VERSION ""

NS_ :

BS_:

BU_: AFLS CUbiS SAS SCC ACU ECS IPM LCA MDPS SMK SPAS ESC FPCM LDWS ODS SNV TCU TESTER TMU OPI RPAS YRS ABS DATC LKAS AAF EMS ISS REA _4WD CLU DI_BOX EHPS EPB EVP HUD LVR PSB_RH TPMS AHLS FATC LPI PAS PSB_LH AEMC AVM BCM CLOCK E_Shifter ISG MTC MTS PGS PSB TCS AAF_Tester LDWS_Test_Tool

BO_ 2015 GST1: 8 TESTER
 SG_ REQ_RESPONSE : 16|8@1+ (1,0) [0|2] ""  _4WD,AAF,ABS,ACU,AEMC,AFLS,AHLS,AVM,BCM,CLOCK,CLU,CUbiS,DATC,DI_BOX,ECS,EHPS,EMS,EPB,ESC,EVP,E_Shifter,FATC,IPM,ISG,ISS,LCA,LDWS,LKAS,LPI,LVR,MDPS,MTC,MTS,ODS,OPI,PAS,PGS,PSB,PSB_LH,PSB_RH,REA,RPAS,SAS,SCC,SMK,SNV,SPAS,TCS,TCU,TMU,TPMS,YRS
 SG_ SID : 8|8@1+ (1,0) [0|255] ""  _4WD,AAF,ABS,ACU,AEMC,AFLS,AHLS,AVM,BCM,CLOCK,CLU,CUbiS,DATC,DI_BOX,ECS,EHPS,EMS,EPB,ESC,EVP,E_Shifter,FATC,IPM,ISG,ISS,LCA,LDWS,LKAS,LPI,LVR,MDPS,MTC,MTS,ODS,OPI,PAS,PGS,PSB,PSB_LH,PSB_RH,REA,RPAS,SAS,SCC,SMK,SNV,SPAS,TCS,TCU,TMU,TPMS,YRS
 SG_ FRM_FORMAT : 0|8@1+ (1,0) [0|31] ""  _4WD,AAF,ABS,ACU,AEMC,AFLS,AHLS,AVM,BCM,CLOCK,CLU,CUbiS,DATC,DI_BOX,ECS,EHPS,EMS,EPB,ESC,EVP,E_Shifter,FATC,IPM,ISG,ISS,LCA,LDWS,LKAS,LPI,LVR,MDPS,MTC,MTS,ODS,OPI,PAS,PGS,PSB,PSB_LH,PSB_RH,REA,RPAS,SAS,SCC,SMK,SNV,SPAS,TCS,TCU,TMU,TPMS,YRS

BO_ 1984 CAL_SAS: 2 ESC
 SG_ CCW : 0|4@1+ (1,0) [0|15] ""  SAS
 SG_ SAS_CID : 4|11@1+ (1,0) [0|2047] ""  SAS

BO_ 1680 CLU2: 8 IPM
 SG_ IGN_SW : 0|3@1+ (1,0) [0|7] ""  ECS,EPB
 SG_ CF_Clu_FlexStrgModeSwi : 58|2@1+ (1,0) [0|3] ""  MDPS
 SG_ PIC_Lock : 10|3@1+ (1,0) [0|7] ""  ECS
 SG_ AST_DR_SW : 54|2@1+ (1,0) [0|3] ""  AVM
 SG_ DRV_DR_SW : 6|2@1+ (1,0) [0|3] ""  ECS,EPB,ESC,TCU
 SG_ PIC_Unlock : 13|3@1+ (1,0) [0|7] ""  ECS
 SG_ CF_HoodStat : 22|2@1+ (1,0) [0|3] ""  EMS,EPB
 SG_ CF_SWL_Stat : 45|3@1+ (1,0) [0|7] ""  ACU
 SG_ DRV_Key_Lock : 8|1@1+ (1,0) [0|1] ""  ECS
 SG_ DRV_Seat_Belt : 16|2@1+ (1,0) [0|3] ""  EPB,ESC,MTS,PSB_LH,PSB_RH,TCU,TMU
 SG_ PAS_Seat_Belt : 20|2@1+ (1,0) [0|3] ""  MTS,PSB_LH,PSB_RH,TMU
 SG_ DRV_Key_Unlock : 9|1@1+ (1,0) [0|1] ""  ECS
 SG_ CF_Clu_HazardSW : 49|1@1+ (1,0) [0|1] ""  ABS,EMS
 SG_ CF_Clu_SwiGearR : 43|2@1+ (1,0) [0|3] ""  EMS,EPB,SPAS
 SG_ CF_Clu_WiperLow : 31|1@1+ (1,0) [0|1] ""  LDWS,LKAS
 SG_ CF_Clu_AliveCnt2 : 50|4@1+ (1,0) [0|15] ""  EMS
 SG_ CF_Clu_TurnSigLh : 24|1@1+ (1,0) [0|1] ""  LDWS,LKAS
 SG_ CF_Clu_TurnSigRh : 25|1@1+ (1,0) [0|1] ""  LDWS,LKAS
 SG_ CF_Clu_WiperAuto : 33|1@1+ (1,0) [0|1] ""  LDWS,LKAS
 SG_ CF_Clu_WiperHigh : 32|1@1+ (1,0) [0|1] ""  LDWS,LKAS
 SG_ CF_Clu_WiperIntT : 27|3@1+ (1,0) [0|7] ""  LDWS,LKAS
 SG_ CF_Clu_AltLStatus : 39|1@1+ (1,0) [0|1] ""  DATC,FATC,MTC
 SG_ CF_Clu_LdwsLkasSW : 26|1@1+ (1,0) [0|1] ""  LDWS,LKAS
 SG_ CF_Clu_WiperIntSW : 30|1@1+ (1,0) [0|1] ""  LDWS,LKAS
 SG_ TRUNK_OPEN_STATUS : 18|2@1+ (1,0) [0|3] ""  AFLS,ECS
 SG_ CF_Clu_ActiveEcoSW : 48|1@1+ (1,0) [0|1] ""  DATC,FATC,MTC,TCU
 SG_ CF_Clu_EcoDriveInf : 40|3@1+ (1,0) [0|7] ""  CUbiS,MTS,TMU
 SG_ CF_Clu_HeadLampLow : 37|1@1+ (1,0) [0|1] ""  AFLS,EMS,LDWS
 SG_ CF_Clu_RainSnsStat : 34|3@1+ (1,0) [0|7] ""  LDWS,LKAS
 SG_ CF_Clu_HeadLampHigh : 38|1@1+ (1,0) [0|1] ""  EMS
 SG_ CF_Clu_LkasDispMode : 56|2@1+ (1,0) [0|3] ""  LKAS
 SG_ RKE_CMD : 3|3@1+ (1,0) [0|7] ""  ECS

BO_ 1616 AFLS: 2 AFLS
 SG_ CF_Afls_LedHLStat : 8|2@1+ (1,0) [0|3] ""  CLU
 SG_ AFLS_STAT : 1|2@1+ (1,0) [0|3] ""  CLU
 SG_ CF_Afls_TrfChgStat : 3|1@1+ (1,0) [0|1] ""  CLU

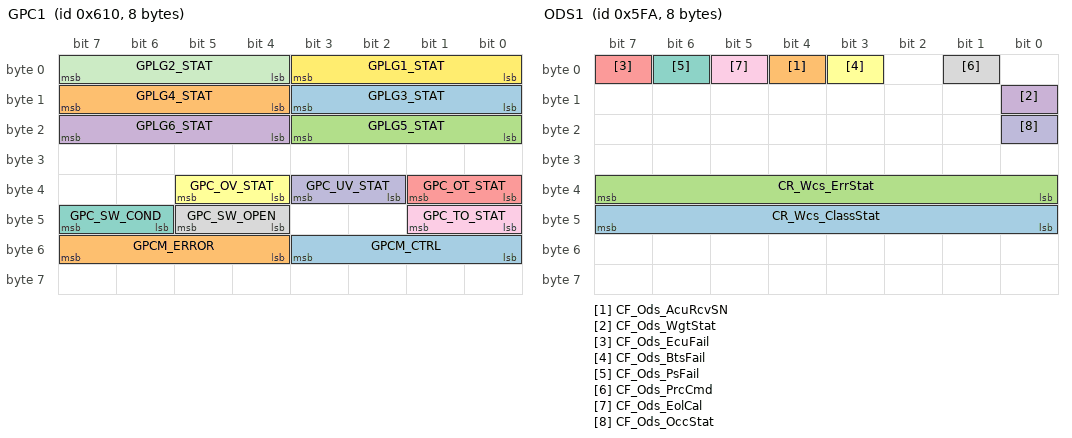
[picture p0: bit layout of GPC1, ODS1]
BO_ 1552 GPC1: 8 ISS
 SG_ GPLG3_STAT : 8|4@1+ (1,0) [0|15] ""  EMS
 SG_ GPLG4_STAT : 12|4@1+ (1,0) [0|15] ""  EMS
 SG_ GPLG5_STAT : 16|4@1+ (1,0) [0|15] ""  EMS
 SG_ GPLG6_STAT : 20|4@1+ (1,0) [0|15] ""  EMS
 SG_ GPC_OT_STAT : 32|2@1+ (1,0) [0|3] ""  EMS
 SG_ GPC_OV_STAT : 36|2@1+ (1,0) [0|3] ""  EMS
 SG_ GPC_SW_COND : 46|2@1+ (1,0) [0|3] ""  EMS
 SG_ GPC_SW_OPEN : 44|2@1+ (1,0) [0|3] ""  EMS
 SG_ GPC_TO_STAT : 40|2@1+ (1,0) [0|3] ""  EMS
 SG_ GPC_UV_STAT : 34|2@1+ (1,0) [0|3] ""  EMS
 SG_ GPLG2_STAT : 4|4@1+ (1,0) [0|15] ""  EMS
 SG_ GPLG1_STAT : 0|4@1+ (1,0) [0|15] ""  EMS
 SG_ GPCM_CTRL : 48|4@1+ (1,0) [0|15] ""  EMS
 SG_ GPCM_ERROR : 52|4@1+ (1,0) [0|15] ""  EMS

BO_ 1532 ODS3: 5 ODS
 SG_ CR_Ods_ID : 0|8@1+ (1,0) [0|255] ""  ACU
 SG_ CR_Ods_RomID_L : 32|8@1+ (1,0) [0|255] ""  ACU
 SG_ CR_Ods_RomID_H : 24|8@1+ (1,0) [0|255] ""  ACU
 SG_ CR_Ods_Chksum_H : 8|8@1+ (1,0) [0|255] ""  ACU
 SG_ CR_Ods_Chksum_L : 16|8@1+ (1,0) [0|255] ""  ACU

BO_ 1531 ODS2: 8 ODS
 SG_ CR_Ods_SerNum7 : 56|8@1+ (1,0) [0|255] ""  ACU
 SG_ CR_Ods_SerNum2 : 16|8@1+ (1,0) [0|255] ""  ACU
 SG_ CR_Ods_SerNum1 : 8|8@1+ (1,0) [0|255] ""  ACU
 SG_ CR_Ods_SerNum0 : 0|8@1+ (1,0) [0|255] ""  ACU
 SG_ CR_Ods_SerNum6 : 48|8@1+ (1,0) [0|255] ""  ACU
 SG_ CR_Ods_SerNum5 : 40|8@1+ (1,0) [0|255] ""  ACU
 SG_ CR_Ods_SerNum4 : 32|8@1+ (1,0) [0|255] ""  ACU
 SG_ CR_Ods_SerNum3 : 24|8@1+ (1,0) [0|255] ""  ACU

BO_ 1530 ODS1: 8 ODS
 SG_ CR_Wcs_ClassStat : 40|8@1+ (1,0) [0|4] ""  ACU
 SG_ CF_Ods_AcuRcvSN : 4|1@1+ (1,0) [0|1] ""  ACU
 SG_ CR_Wcs_ErrStat : 32|8@1+ (1,0) [0|63] ""  ACU
 SG_ CF_Ods_WgtStat : 8|1@1+ (1,0) [0|1] ""  ACU
 SG_ CF_Ods_EcuFail : 7|1@1+ (1,0) [0|1] ""  ACU
 SG_ CF_Ods_BtsFail : 3|1@1+ (1,0) [0|1] ""  ACU
 SG_ CF_Ods_PsFail : 6|1@1+ (1,0) [0|1] ""  ACU
 SG_ CF_Ods_PrcCmd : 1|1@1+ (1,0) [0|1] ""  ACU
 SG_ CF_Ods_EolCal : 5|1@1+ (1,0) [0|1] ""  ACU
 SG_ CF_Ods_OccStat : 16|1@1+ (1,0) [0|1] ""  ACU

BO_ 1524 PSB_RH: 2 PSB_RH
 SG_ PSB_RH_ACT : 3|1@1+ (1,0) [0|1] ""  SCC
 SG_ PSB_RH_TGL : 2|1@1+ (1,0) [0|1] ""  CLU
 SG_ PSB_RH_FAIL : 0|2@1+ (1,0) [0|3] ""  CLU

BO_ 1523 PSB_LH: 2 PSB_LH
 SG_ PSB_LH_ACT : 3|1@1+ (1,0) [0|1] ""  SCC
 SG_ PSB_LH_TGL : 2|1@1+ (1,0) [0|1] ""  CLU
 SG_ PSB_LH_FAIL : 0|2@1+ (1,0) [0|3] ""  CLU

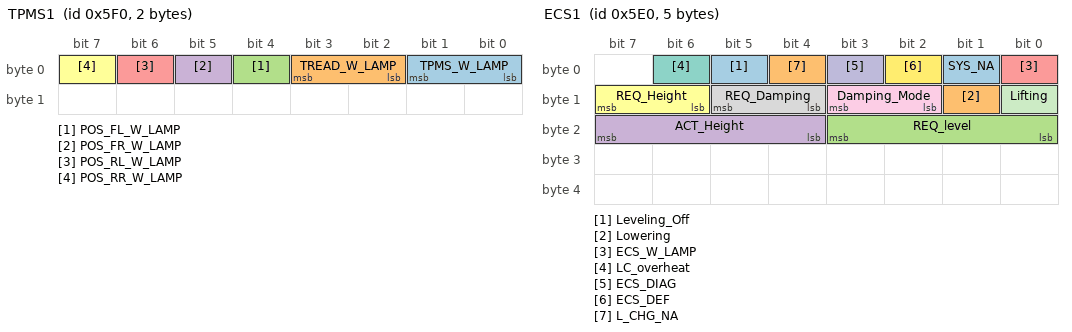
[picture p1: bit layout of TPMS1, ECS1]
BO_ 1520 TPMS1: 2 TPMS
 SG_ TPMS_W_LAMP : 0|2@1+ (1,0) [0|3] ""  CLU,CUbiS,MTS,TMU
 SG_ TREAD_W_LAMP : 2|2@1+ (1,0) [0|3] ""  CLU,CUbiS,TMU
 SG_ POS_FL_W_LAMP : 4|1@1+ (1,0) [0|1] ""  CLU,CUbiS,MTS,TMU
 SG_ POS_FR_W_LAMP : 5|1@1+ (1,0) [0|1] ""  CLU,CUbiS,MTS,TMU
 SG_ POS_RL_W_LAMP : 6|1@1+ (1,0) [0|1] ""  CLU,CUbiS,MTS,TMU
 SG_ POS_RR_W_LAMP : 7|1@1+ (1,0) [0|1] ""  CLU,CUbiS,MTS,TMU

BO_ 1508 MDPS1: 3 MDPS
 SG_ CF_Mdps_Flex : 8|3@1+ (1,0) [0|7] ""  CLU,LKAS
 SG_ CF_Mdps_FlexStat : 11|2@1+ (1,0) [0|3] ""  CLU,LKAS
 SG_ CF_Mdps_FlexDisp : 11|1@1+ (1,0) [0|1] ""  CLU
 SG_ CF_Mdps_WLmp : 1|2@1+ (1,0) [0|3] ""  CLU,CUbiS,EMS,SPAS,TMU

BO_ 1504 ECS1: 5 ECS
 SG_ Leveling_Off : 5|1@1+ (1,0) [0|1] ""  CLU,IPM
 SG_ Lowering : 9|1@1+ (1,0) [0|1] ""  CLU,IPM
 SG_ REQ_level : 16|4@1+ (1,0) [0|15] ""  CLU
 SG_ ACT_Height : 20|4@1+ (1,0) [0|15] ""  CLU,IPM
 SG_ ECS_W_LAMP : 0|1@1+ (1,0) [0|1] ""  CLU,CUbiS,MTS,TMU
 SG_ REQ_Height : 14|2@1+ (1,0) [0|3] ""  CLU,IPM
 SG_ LC_overheat : 6|1@1+ (1,0) [0|1] ""  CLU,IPM
 SG_ REQ_Damping : 12|2@1+ (1,0) [0|3] ""  CLU,IPM
 SG_ Damping_Mode : 10|2@1+ (1,0) [0|3] ""  CLU,IPM
 SG_ ECS_DIAG : 3|1@1+ (1,0) [0|1] ""  CLU
 SG_ Lifting : 8|1@1+ (1,0) [0|1] ""  CLU,IPM
 SG_ ECS_DEF : 2|1@1+ (1,0) [0|1] ""  CLU,IPM
 SG_ SYS_NA : 1|1@1+ (1,0) [0|1] ""  CLU,IPM
 SG_ L_CHG_NA : 4|1@1+ (1,0) [0|1] ""  CLU,IPM

BO_ 1461 SCC2: 8 SCC
 SG_ ACC_ObjDist : 17|11@1+ (0.1,0) [0|204.7] "m"  ABS,ESC,PSB_LH,PSB_RH
 SG_ ACC_ObjStatus : 0|2@1+ (1,0) [0|3] ""  ABS,ESC,PSB_LH,PSB_RH
 SG_ ACC_ObjRelSpd : 28|12@1+ (0.1,-170) [-170|239.5] "m/s"  ABS,ESC,PSB_LH,PSB_RH
 SG_ ACC_ObjLatPos : 8|9@1+ (0.1,-20) [-20|31.1] "m"  ABS,ESC,PSB_LH,PSB_RH

BO_ 1442 ACU5: 4 ACU
 SG_ CF_Acu_ExtOfSab : 4|2@1+ (1,0) [0|3] ""  CLU,CUbiS,IPM,TMU
 SG_ CF_Acu_FltStat : 2|2@1+ (1,0) [0|3] ""  CUbiS,MTS,TMU
 SG_ CF_SWL_Ind : 0|2@1+ (1,0) [0|3] ""  CUbiS,MTS,TMU
 SG_ CF_Acu_Dtc : 8|16@1+ (1,0) [0|65535] ""  CUbiS,MTS,TMU
 SG_ CF_Acu_NumOfFlt : 24|8@1+ (1,0) [0|255] ""  CUbiS,MTS,TMU

BO_ 1441 ACU2: 8 ACU
 SG_ CR_Acu_SN : 0|64@1+ (1,0) [0|0] ""  ODS

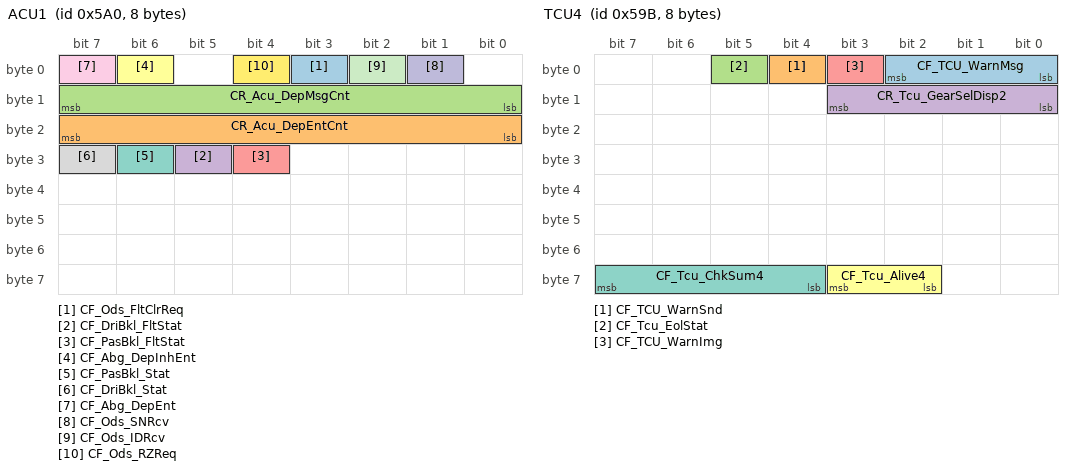
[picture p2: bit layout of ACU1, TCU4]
BO_ 1440 ACU1: 8 ACU
 SG_ CF_Ods_FltClrReq : 3|1@1+ (1,0) [0|1] ""  ODS
 SG_ CR_Acu_DepEntCnt : 16|8@1+ (1,0) [0|14] ""  ODS
 SG_ CR_Acu_DepMsgCnt : 8|8@1+ (1,0) [0|50] ""  ODS
 SG_ CF_DriBkl_FltStat : 29|1@1+ (1,0) [0|1] ""  CLU,ODS,PSB_LH,PSB_RH
 SG_ CF_PasBkl_FltStat : 28|1@1+ (1,0) [0|1] ""  CLU,ODS,PSB_LH,PSB_RH
 SG_ CF_Abg_DepInhEnt : 6|1@1+ (1,0) [0|1] ""  ODS
 SG_ CF_PasBkl_Stat : 30|1@1+ (1,0) [0|1] ""  CLU,ODS,PSB_LH,PSB_RH
 SG_ CF_DriBkl_Stat : 31|1@1+ (1,0) [0|1] ""  CLU,ODS,PSB_LH,PSB_RH
 SG_ CF_Abg_DepEnt : 7|1@1+ (1,0) [0|1] ""  ODS
 SG_ CF_Ods_SNRcv : 1|1@1+ (1,0) [0|1] ""  ODS
 SG_ CF_Ods_IDRcv : 2|1@1+ (1,0) [0|1] ""  ODS
 SG_ CF_Ods_RZReq : 4|1@1+ (1,0) [0|1] ""  ODS

BO_ 1437 AHLS1: 8 AHLS
 SG_ CF_Ahls_WarnMsg : 2|2@1+ (1,0) [0|3] ""  CLU
 SG_ CF_Ahls_WarnLamp : 0|2@1+ (1,0) [0|3] ""  CLU

BO_ 1435 TCU4: 8 TCU
 SG_ CF_TCU_WarnMsg : 0|3@1+ (1,0) [0|7] ""  CLU
 SG_ CF_TCU_WarnSnd : 4|1@1+ (1,0) [0|1] ""  CLU
 SG_ CF_Tcu_EolStat : 5|1@1+ (1,0) [0|1] ""  LVR
 SG_ CR_Tcu_GearSelDisp2 : 8|4@1+ (1,0) [0|15] ""  EMS
 SG_ CF_TCU_WarnImg : 3|1@1+ (1,0) [0|1] ""  CLU
 SG_ CF_Tcu_Alive4 : 58|2@1+ (1,0) [0|3] ""  EMS
 SG_ CF_Tcu_ChkSum4 : 60|4@1+ (1,0) [0|15] ""  EMS

BO_ 1419 LCA1: 8 LCA
 SG_ CF_Lca_IndRight : 16|4@1+ (1,0) [0|15] ""  IPM
 SG_ CF_Lca_IndLeft : 8|4@1+ (1,0) [0|15] ""  IPM
 SG_ CF_Lca_Stat : 0|4@1+ (1,0) [0|15] ""  IPM
 SG_ CF_Lca_IndBriRight : 32|8@1+ (1,0) [0|255] ""  IPM
 SG_ CF_Lca_IndBriLeft : 24|8@1+ (1,0) [0|255] ""  IPM

BO_ 1417 EHPS1: 2 EHPS
 SG_ CF_Ehps_StrMode : 2|2@1+ (1,0) [0|3] ""  CLU
 SG_ CF_Ehps_Warn : 0|2@1+ (1,0) [0|3] ""  CLU

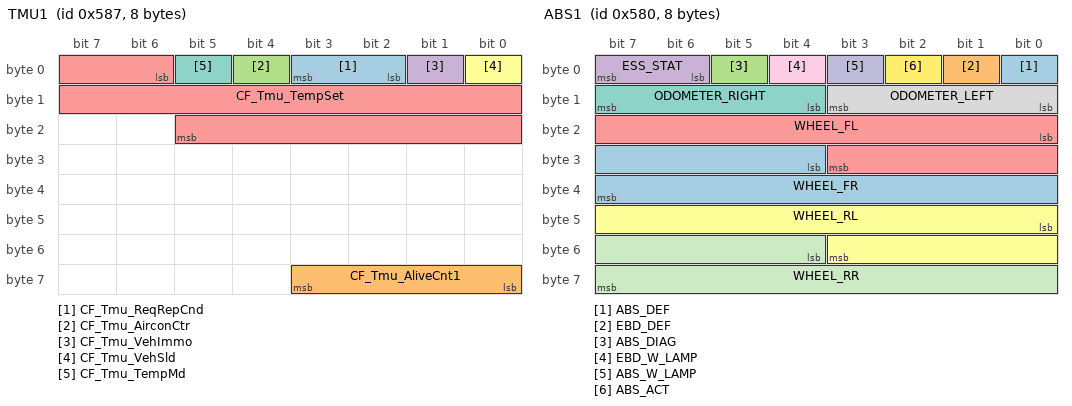
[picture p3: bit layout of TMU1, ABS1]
BO_ 1415 TMU1: 8 TMU
 SG_ CF_Tmu_ReqRepCnd : 2|2@1+ (1,0) [0|3] ""  EMS
 SG_ CF_Tmu_AliveCnt1 : 56|4@1+ (1,0) [0|15] ""  EMS
 SG_ CF_Tmu_AirconCtr : 4|1@1+ (1,0) [0|1] ""  FATC
 SG_ CF_Tmu_VehImmo : 1|1@1+ (1,0) [0|1] ""  EMS
 SG_ CF_Tmu_TempSet : 6|16@1+ (1,0) [0|20] ""  FATC
 SG_ CF_Tmu_VehSld : 0|1@1+ (1,0) [0|1] ""  EMS
 SG_ CF_Tmu_TempMd : 5|1@1+ (1,0) [0|1] ""  FATC

BO_ 1414 EVP1: 3 EVP
 SG_ CF_Evp_Stat : 0|1@1+ (1,0) [0|1] ""  CLU

BO_ 1412 AAF1: 8 AAF
 SG_ CF_Aaf_MilOnReq : 42|1@1+ (1,0) [0|1] ""  EMS
 SG_ CF_Aaf_WrnLamp : 5|1@1+ (1,0) [0|1] ""  CLU
 SG_ CF_Aaf_PStatus : 24|8@1+ (1,0) [0|100] "%"  AAF_Tester
 SG_ CF_Aaf_ErrStatus : 6|10@1+ (1,0) [0|1023] ""  AAF_Tester
 SG_ CF_Aaf_SolFlapStatus : 40|2@1+ (1,0) [0|3] ""  AAF_Tester
 SG_ CF_Aaf_ActFlapStatus : 0|2@1+ (1,0) [0|3] ""  AAF_Tester
 SG_ CF_Aaf_OpenRqSysSol : 32|8@1+ (1,0) [0|255] ""  AAF_Tester
 SG_ CF_Aaf_OpenRqSysAct : 16|8@1+ (1,0) [0|255] ""  AAF_Tester
 SG_ CF_Aaf_ModeStatus : 2|3@1+ (1,0) [0|7] ""  AAF_Tester

BO_ 1411 CUbiS1: 8 CUbiS
 SG_ CF_Cubis_HUDisp : 0|4@1+ (1,0) [0|15] ""  CLU

BO_ 1408 ABS1: 8 ABS
 SG_ ABS_DEF : 0|1@1+ (1,0) [0|1] ""  _4WD,ACU,EMS,SPAS,TCU
 SG_ EBD_DEF : 1|1@1+ (1,0) [0|1] ""  _4WD,EMS,SPAS,TCU
 SG_ ABS_DIAG : 5|1@1+ (1,0) [0|1] ""  _4WD,CLU
 SG_ ESS_STAT : 6|2@1+ (1,0) [0|3] ""  _4WD,CLU,EMS
 SG_ WHEEL_FL : 16|12@1+ (0.125,0) [0|511.875] "km/h"  _4WD,AVM,CLU,CUbiS,EMS,EPB,PGS,SMK,SPAS,TCU,TMU
 SG_ WHEEL_RL : 40|12@1+ (0.125,0) [0|511.875] "km/h"  _4WD,AVM,CLU,CUbiS,EMS,EPB,PGS,SMK,SPAS,TCU,TMU
 SG_ ODOMETER_RIGHT : 12|4@1+ (1,0) [0|15] "m"  _4WD,CLU
 SG_ ODOMETER_LEFT : 8|4@1+ (1,0) [0|15] "m"  _4WD,CLU
 SG_ EBD_W_LAMP : 4|1@1+ (1,0) [0|1] ""  _4WD,CLU
 SG_ ABS_W_LAMP : 3|1@1+ (1,0) [0|1] ""  _4WD,CLU,CUbiS,MTS,TMU
 SG_ WHEEL_RR : 52|12@1+ (0.125,0) [0|511.875] "km/h"  _4WD,AVM,CLU,CUbiS,EMS,EPB,PGS,SMK,SPAS,TCU,TMU
 SG_ ABS_ACT : 2|1@1+ (1,0) [0|1] ""  _4WD,ACU,EPB,SPAS,TCU
 SG_ WHEEL_FR : 28|12@1+ (0.125,0) [0|511.875] "km/h"  _4WD,AVM,CLU,CUbiS,EMS,EPB,PGS,SMK,SPAS,TCU,TMU

BO_ 1378 HUD1: 4 HUD
 SG_ CF_Hud_Brightness : 5|5@1+ (1,0) [0|31] ""  CLU
 SG_ CF_Hud_HeightStaus : 0|5@1+ (1,0) [0|31] ""  CLU

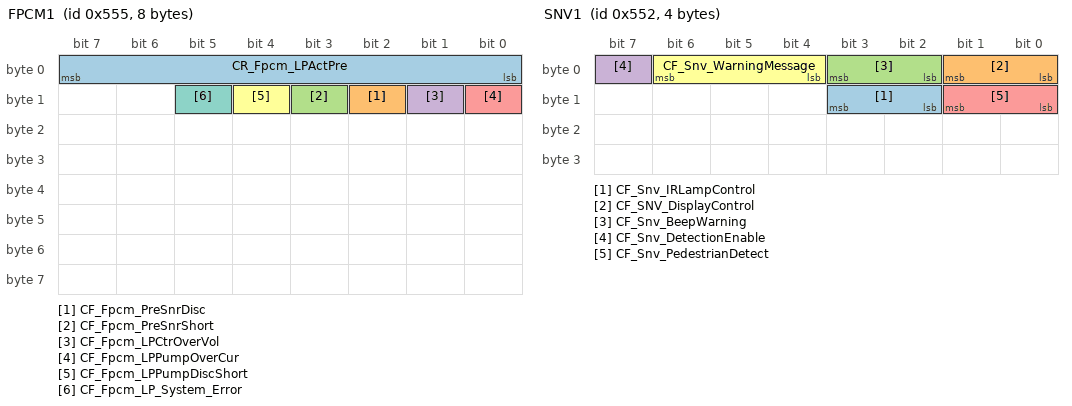
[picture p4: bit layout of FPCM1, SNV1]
BO_ 1365 FPCM1: 8 FPCM
 SG_ CR_Fpcm_LPActPre : 0|8@1+ (3.137254902,0) [0|800] "kPa"  EMS
 SG_ CF_Fpcm_PreSnrDisc : 10|1@1+ (1,0) [0|1] ""  EMS
 SG_ CF_Fpcm_PreSnrShort : 11|1@1+ (1,0) [0|1] ""  EMS
 SG_ CF_Fpcm_LPCtrOverVol : 9|1@1+ (1,0) [0|1] ""  EMS
 SG_ CF_Fpcm_LPPumpOverCur : 8|1@1+ (1,0) [0|1] ""  EMS
 SG_ CF_Fpcm_LPPumpDiscShort : 12|1@1+ (1,0) [0|1] ""  EMS
 SG_ CF_Fpcm_LP_System_Error : 13|1@1+ (1,0) [0|1] ""  EMS

BO_ 1362 SNV1: 4 SNV
 SG_ CF_Snv_IRLampControl : 10|2@1+ (1,0) [0|3] ""  CLU
 SG_ CF_SNV_DisplayControl : 0|2@1+ (1,0) [0|3] ""  CLU
 SG_ CF_Snv_BeepWarning : 2|2@1+ (1,0) [0|3] ""  CLU
 SG_ CF_Snv_DetectionEnable : 7|1@1+ (1,0) [0|1] ""  CLU
 SG_ CF_Snv_PedestrianDetect : 8|2@1+ (1,0) [0|3] ""  CLU
 SG_ CF_Snv_WarningMessage : 4|3@1+ (1,0) [0|7] ""  CLU

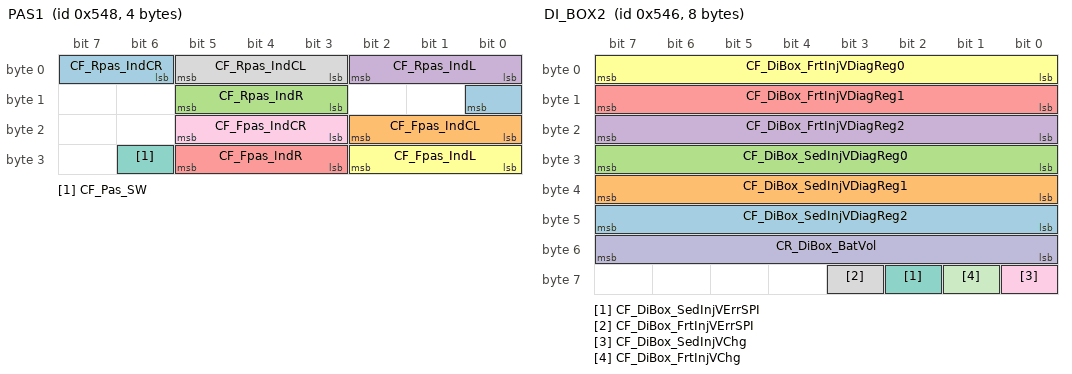
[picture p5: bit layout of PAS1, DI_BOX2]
BO_ 1352 PAS1: 4 RPAS
 SG_ CF_Rpas_IndCR : 6|3@1+ (1,0) [0|7] ""  CLU
 SG_ CF_Fpas_IndCL : 16|3@1+ (1,0) [0|7] ""  CLU
 SG_ CF_Rpas_IndR : 11|3@1+ (1,0) [0|7] ""  CLU
 SG_ CF_Rpas_IndL : 0|3@1+ (1,0) [0|7] ""  CLU
 SG_ CF_Fpas_IndR : 27|3@1+ (1,0) [0|7] ""  CLU
 SG_ CF_Fpas_IndL : 24|3@1+ (1,0) [0|7] ""  CLU
 SG_ CF_Pas_SW : 30|1@1+ (1,0) [0|1] ""  CLU
 SG_ CF_Rpas_IndCL : 3|3@1+ (1,0) [0|7] ""  CLU
 SG_ CF_Fpas_IndCR : 19|3@1+ (1,0) [0|7] ""  CLU

BO_ 1350 DI_BOX2: 8 DI_BOX
 SG_ CF_DiBox_SedInjVDiagReg2 : 40|8@1+ (1,0) [0|255] ""  EMS
 SG_ CF_DiBox_SedInjVDiagReg1 : 32|8@1+ (1,0) [0|255] ""  EMS
 SG_ CF_DiBox_SedInjVDiagReg0 : 24|8@1+ (1,0) [0|255] ""  EMS
 SG_ CF_DiBox_FrtInjVDiagReg2 : 16|8@1+ (1,0) [0|255] ""  EMS
 SG_ CF_DiBox_FrtInjVDiagReg1 : 8|8@1+ (1,0) [0|255] ""  EMS
 SG_ CF_DiBox_FrtInjVDiagReg0 : 0|8@1+ (1,0) [0|255] ""  EMS
 SG_ CF_DiBox_SedInjVErrSPI : 58|1@1+ (1,0) [0|1] ""  EMS
 SG_ CF_DiBox_FrtInjVErrSPI : 59|1@1+ (1,0) [0|1] ""  EMS
 SG_ CF_DiBox_SedInjVChg : 56|1@1+ (1,0) [0|1] ""  EMS
 SG_ CR_DiBox_BatVol : 48|8@1+ (0.1,0) [0|25.5] "V"  EMS
 SG_ CF_DiBox_FrtInjVChg : 57|1@1+ (1,0) [0|1] ""  EMS

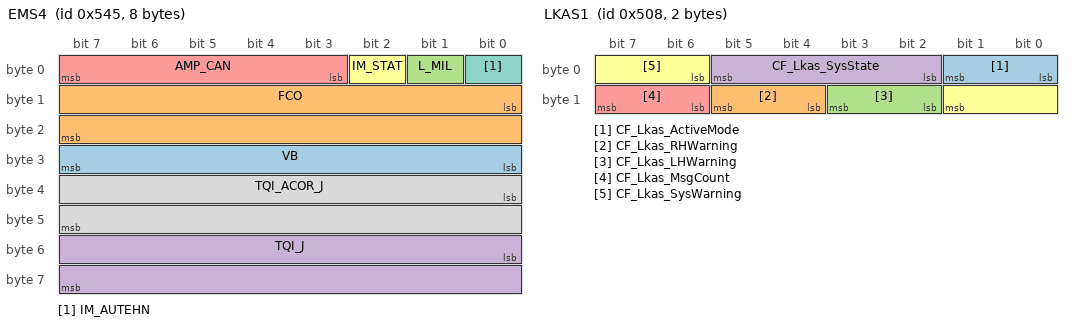
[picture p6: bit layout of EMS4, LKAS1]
BO_ 1349 EMS4: 8 EMS
 SG_ VB : 24|8@1+ (0.1015625,0) [0|25.8984375] "V"  CUbiS,DATC,EPB,FATC,MTC,MTS,TMU
 SG_ FCO : 8|16@1+ (0.128,0) [0|8388.48] "ul"  CLU,CUbiS,MTS,TMU
 SG_ L_MIL : 1|1@1+ (1,0) [0|1] ""  CLU,CUbiS,MTS,TMU
 SG_ TQI_J : 48|16@1- (0.1,0) [-3276.8|3276.7] "Nm"  TCU
 SG_ AMP_CAN : 3|5@1+ (10.731613,458.98) [458.98|791.660003] "mmHg"  TCU
 SG_ IM_STAT : 2|1@1+ (1,0) [0|1] ""  CLU
 SG_ IM_AUTEHN : 0|1@1+ (1,0) [0|1] ""  CLU
 SG_ TQI_ACOR_J : 32|16@1- (0.1,0) [-3276.8|3276.7] "Nm"  TCU

BO_ 1296 GWAY9: 8 IPM
 SG_ CF_Gway_PasSys : 44|2@1+ (1,0) [0|3] ""  CLU
 SG_ CF_Gway_PasAlarm_Spkr_Rcnt : 30|2@1+ (1,0) [0|3] ""  CLU
 SG_ CF_Gway_PasIndFC : 38|3@1+ (1,0) [0|7] ""  CLU
 SG_ CF_Gway_PasIndRC : 41|3@1+ (1,0) [0|7] ""  CLU
 SG_ CF_Gway_PasIndFIL : 8|3@1+ (1,0) [0|7] ""  AVM,CLU
 SG_ CF_Gway_PasIndFIR : 11|3@1+ (1,0) [0|7] ""  AVM,CLU
 SG_ CF_Gway_PasIndFOL : 0|3@1+ (1,0) [0|7] ""  AVM,CLU
 SG_ CF_Gway_PasIndFOR : 3|3@1+ (1,0) [0|7] ""  AVM,CLU
 SG_ CF_Gway_PasIndRIL : 24|3@1+ (1,0) [0|7] ""  AVM,CLU
 SG_ CF_Gway_PasIndRIR : 27|3@1+ (1,0) [0|7] ""  AVM,CLU
 SG_ CF_Gway_PasIndROL : 16|3@1+ (1,0) [0|7] ""  AVM,CLU
 SG_ CF_Gway_PasIndROR : 19|3@1+ (1,0) [0|7] ""  AVM,CLU
 SG_ CF_Gway_PasAlarmFR : 32|2@1+ (1,0) [0|3] ""  CLU
 SG_ CF_Gway_PasAlarmRR : 34|2@1+ (1,0) [0|3] ""  CLU
 SG_ CF_Gway_PasBeepAlarm : 36|2@1+ (1,0) [0|3] ""  CLU
 SG_ CF_Gway_PasAlarm_Spkr_Flh : 48|2@1+ (1,0) [0|3] ""  CLU
 SG_ CF_Gway_PasAlarm_Spkr_Frh : 46|2@1+ (1,0) [0|3] ""  CLU
 SG_ CF_Gway_PasAlarm_Spkr_Rlh : 22|2@1+ (1,0) [0|3] ""  CLU
 SG_ CF_Gway_PasAlarm_Spkr_Rrh : 14|2@1+ (1,0) [0|3] ""  CLU
 SG_ CF_Gway_PasAlarm_Spkr_Fcnt : 50|2@1+ (1,0) [0|3] ""  CLU
 SG_ CF_Gway_PasDisp : 6|2@1+ (1,0) [0|3] ""  CLU

BO_ 1288 LKAS1: 2 LKAS
 SG_ CF_Lkas_ActiveMode : 0|2@1+ (1,0) [0|3] ""  CLU
 SG_ CF_Lkas_RHWarning : 12|2@1+ (1,0) [0|3] ""  CLU,IPM
 SG_ CF_Lkas_LHWarning : 10|2@1+ (1,0) [0|3] ""  CLU,IPM
 SG_ CF_Lkas_SysState : 2|4@1+ (1,0) [0|15] ""  CLU
 SG_ CF_Lkas_MsgCount : 14|2@1+ (1,0) [0|3] ""  CLU,IPM
 SG_ CF_Lkas_SysWarning : 6|4@1+ (1,0) [0|15] ""  CLU,IPM

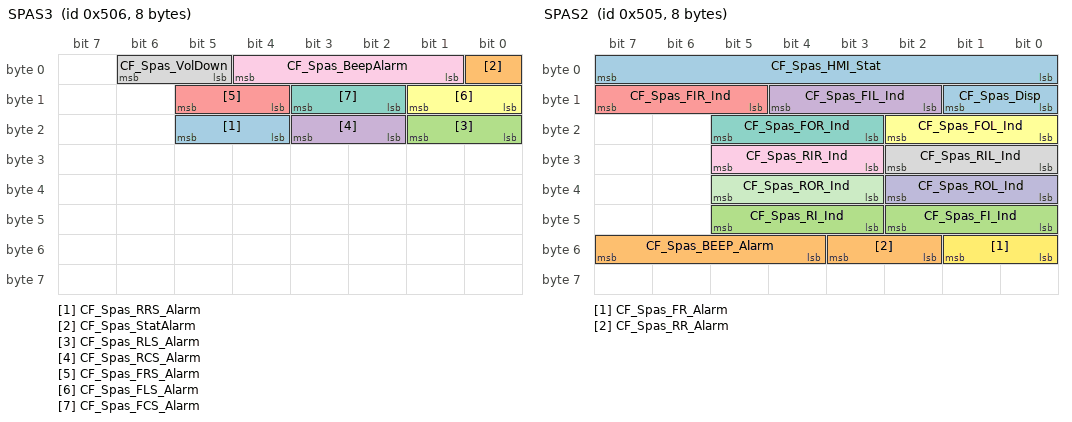
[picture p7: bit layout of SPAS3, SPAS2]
BO_ 1286 SPAS3: 8 SPAS
 SG_ CF_Spas_RRS_Alarm : 20|2@1+ (1,0) [0|3] ""  CLU,IPM
 SG_ CF_Spas_StatAlarm : 0|1@1+ (1,0) [0|1] ""  CLU,IPM
 SG_ CF_Spas_RLS_Alarm : 16|2@1+ (1,0) [0|3] ""  CLU,IPM
 SG_ CF_Spas_RCS_Alarm : 18|2@1+ (1,0) [0|3] ""  CLU,IPM
 SG_ CF_Spas_FRS_Alarm : 12|2@1+ (1,0) [0|3] ""  CLU,IPM
 SG_ CF_Spas_FLS_Alarm : 8|2@1+ (1,0) [0|3] ""  CLU,IPM
 SG_ CF_Spas_FCS_Alarm : 10|2@1+ (1,0) [0|3] ""  CLU,IPM
 SG_ CF_Spas_VolDown : 5|2@1+ (1,0) [0|3] ""  CLU,IPM
 SG_ CF_Spas_BeepAlarm : 1|4@1+ (1,0) [0|15] ""  CLU,IPM

BO_ 1285 SPAS2: 8 SPAS
 SG_ CF_Spas_Disp : 8|2@1+ (1,0) [0|3] ""  CLU
 SG_ CF_Spas_BEEP_Alarm : 52|4@1+ (1,0) [0|15] ""  CLU,IPM
 SG_ CF_Spas_RI_Ind : 43|3@1+ (1,0) [0|7] ""  AVM,CLU
 SG_ CF_Spas_FIL_Ind : 10|3@1+ (1,0) [0|7] ""  AVM,CLU
 SG_ CF_Spas_FIR_Ind : 13|3@1+ (1,0) [0|7] ""  AVM,CLU
 SG_ CF_Spas_FOL_Ind : 16|3@1+ (1,0) [0|7] ""  AVM,CLU
 SG_ CF_Spas_FOR_Ind : 19|3@1+ (1,0) [0|7] ""  AVM,CLU
 SG_ CF_Spas_RIL_Ind : 24|3@1+ (1,0) [0|7] ""  AVM,CLU
 SG_ CF_Spas_RIR_Ind : 27|3@1+ (1,0) [0|7] ""  AVM,CLU
 SG_ CF_Spas_ROL_Ind : 32|3@1+ (1,0) [0|7] ""  AVM,CLU
 SG_ CF_Spas_ROR_Ind : 35|3@1+ (1,0) [0|7] ""  AVM,CLU
 SG_ CF_Spas_FR_Alarm : 48|2@1+ (1,0) [0|3] ""  CLU,IPM
 SG_ CF_Spas_HMI_Stat : 0|8@1+ (1,0) [0|255] ""  CLU
 SG_ CF_Spas_RR_Alarm : 50|2@1+ (1,0) [0|3] ""  CLU,IPM
 SG_ CF_Spas_FI_Ind : 40|3@1+ (1,0) [0|7] ""  AVM,CLU

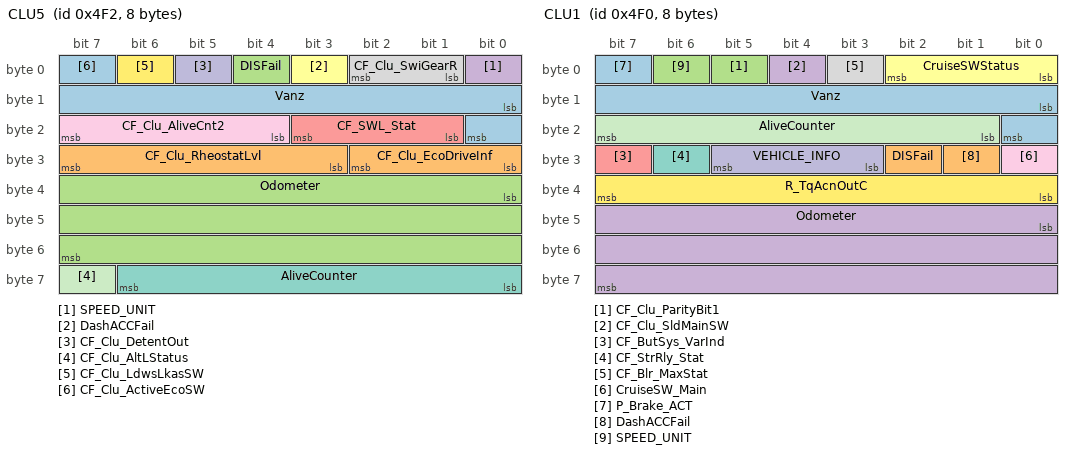
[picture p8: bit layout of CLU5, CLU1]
BO_ 1266 CLU5: 8 CLU
 SG_ Vanz : 8|9@1+ (0.5,0) [0|255.5] ""  IPM
 SG_ CF_Clu_RheostatLvl : 27|5@1+ (1,0) [0|31] ""  AVM,IPM,PGS
 SG_ Odometer : 32|24@1+ (0.1,0) [0|1677721.5] "km"  IPM
 SG_ SPEED_UNIT : 0|1@1+ (1,0) [0|1] ""  IPM
 SG_ CF_SWL_Stat : 17|3@1+ (1,0) [0|7] ""  IPM
 SG_ DashACCFail : 3|1@1+ (1,0) [0|1] ""  IPM
 SG_ AliveCounter : 56|7@1+ (1,0) [0|127] ""  IPM
 SG_ CF_Clu_SwiGearR : 1|2@1+ (1,0) [0|3] ""  IPM
 SG_ CF_Clu_AliveCnt2 : 20|4@1+ (1,0) [0|15] ""  IPM
 SG_ CF_Clu_DetentOut : 5|1@1+ (1,0) [0|1] ""  AVM,IPM,PGS
 SG_ CF_Clu_AltLStatus : 63|1@1+ (1,0) [0|1] ""  IPM
 SG_ CF_Clu_LdwsLkasSW : 6|1@1+ (1,0) [0|1] ""  IPM
 SG_ CF_Clu_ActiveEcoSW : 7|1@1+ (1,0) [0|1] ""  IPM
 SG_ CF_Clu_EcoDriveInf : 24|3@1+ (1,0) [0|7] ""  IPM
 SG_ DISFail : 4|1@1+ (1,0) [0|1] ""  IPM

BO_ 1265 CLU3: 8 CLU
 SG_ CF_Clu_HudTbtSet : 43|1@1+ (1,0) [0|1] ""  HUD
 SG_ CF_Clu_RefDetMod : 2|1@1+ (1,0) [0|1] ""  TMU
 SG_ CF_Clu_ALightStat : 20|1@1+ (1,0) [0|1] ""  AFLS
 SG_ CF_Clu_AcnCltEnRq : 1|1@1+ (1,0) [0|1] ""  EMS
 SG_ CF_Clu_FxSteerCur : 38|2@1+ (1,0) [0|3] ""  MDPS
 SG_ CF_Clu_FxSteerVty : 37|1@1+ (1,0) [0|1] ""  MDPS
 SG_ CF_Clu_HudLdwsSet : 45|1@1+ (1,0) [0|1] ""  HUD
 SG_ CF_Clu_InstantFCU : 3|2@1+ (1,0) [0|3] ""  TMU
 SG_ CR_Clu_InstantFCI : 6|10@1+ (0.1,0) [0|102.3] ""  TMU
 SG_ CF_Clu_DefoggerRly : 5|1@1+ (1,0) [0|1] ""  EMS
 SG_ CF_Clu_FlexSteerSW : 40|1@1+ (1,0) [0|1] ""  MDPS
 SG_ CF_Clu_HudFontSize : 47|2@1+ (1,0) [0|3] ""  HUD
 SG_ CF_Clu_HudSpeedset : 42|1@1+ (1,0) [0|1] ""  HUD
 SG_ CF_Clu_LowfuelWarn : 16|2@1+ (1,0) [0|3] ""  IPM,TMU
 SG_ CF_Clu_TrailerMode : 24|1@1+ (1,0) [0|1] ""  SPAS
 SG_ CF_Clu_HeadLampTail : 23|1@1+ (1,0) [0|1] ""  SPAS
 SG_ CF_Clu_HudBrightSet : 51|2@1+ (1,0) [0|3] ""  HUD
 SG_ CF_Clu_HudFontColor : 49|2@1+ (1,0) [0|3] ""  HUD
 SG_ CF_Clu_HudHeightSet : 53|2@1+ (1,0) [0|3] ""  HUD
 SG_ CF_Clu_SportsModeSwi : 18|2@1+ (1,0) [0|3] ""  ECS,EMS,MDPS,TCU
 SG_ CF_Clu_DTE : 25|10@1+ (1,0) [0|1023] ""  DATC,FATC
 SG_ CF_Clu_Detent : 22|1@1+ (1,0) [0|1] ""  SPAS
 SG_ CF_Clu_FrtFog : 21|1@1+ (1,0) [0|1] ""  AFLS,LDWS,LKAS
 SG_ CF_Clu_AvsmCur : 41|1@1+ (1,0) [0|1] ""  ESC,SCC
 SG_ CF_Clu_CluInfo : 55|1@1+ (1,0) [0|1] ""  IPM
 SG_ CF_Clu_AcnRqSwi : 0|1@1+ (1,0) [0|1] ""  EMS
 SG_ CF_Clu_TripUnit : 35|2@1+ (1,0) [0|3] ""  DATC,FATC
 SG_ CF_Clu_HudDisSet : 46|1@1+ (1,0) [0|1] ""  HUD
 SG_ CF_Clu_HudSccSet : 44|1@1+ (1,0) [0|1] ""  HUD

BO_ 1264 CLU1: 8 IPM
 SG_ Vanz : 8|9@1+ (1,0) [0|255.5] "km/h or MPH"  CUbiS,LDWS,SCC
 SG_ DISFail : 26|1@1+ (1,0) [0|1] ""  SCC
 SG_ CF_Clu_ParityBit1 : 5|1@1+ (1,0) [0|1] "pulse count"  EMS
 SG_ CF_Clu_SldMainSW : 4|1@1+ (1,0) [0|1] ""  EMS
 SG_ CF_ButSys_VarInd : 31|1@1+ (1,0) [0|1] ""  EMS
 SG_ CruiseSWStatus : 0|3@1+ (1,0) [0|7] ""  EMS,SCC
 SG_ CF_StrRly_Stat : 30|1@1+ (1,0) [0|1] ""  EMS
 SG_ CF_Blr_MaxStat : 3|1@1+ (1,0) [0|1] ""  EMS
 SG_ CruiseSW_Main : 24|1@1+ (1,0) [0|1] ""  EMS,SCC
 SG_ VEHICLE_INFO : 27|3@1+ (1,0) [0|7] ""  ESC,SCC
 SG_ AliveCounter : 17|7@1+ (1,0) [0|127] ""  EPB,SCC
 SG_ R_TqAcnOutC : 32|8@1+ (1,0) [0|51] "Nm"  EMS
 SG_ P_Brake_ACT : 7|1@1+ (1,0) [0|1] ""  ESC,SCC
 SG_ DashACCFail : 25|1@1+ (1,0) [0|1] ""  SCC
 SG_ SPEED_UNIT : 6|1@1+ (1,0) [0|1] ""  CUbiS,LDWS,SCC
 SG_ Odometer : 40|24@1+ (0.1,0) [0|1677721.5] "km"  CUbiS,EPB,MTS,SCC,TMU

BO_ 1232 TCS4: 4 ESC
 SG_ _4WD_OPEN : 0|2@1+ (1,0) [0|3] ""  _4WD
 SG_ _4WD_CLU_LIM : 24|8@1+ (0.390625,0) [0|99.609375] "%"  _4WD
 SG_ _4WD_LIM_MODE : 3|1@1+ (1,0) [0|1] ""  _4WD
 SG_ _4WD_TQC_LIM : 8|16@1+ (1,0) [0|65535] "Nm"  _4WD
 SG_ _4WD_LIM_REQ : 2|1@1+ (1,0) [0|1] ""  _4WD

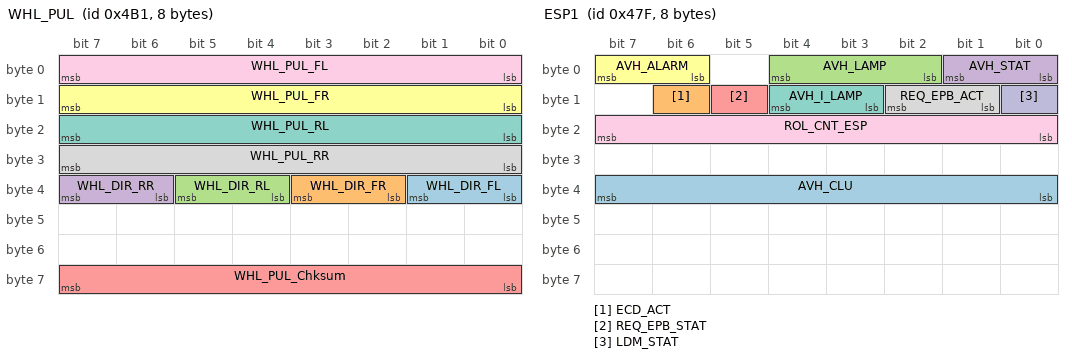
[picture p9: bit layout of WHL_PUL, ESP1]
BO_ 1201 WHL_PUL: 8 ESC
 SG_ WHL_DIR_FL : 32|2@1+ (1,0) [0|3] ""  SPAS,TPMS
 SG_ WHL_DIR_FR : 34|2@1+ (1,0) [0|3] ""  SPAS,TPMS
 SG_ WHL_DIR_RL : 36|2@1+ (1,0) [0|3] ""  SPAS,TPMS
 SG_ WHL_DIR_RR : 38|2@1+ (1,0) [0|3] ""  SPAS,TPMS
 SG_ WHL_PUL_Chksum : 56|8@1+ (1,0) [0|255] ""  SPAS,TPMS
 SG_ WHL_PUL_FR : 8|8@1+ (0.5,0) [0|127.5] "pulse count"  SPAS,TPMS
 SG_ WHL_PUL_RL : 16|8@1+ (0.5,0) [0|127.5] "pulse count"  SPAS,TPMS
 SG_ WHL_PUL_RR : 24|8@1+ (0.5,0) [0|127.5] "pulse count"  SPAS,TPMS
 SG_ WHL_PUL_FL : 0|8@1+ (0.5,0) [0|127.5] "pulse count"  SPAS,TPMS

BO_ 1200 WHL_SPD: 8 ESC
 SG_ WHL_SPD_RR : 48|14@1+ (0.03125,0) [0|511.96875] "km/h"  AFLS,AVM,PGS,SCC,TCU
 SG_ WHL_SPD_RL : 32|14@1+ (0.03125,0) [0|511.96875] "km/h"  AFLS,AVM,PGS,SCC,TCU
 SG_ WHL_SPD_FR : 16|14@1+ (0.03125,0) [0|511.96875] "km/h"  AFLS,AVM,PGS,SCC,TCU
 SG_ WHL_SPD_FL : 0|14@1+ (0.03125,0) [0|511.96875] "km/h"  AFLS,AVM,PGS,SCC,TCU

BO_ 1151 ESP1: 8 ESC
 SG_ AVH_CLU : 32|8@1+ (1,0) [0|255] ""  CLU,EPB
 SG_ ECD_ACT : 14|1@1+ (1,0) [0|1] ""  EPB
 SG_ AVH_LAMP : 2|3@1+ (1,0) [0|7] ""  CLU,EPB,SPAS
 SG_ AVH_STAT : 0|2@1+ (1,0) [0|3] ""  EPB
 SG_ REQ_EPB_STAT : 13|1@1+ (1,0) [0|1] ""  EPB
 SG_ AVH_ALARM : 6|2@1+ (1,0) [0|3] ""  CLU
 SG_ AVH_I_LAMP : 11|2@1+ (1,0) [0|3] ""  EPB
 SG_ REQ_EPB_ACT : 9|2@1+ (1,0) [0|3] ""  EPB
 SG_ ROL_CNT_ESP : 16|8@1+ (1,0) [0|255] ""  EPB
 SG_ LDM_STAT : 8|1@1+ (1,0) [0|1] ""  EPB

BO_ 1088 TCU2: 8 TCU
 SG_ ETL_TCU : 0|8@1+ (3,0) [0|762] "Nm"  EMS
 SG_ VS_TCU : 16|8@1+ (1,0) [0|254] "km/h"  CLU,DATC,EMS,FATC,MTC,MTS,PGS,SMK,TMU
 SG_ N_TC_RAW : 40|16@1+ (0.25,0) [0|16383.5] "rpm"  EMS
 SG_ N_INC_TCU : 31|1@1+ (1,0) [0|1] ""  EMS
 SG_ IDLE_UP_TCU : 30|1@1+ (1,0) [0|1] ""  EMS
 SG_ SPK_RTD_TCU : 32|8@1+ (0.375,-23.625) [-15|15] "¡Æ"  EMS
 SG_ CF_Tcu_Alive : 12|2@1+ (1,0) [0|3] ""  ESC
 SG_ FAN_CTRL_TCU : 24|2@1+ (1,0) [0|3] ""  EMS
 SG_ FUEL_CUT_TCU : 28|1@1+ (1,0) [0|1] ""  EMS
 SG_ INH_FUEL_CUT : 29|1@1+ (1,0) [0|1] ""  EMS
 SG_ BRAKE_ACT_TCU : 26|2@1+ (1,0) [0|3] ""  EMS
 SG_ CF_Tcu_ChkSum : 14|2@1+ (1,0) [0|3] ""  ESC
 SG_ VS_TCU_DECIMAL : 56|8@1+ (0.0078125,0) [0|0.9921875] "km/h"  CLU,EMS
 SG_ CUR_GR : 8|4@1+ (1,0) [0|15] ""  CLU,EMS,ESC,SCC
 SG_ ETL_TCU : 0|8@1+ (2,0) [0|508] "Nm"  EMS

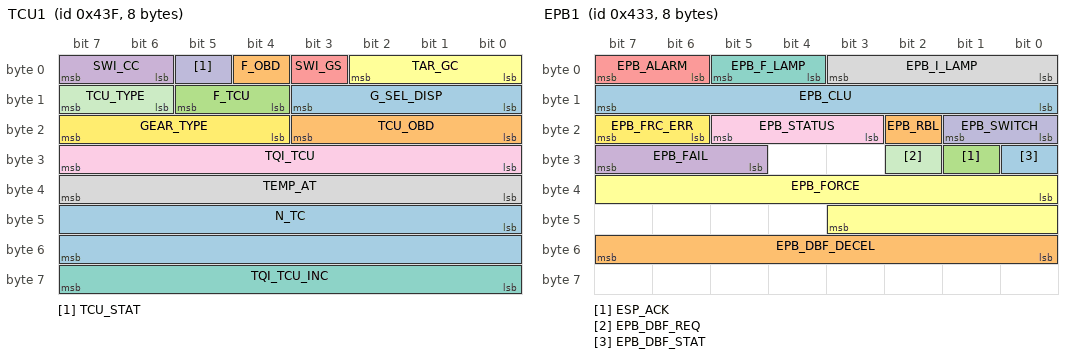
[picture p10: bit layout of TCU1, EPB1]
BO_ 1087 TCU1: 8 TCU
 SG_ N_TC : 40|16@1+ (0.25,0) [0|16383.5] "rpm"  _4WD,EMS
 SG_ F_OBD : 4|1@1+ (1,0) [0|1] ""  _4WD,EMS,ESC,MTS,TMU
 SG_ F_TCU : 12|2@1+ (1,0) [0|3] ""  _4WD,EMS,ESC
 SG_ SWI_CC : 6|2@1+ (1,0) [0|3] ""  _4WD,EMS,ESC
 SG_ SWI_GS : 3|1@1+ (1,0) [0|1] ""  _4WD,EPB,ESC,PSB_LH,PSB_RH,SCC
 SG_ TAR_GC : 0|3@1+ (1,0) [0|7] ""  _4WD,EPB,ESC,PSB_LH,PSB_RH,SCC
 SG_ TQI_TCU_INC : 56|8@1+ (0.390625,0) [0|99.609375] "%"  _4WD,EMS,ESC,TCS
 SG_ TEMP_AT : 32|8@1+ (1,-40) [-40|214] "¡É"  _4WD,CUbiS,EMS,MTS,TMU
 SG_ TQI_TCU : 24|8@1+ (0.390625,0) [0|99.609375] "%"  _4WD,EMS,TCS
 SG_ TCU_STAT : 5|1@1+ (1,0) [0|1] ""  _4WD
 SG_ TCU_TYPE : 14|2@1+ (1,0) [0|3] ""  _4WD,EMS,ESC
 SG_ GEAR_TYPE : 20|4@1+ (1,0) [0|15] ""  _4WD,ESC
 SG_ G_SEL_DISP : 8|4@1+ (1,0) [0|15] ""  _4WD,AFLS,AVM,CLU,ECS,EPB,ESC,IPM,LKAS,MTS,PGS,SCC,SMK,SPAS,TMU
 SG_ TCU_OBD : 16|4@1+ (1,0) [0|15] ""  _4WD,EMS

BO_ 1075 EPB1: 8 EPB
 SG_ EPB_CLU : 8|8@1+ (1,0) [0|255] ""  CLU
 SG_ EPB_RBL : 18|1@1+ (1,0) [0|1] ""  ESC
 SG_ ESP_ACK : 25|1@1+ (1,0) [0|1] ""  ESC
 SG_ EPB_FAIL : 29|3@1+ (1,0) [0|7] ""  ESC
 SG_ EPB_ALARM : 6|2@1+ (1,0) [0|3] ""  CLU
 SG_ EPB_FORCE : 32|12@1+ (1,-1000) [-1000|3000] "N"  ESC
 SG_ EPB_F_LAMP : 4|2@1+ (1,0) [0|3] ""  CLU,CUbiS,TMU
 SG_ EPB_I_LAMP : 0|4@1+ (1,0) [0|15] ""  CLU,CUbiS,TMU
 SG_ EPB_STATUS : 19|3@1+ (1,0) [0|7] ""  ESC,IPM,TCU
 SG_ EPB_SWITCH : 16|2@1+ (1,0) [0|3] ""  ESC
 SG_ EPB_DBF_REQ : 26|1@1+ (1,0) [0|1] ""  ESC
 SG_ EPB_FRC_ERR : 22|2@1+ (1,0) [0|3] ""  ESC,IPM,TCU
 SG_ EPB_DBF_STAT : 24|1@1+ (1,0) [0|1] ""  ESC
 SG_ EPB_DBF_DECEL : 48|8@1+ (0.01,0) [0|2.54] "g"  ESC

BO_ 1072 TCS3: 8 ESC
 SG_ AliveCounterTCS : 13|3@1+ (1,0) [0|7] ""  EMS,SCC
 SG_ MaxGear : 19|3@1+ (1,0) [0|7] ""  TCU
 SG_ DriverBraking : 55|1@1+ (1,0) [0|1] ""  EMS,SCC
 SG_ CheckSum_TCS3 : 48|4@1+ (1,0) [0|15] ""  EMS
 SG_ ACCEL_REF_ACC : 32|11@1+ (0.01,-10.23) [-10.23|10.24] "m/s^2"  SCC
 SG_ StandStill : 47|1@1+ (1,0) [0|1] ""  SCC
 SG_ PBRAKE_ACT : 53|1@1+ (1,0) [0|1] ""  SCC
 SG_ BrakeLight : 11|1@1+ (1,0) [0|1] ""  EMS
 SG_ ACC_EQUIP : 52|1@1+ (1,0) [0|1] ""  EMS
 SG_ ACCReqLim : 22|2@1+ (1,0) [0|3] ""  SCC
 SG_ ACCEnable : 43|2@1+ (1,0) [0|3] ""  SCC
 SG_ DCEnable : 12|1@1+ (1,0) [0|1] ""  EMS
 SG_ TQI_ACC : 24|8@1+ (0.390625,0) [0|99.609375] "%"  EMS
 SG_ MinGear : 16|3@1+ (1,0) [0|7] ""  TCU
 SG_ aBasis : 0|11@1+ (0.01,-10.23) [-10.23|10.24] "m/s^2"  SCC
 SG_ ACC_REQ : 54|1@1+ (1,0) [0|1] ""  EMS
 SG_ DriverOverride : 45|2@1+ (1,0) [0|3] ""  SCC

BO_ 1065 _4WD2: 8 _4WD
 SG_ CLU_PRES : 48|16@1+ (0.0625,-50) [-50|50] "bar"  ESC
 SG_ Ster_Pos : 0|16@1+ (1,-600) [-600|600] "Degree"  ESC
 SG_ FRSS : 16|8@1+ (1,0) [0|254] "km/h"  ESC
 SG_ RRSS : 32|8@1+ (1,0) [0|254] "km/h"  ESC
 SG_ RLSS : 40|8@1+ (1,0) [0|254] "km/h"  ESC
 SG_ FLSS : 24|8@1+ (1,0) [0|254] "km/h"  ESC

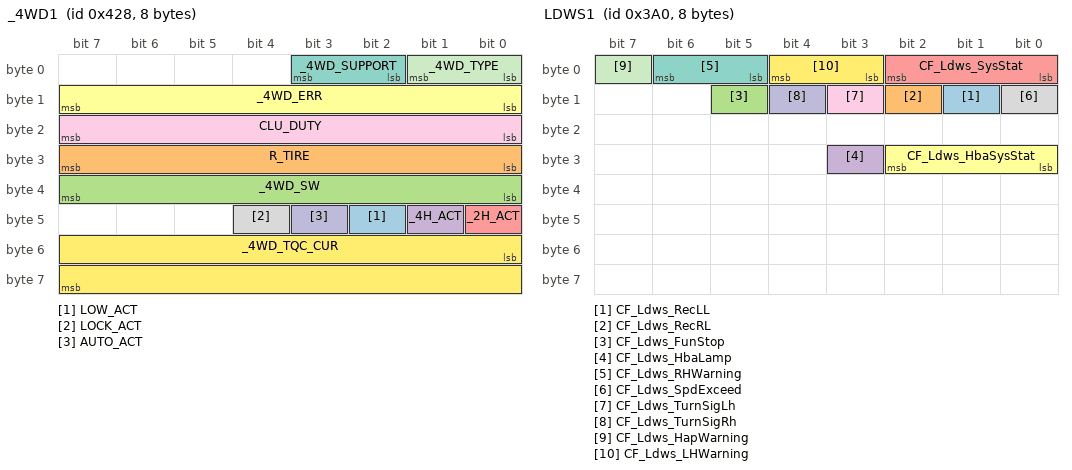
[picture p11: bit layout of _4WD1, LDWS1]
BO_ 1064 _4WD1: 8 _4WD
 SG_ LOW_ACT : 42|1@1+ (1,0) [0|1] ""  ABS,ESC
 SG_ R_TIRE : 24|8@1+ (1,200) [200|455] "mm"  ABS,ESC
 SG_ _4WD_SW : 32|8@1+ (1,0) [0|9.9] ""  ESC
 SG_ _4H_ACT : 41|1@1+ (1,0) [0|1] ""  ABS,ESC
 SG_ _2H_ACT : 40|1@1+ (1,0) [0|1] ""  ABS,ESC
 SG_ _4WD_ERR : 8|8@1+ (1,0) [0|255] ""  CLU
 SG_ _4WD_SUPPORT : 2|2@1+ (1,0) [0|3] ""  ABS,ESC
 SG_ LOCK_ACT : 44|1@1+ (1,0) [0|1] ""  ABS,ESC
 SG_ CLU_DUTY : 16|8@1+ (1,0) [0|64] "%"  ABS,ESC
 SG_ AUTO_ACT : 43|1@1+ (1,0) [0|1] ""  ABS,ESC
 SG_ _4WD_TYPE : 0|2@1+ (1,0) [0|3] ""  ACU,ESC
 SG_ _4WD_TQC_CUR : 48|16@1+ (1,0) [0|65535] "Nm"  ABS,ESC

BO_ 1056 SCC1: 8 SCC
 SG_ AliveCounterACC : 12|4@1+ (1,0) [0|15] ""  CLU,EMS,TCS
 SG_ SCCInfoDisplay : 8|3@1+ (1,0) [0|7] ""  CLU
 SG_ MainMode_ACC : 5|1@1+ (1,0) [0|1] ""  CLU
 SG_ TakeOverReq : 49|1@1+ (1,0) [0|1] ""  CLU,PSB_LH,PSB_RH
 SG_ ACCFailInfo : 1|2@1+ (1,0) [0|3] ""  CLU,CUbiS,ESC,TCS,TMU
 SG_ ACCMode : 3|2@1+ (1,0) [0|3] ""  CLU,ESC,MTS,TCS,TMU
 SG_ PreFill : 55|1@1+ (1,0) [0|1] ""  ESC,TCS
 SG_ StopReq : 6|1@1+ (1,0) [0|1] ""  ESC
 SG_ VSetDis : 40|8@1+ (1,0) [0|255] "km/h or MPH"  CLU
 SG_ aReqMax : 16|11@1+ (0.01,-10.23) [-10.23|10.24] "m/s^2"  EMS,TCS
 SG_ aReqMin : 29|11@1+ (0.01,-10.23) [-10.23|10.24] "m/s^2"  EMS,TCS
 SG_ DriverAlertDisplay : 50|2@1+ (1,0) [0|3] ""  CLU
 SG_ TauGapSet : 52|3@1+ (1,0) [0|7] ""  CLU
 SG_ ObjValid : 48|1@1+ (1,0) [0|1] ""  CLU

BO_ 1017 ECS2: 5 ECS
 SG_ Height_FL : 0|8@1+ (1,-128) [-128|127] "mm"  AFLS,CLU
 SG_ Height_RR : 24|8@1+ (1,-128) [-128|127] "mm"  AFLS,CLU
 SG_ Height_RL : 16|8@1+ (1,-128) [-128|127] "mm"  AFLS,CLU
 SG_ Height_FR : 8|8@1+ (1,-128) [-128|127] "mm"  AFLS,CLU

BO_ 928 LDWS1: 8 LDWS
 SG_ CF_Ldws_RecLL : 9|1@1+ (1,0) [0|1] ""  LDWS_Test_Tool
 SG_ CF_Ldws_RecRL : 10|1@1+ (1,0) [0|1] ""  LDWS_Test_Tool
 SG_ CF_Ldws_FunStop : 13|1@1+ (1,0) [0|1] ""  CLU
 SG_ CF_Ldws_HbaLamp : 27|1@1+ (1,0) [0|1] ""  CLU
 SG_ CF_Ldws_SysStat : 0|3@1+ (1,0) [0|7] ""  CLU,PSB_LH,PSB_RH
 SG_ CF_Ldws_HbaSysStat : 24|3@1+ (1,0) [0|7] ""  IPM
 SG_ CF_Ldws_RHWarning : 5|2@1+ (1,0) [0|3] ""  CLU,PSB_LH,PSB_RH
 SG_ CF_Ldws_SpdExceed : 8|1@1+ (1,0) [0|1] ""  LDWS_Test_Tool
 SG_ CF_Ldws_TurnSigLh : 11|1@1+ (1,0) [0|1] ""  LDWS_Test_Tool
 SG_ CF_Ldws_TurnSigRh : 12|1@1+ (1,0) [0|1] ""  LDWS_Test_Tool
 SG_ CF_Ldws_HapWarning : 7|1@1+ (1,0) [0|1] ""  PSB_LH,PSB_RH
 SG_ CF_Ldws_LHWarning : 3|2@1+ (1,0) [0|3] ""  CLU,PSB_LH,PSB_RH

BO_ 914 MDPS2: 8 MDPS
 SG_ CF_Mdps_Stat : 0|4@1+ (1,0) [0|15] ""  SPAS
 SG_ CR_Mdps_DrvTq : 8|12@1+ (0.01,-20.48) [-20.48|20.46] ""  SPAS
 SG_ CF_Mdps_Chksum : 56|8@1+ (1,0) [0|255] ""  SPAS
 SG_ CR_Mdps_StrAng : 24|16@1- (0.1,0) [-3276.8|3276.7] "Degree"  SPAS
 SG_ CF_Mdps_AliveCnt : 40|8@1+ (1,0) [0|255] ""  SPAS

BO_ 912 SPAS1: 8 SPAS
 SG_ CF_Spas_Stat : 0|4@1+ (1,0) [0|15] ""  CLU
 SG_ CF_Spas_Chksum : 56|8@1+ (1,0) [0|255] ""  CLU
 SG_ CF_Spas_AliveCnt : 32|8@1+ (1,0) [0|255] ""  CLU
 SG_ CF_Spas_TestMode : 4|2@1+ (1,0) [0|3] ""  MDPS
 SG_ CR_Spas_StrAngCmd : 8|16@1- (0.1,0) [-3276.8|3276.7] ""  CLU

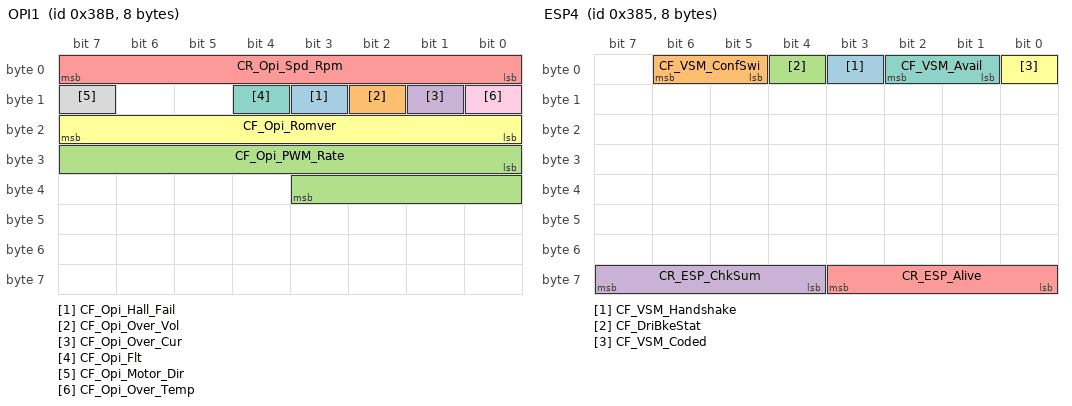
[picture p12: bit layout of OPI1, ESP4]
BO_ 907 OPI1: 8 OPI
 SG_ CF_Opi_Hall_Fail : 11|1@1+ (1,0) [0|1] ""  EMS,TCU
 SG_ CF_Opi_Over_Vol : 10|1@1+ (1,0) [0|1] ""  TCU
 SG_ CF_Opi_PWM_Rate : 24|12@1+ (1,0) [0|100] "%"  TCU
 SG_ CF_Opi_Over_Cur : 9|1@1+ (1,0) [0|1] ""  EMS,TCU
 SG_ CR_Opi_Spd_Rpm : 0|8@1+ (20,0) [0|3500] "rpm"  TCU
 SG_ CF_Opi_Romver : 16|8@1+ (1,0) [0|255] ""  TCU
 SG_ CF_Opi_Flt : 12|1@1+ (1,0) [0|1] ""  EMS,TCU
 SG_ CF_Opi_Motor_Dir : 15|1@1+ (1,0) [0|1] ""  TCU
 SG_ CF_Opi_Over_Temp : 8|1@1+ (1,0) [0|1] ""  TCU

BO_ 904 SCC3: 8 SCC
 SG_ CF_VSM_Stat : 6|2@1+ (1,0) [0|3] ""  CLU,EMS,PSB_LH,PSB_RH
 SG_ CF_VSM_DecCmdAct : 1|1@1+ (1,0) [0|1] ""  EMS
 SG_ CF_VSM_ConfMode : 24|3@1+ (1,0) [0|7] ""  CLU
 SG_ CF_VSM_Warn : 4|2@1+ (1,0) [0|3] ""  CLU
 SG_ CF_VSM_Prefill : 0|1@1+ (1,0) [0|1] ""  EMS
 SG_ CF_VSM_HBACmd : 2|2@1+ (1,0) [0|3] ""  EMS
 SG_ CR_VSM_ChkSum : 60|4@1+ (1,0) [0|15] ""  ESC,PSB_LH,PSB_RH
 SG_ CR_VSM_DecCmd : 16|8@1+ (0.01,0) [0|2.55] "g"  ESC
 SG_ CF_VSM_BeltCmd : 8|3@1+ (1,0) [0|7] ""  PSB_LH,PSB_RH
 SG_ CR_VSM_Alive : 56|4@1+ (1,0) [0|15] ""  ESC,PSB_LH,PSB_RH

BO_ 901 ESP4: 8 ESC
 SG_ CF_VSM_Handshake : 3|1@1+ (1,0) [0|1] ""  SCC
 SG_ CF_VSM_ConfSwi : 5|2@1+ (1,0) [0|3] ""  SCC
 SG_ CF_DriBkeStat : 4|1@1+ (1,0) [0|1] ""  SCC
 SG_ CR_ESP_ChkSum : 60|4@1+ (1,0) [0|15] ""  SCC
 SG_ CR_ESP_Alive : 56|4@1+ (1,0) [0|15] ""  SCC
 SG_ CF_VSM_Coded : 0|1@1+ (1,0) [0|1] ""  SCC
 SG_ CF_VSM_Avail : 1|2@1+ (1,0) [0|3] ""  SCC

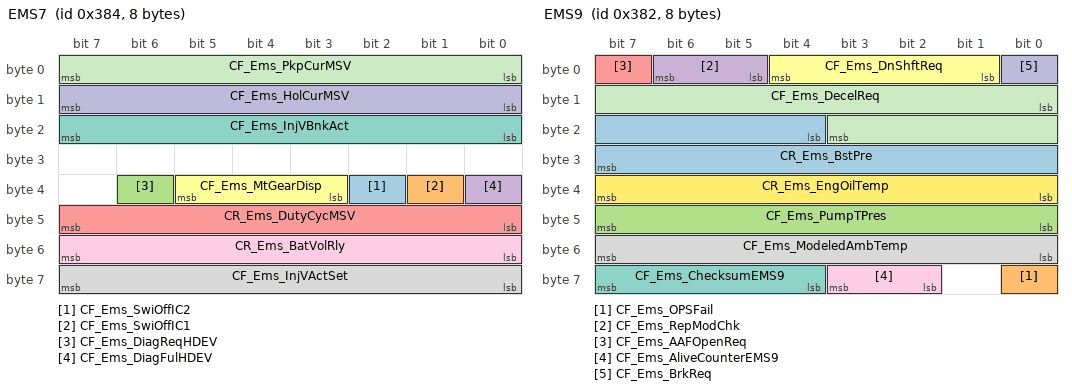
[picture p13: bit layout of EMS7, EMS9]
BO_ 900 EMS7: 8 EMS
 SG_ CF_Ems_SwiOffIC2 : 34|1@1+ (1,0) [0|1] ""  _4WD,DI_BOX,ESC,SCC
 SG_ CF_Ems_SwiOffIC1 : 33|1@1+ (1,0) [0|1] ""  _4WD,DI_BOX,ESC,SCC
 SG_ CF_Ems_DiagReqHDEV : 38|1@1+ (1,0) [0|1] ""  DI_BOX
 SG_ CF_Ems_DiagFulHDEV : 32|1@1+ (1,0) [0|1] ""  _4WD,DI_BOX,ESC,SCC
 SG_ CR_Ems_DutyCycMSV : 40|8@1+ (0.39215686275,0) [0|100] "%"  _4WD,DI_BOX,ESC,SCC
 SG_ CF_Ems_MtGearDisp : 35|3@1+ (1,0) [0|7] ""  ABS,ESC
 SG_ CF_Ems_InjVBnkAct : 16|8@1+ (1,0) [0|255] ""  _4WD,DI_BOX,ESC,SCC
 SG_ CF_Ems_InjVActSet : 56|8@1+ (1,0) [0|255] ""  _4WD,DI_BOX,ESC,SCC
 SG_ CR_Ems_BatVolRly : 48|8@1+ (0.1,0) [0|25.5] "V"  _4WD,DI_BOX,ESC,SCC
 SG_ CF_Ems_HolCurMSV : 8|8@1+ (1,0) [0|255] ""  _4WD,DI_BOX,ESC,SCC
 SG_ CF_Ems_PkpCurMSV : 0|8@1+ (1,0) [0|255] ""  _4WD,DI_BOX,ESC,SCC

BO_ 898 EMS9: 8 EMS
 SG_ CR_Ems_BstPre : 20|12@1+ (1.322,0) [0|4094] "hPa"  CLU
 SG_ CF_Ems_OPSFail : 56|1@1+ (1,0) [0|1] ""  CLU
 SG_ CF_Ems_PumpTPres : 40|8@1+ (3.137254902,0) [0|800] "kPa"  FPCM
 SG_ CF_Ems_RepModChk : 5|2@1+ (1,0) [0|3] ""  TMU
 SG_ CF_Ems_AAFOpenReq : 7|1@1+ (1,0) [0|1] ""  AAF
 SG_ CF_Ems_DnShftReq : 1|4@1+ (1,0) [0|14] ""  TCU
 SG_ CF_Ems_ChecksumEMS9 : 60|4@1+ (1,0) [0|15] ""  _4WD,AAF,ABS,ACU,AFLS,AHLS,AVM,CLU,CUbiS,DATC,DI_BOX,ECS,EMS,EPB,ESC,EVP,FATC,IPM,ISG,ISS,LDWS,LKAS,LPI,LVR,MDPS,ODS,OPI,PAS,PGS,PSB,PSB_LH,PSB_RH,REA,RPAS,SAS,SCC,SMK,SNV,SPAS,TCS,TCU,TESTER,TMU,TPMS,YRS
 SG_ CF_Ems_ModeledAmbTemp : 48|8@1+ (0.5,-41) [-40|60] "¡É"  AAF
 SG_ CF_Ems_AliveCounterEMS9 : 58|2@1+ (1,0) [0|3] ""  _4WD,AAF,ABS,ACU,AFLS,AHLS,AVM,CLU,CUbiS,DATC,DI_BOX,ECS,EMS,EPB,ESC,EVP,FATC,IPM,ISG,ISS,LDWS,LKAS,LPI,LVR,MDPS,ODS,OPI,PAS,PGS,PSB,PSB_LH,PSB_RH,REA,RPAS,SAS,SCC,SMK,SNV,SPAS,TCS,TCU,TESTER,TMU,TPMS,YRS
 SG_ CF_Ems_BrkReq : 0|1@1+ (1,0) [0|1] ""  ESC,TCS
 SG_ CF_Ems_DecelReq : 8|12@1+ (0.001,-4.094) [-4.094|0] "m/s^2"  ESC,TCS
 SG_ CR_Ems_EngOilTemp : 32|8@1+ (0.75,-40) [0|254] "¡É"  CLU

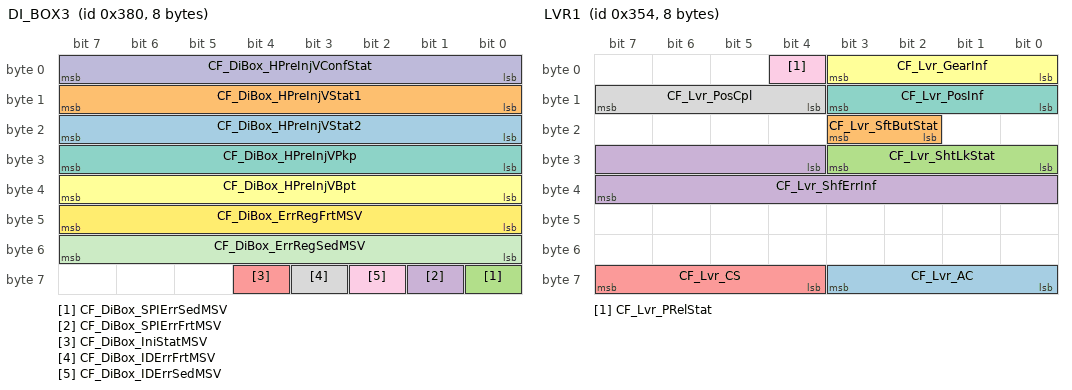
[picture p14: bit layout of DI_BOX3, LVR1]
BO_ 896 DI_BOX3: 8 DI_BOX
 SG_ CF_DiBox_HPreInjVStat2 : 16|8@1+ (1,0) [0|255] ""  EMS
 SG_ CF_DiBox_HPreInjVStat1 : 8|8@1+ (1,0) [0|255] ""  EMS
 SG_ CF_DiBox_SPIErrSedMSV : 56|1@1+ (1,0) [0|1] ""  EMS
 SG_ CF_DiBox_SPIErrFrtMSV : 57|1@1+ (1,0) [0|1] ""  EMS
 SG_ CF_DiBox_IniStatMSV : 60|1@1+ (1,0) [0|1] ""  EMS
 SG_ CF_DiBox_HPreInjVBpt : 32|8@1+ (1,0) [0|255] ""  EMS
 SG_ CF_DiBox_HPreInjVPkp : 24|8@1+ (1,0) [0|255] ""  EMS
 SG_ CF_DiBox_IDErrFrtMSV : 59|1@1+ (1,0) [0|1] ""  EMS
 SG_ CF_DiBox_IDErrSedMSV : 58|1@1+ (1,0) [0|1] ""  EMS
 SG_ CF_DiBox_HPreInjVConfStat : 0|8@1+ (1,0) [0|255] ""  EMS
 SG_ CF_DiBox_ErrRegSedMSV : 48|8@1+ (1,0) [0|255] ""  EMS
 SG_ CF_DiBox_ErrRegFrtMSV : 40|8@1+ (1,0) [0|255] ""  EMS

BO_ 880 TCU3: 8 TCU
 SG_ N_TGT_LUP : 0|8@1+ (10,500) [500|3040] "rpm"  EMS
 SG_ SLOPE_TCU : 8|6@1+ (0.5,-16) [-16|15.5] "%"  CLU,CUbiS,EMS
 SG_ TQI_TCU_INC : 48|8@1+ (0.390625,0) [0|99.609375] "%"  EMS
 SG_ CF_Tcu_TarGr : 20|4@1+ (1,0) [0|15] ""  CLU,EMS,SCC
 SG_ CF_Tcu_Alive3 : 58|2@1+ (1,0) [0|3] ""  EMS
 SG_ CF_Tcu_InhCda : 14|1@1+ (1,0) [0|1] ""  EMS
 SG_ CF_Tcu_InhVis : 28|1@1+ (1,0) [0|1] ""  EMS
 SG_ CF_Tcu_NCStat : 18|2@1+ (1,0) [0|3] ""  EMS
 SG_ CF_Tcu_SptRdy : 57|1@1+ (1,0) [0|1] ""  CLU,EMS
 SG_ CF_Tcu_ChkSum3 : 60|4@1+ (1,0) [0|15] ""  EMS
 SG_ CF_Tcu_ITPhase : 30|1@1+ (1,0) [0|1] ""  EMS
 SG_ CF_Tcu_PRelReq : 29|1@1+ (1,0) [0|1] ""  E_Shifter
 SG_ CF_Tcu_ShfPatt : 24|4@1+ (1,0) [0|15] ""  CLU,CUbiS,EMS
 SG_ CF_Tcu_BkeOnReq : 16|2@1+ (1,0) [0|3] ""  EMS
 SG_ CF_Tcu_IsgInhib : 15|1@1+ (1,0) [0|1] ""  EMS
 SG_ CF_Tcu_SbwPInfo : 56|1@1+ (1,0) [0|1] ""  EMS
 SG_ CF_Tcu_TqGrdLim : 32|8@1+ (10,0) [0|2540] "Nm/s"  EMS
 SG_ CF_Tcu_ActEcoRdy : 31|1@1+ (1,0) [0|1] ""  EMS
 SG_ CR_Tcu_IsgTgtRPM : 40|8@1+ (20,0) [0|3500] "rpm"  OPI

BO_ 852 LVR1: 8 LVR
 SG_ CF_Lvr_AC : 56|4@1+ (1,0) [0|15] ""  TCU
 SG_ CF_Lvr_SftButStat : 18|2@1+ (1,0) [0|3] ""  TCU
 SG_ CF_Lvr_ShtLkStat : 24|4@1+ (1,0) [0|15] ""  TCU
 SG_ CF_Lvr_ShfErrInf : 28|12@1+ (1,0) [0|8191] ""  TCU
 SG_ CF_Lvr_CS : 60|4@1+ (1,0) [0|15] ""  TCU
 SG_ CF_Lvr_GearInf : 0|4@1+ (1,0) [0|15] ""  TCU
 SG_ CF_Lvr_PosInf : 8|4@1+ (1,0) [0|15] ""  TCU
 SG_ CF_Lvr_PosCpl : 12|4@1+ (1,0) [0|15] ""  TCU
 SG_ CF_Lvr_PRelStat : 4|1@1+ (1,0) [0|1] ""  TCU

BO_ 848 FATC: 8 FATC
 SG_ CF_Fatc_ActiveEco : 43|1@1+ (1,0) [0|1] ""  CLU
 SG_ CF_Fatc_AcnCltEnRq : 9|1@1+ (1,0) [0|1] ""  EMS
 SG_ CF_Fatc_IsgStopReq : 16|1@1+ (1,0) [0|1] ""  EMS
 SG_ CF_Fatc_PtcRlyStat : 46|1@1+ (1,0) [0|1] ""  EMS
 SG_ CR_Fatc_OutTempSns : 32|8@1+ (0.5,-40) [-40|60] "¡É"  CLU,SPAS
 SG_ CF_Fatc_EngStartReq : 15|1@1+ (1,0) [0|1] ""  EMS
 SG_ CF_Fatc_AutoActivation : 44|1@1+ (1,0) [0|1] ""  TMU
 SG_ CF_FATC_Iden : 12|2@1+ (1,0) [0|3] ""  EMS
 SG_ CR_Fatc_TqAcnOut : 0|8@1+ (0.2,0) [0|50.8] "Nm"  EMS
 SG_ CF_Fatc_Compload : 40|3@1+ (1,0) [0|7] ""  EMS
 SG_ CF_Fatc_AcnRqSwi : 8|1@1+ (1,0) [0|1] ""  EMS
 SG_ CR_Fatc_OutTemp : 24|8@1+ (0.5,-40) [-40|60] "¡É"  EMS,SPAS
 SG_ CF_Fatc_BlwrMax : 14|1@1+ (1,0) [0|1] ""  EMS
 SG_ CF_Fatc_MsgCnt : 20|4@1+ (1,0) [0|15] ""  EMS
 SG_ CF_Fatc_EcvFlt : 10|1@1+ (1,0) [0|1] ""  EMS
 SG_ CF_Fatc_BlwrOn : 11|1@1+ (1,0) [0|1] ""  EMS
 SG_ CF_Fatc_ChkSum : 56|8@1+ (1,0) [0|255] ""  EMS,SPAS
 SG_ CF_Fatc_CtrInf : 17|3@1+ (1,0) [0|7] ""  EMS

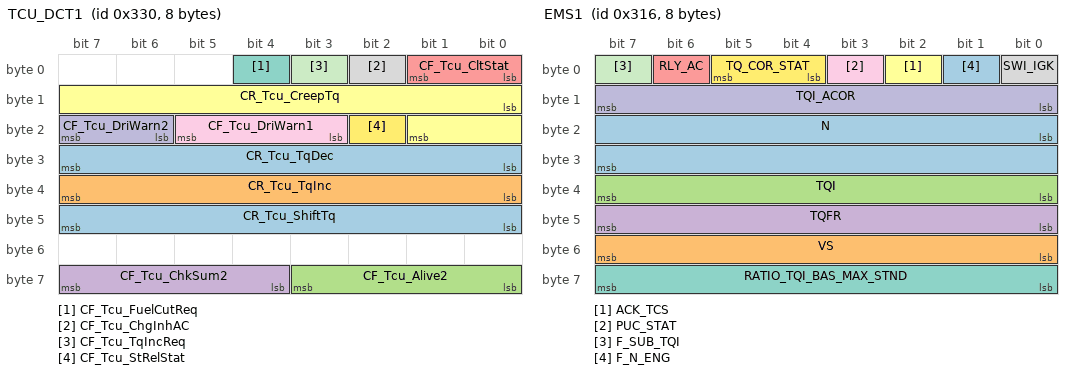
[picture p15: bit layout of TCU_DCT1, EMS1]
BO_ 816 TCU_DCT1: 8 TCU
 SG_ CR_Tcu_TqDec : 24|8@1+ (0.390625,0) [0|99.609375] "%"  EMS
 SG_ CR_Tcu_TqInc : 32|8@1+ (0.390625,0) [0|99.609375] "%"  EMS
 SG_ CF_Tcu_Alive2 : 56|4@1+ (1,0) [0|15] ""  EMS
 SG_ CF_Tcu_ChkSum2 : 60|4@1+ (1,0) [0|15] ""  EMS
 SG_ CF_Tcu_CltStat : 0|2@1+ (1,0) [0|3] ""  EMS
 SG_ CR_Tcu_CreepTq : 8|10@1+ (1,-512) [-512|511] "Nm"  EMS
 SG_ CF_Tcu_FuelCutReq : 4|1@1+ (1,0) [0|1] ""  EMS
 SG_ CF_Tcu_ChgInhAC : 2|1@1+ (1,0) [0|1] ""  EMS
 SG_ CF_Tcu_DriWarn1 : 19|3@1+ (1,0) [0|7] ""  CLU,EMS,ESC,SMK
 SG_ CF_Tcu_DriWarn2 : 22|2@1+ (1,0) [0|3] ""  CLU,EMS,ESC,SMK
 SG_ CF_Tcu_TqIncReq : 3|1@1+ (1,0) [0|1] ""  EMS
 SG_ CF_Tcu_StRelStat : 18|1@1+ (1,0) [0|1] ""  CLU,EMS,ESC,SMK
 SG_ CR_Tcu_ShiftTq : 40|8@1+ (0.390625,0) [0|99.609375] "%"  EMS

BO_ 809 EMS2: 8 EMS
 SG_ TPS : 40|8@1+ (0.4694836,-15.0234742) [-15.0234742|104.6948357] "%"  _4WD,ACU,CUbiS,DATC,EPB,ESC,FATC,MTC,MTS,TCU,TMU
 SG_ MAF_FAC_ALTI_MMV : 16|8@1+ (0.00781,0) [0|1.99155] ""  _4WD,TCU
 SG_ GP_CTL : 38|2@1+ (1,0) [0|3] ""  _4WD,ISS
 SG_ ACC_ACT : 30|1@1+ (1,0) [0|1] ""  _4WD,ABS,CUbiS,ESC,MTS,TCS,TCU,TMU
 SG_ CLU_ACK : 31|1@1+ (1,0) [0|1] ""  _4WD,EPB,ISG
 SG_ ENG_CHR : 34|4@1+ (1,0) [0|15] ""  _4WD,ABS,ACU,ESC,FATC,IPM,SCC,SMK,TCS,TCU
 SG_ ENG_VOL : 56|8@1+ (0.1,0) [0|25.5] "liter"  _4WD,ABS,ACU,ESC,FATC,IPM,SCC,SMK
 SG_ TQ_STND m3 : 0|6@1+ (10,0) [0|630] "Nm"  _4WD,ECS,EPB,ESC,TCS,TCU
 SG_ CAN_VERS m0 : 0|6@1+ (1,0) [0|7.7] ""  _4WD,ABS,ESC,TCS,TCU
 SG_ CONF_TCU m1 : 0|6@1+ (1,0) [0|63] ""  _4WD,ACU,CUbiS,ESC,IPM,MTS,SMK,TCS,TMU
 SG_ MUL_CODE M : 6|2@1+ (1,0) [0|3] ""  _4WD,ABS,ACU,CUbiS,ECS,EPB,ESC,IPM,MTS,SMK,TCS,TCU,TMU
 SG_ TEMP_ENG : 8|8@1+ (0.75,-48) [-48|143.25] "¡É"  _4WD,CLU,CUbiS,DATC,EPB,FATC,IPM,MTC,MTS,SMK,TCU,TMU
 SG_ BRAKE_ACT : 32|2@1+ (1,0) [0|3] ""  _4WD,ABS,ACU,AFLS,DATC,ECS,EPB,ESC,FATC,MTC,TCS,TCU
 SG_ PV_AV_CAN : 48|8@1+ (0.3906,0) [0|99.603] "%"  _4WD,AFLS,CUbiS,DATC,EPB,ESC,FATC,MTC,MTS,PSB_LH,PSB_RH,TCU,TMU
 SG_ OD_OFF_REQ : 29|1@1+ (1,0) [0|1] ""  _4WD,TCU
 SG_ VB_OFF_ACT : 24|1@1+ (1,0) [0|1] ""  _4WD,TCU
 SG_ OBD_FRF_ACK m2 : 0|6@1+ (1,0) [0|63] ""  _4WD,TCS,TCU
 SG_ CONF_MIL_FMY : 26|3@1+ (1,0) [0|7] ""  _4WD,TCS,TCU
 SG_ ACK_ES : 25|1@1+ (1,0) [0|1] ""  _4WD,ACU

BO_ 790 EMS1: 8 EMS
 SG_ N : 16|16@1+ (0.25,0) [0|16383.75] "rpm"  _4WD,ACU,AFLS,CUbiS,DATC,ECS,EHPS,EPB,ESC,FATC,MDPS,MTC,MTS,SCC,TCS,TCU,TMU
 SG_ VS : 48|8@1+ (1,0) [0|255] "km/h"  _4WD,ACU,AFLS,AHLS,CUbiS,DATC,ECS,EHPS,EPB,FATC,IPM,MDPS,MTC,MTS,PGS,SCC,SMK,SPAS,TCU,TMU
 SG_ TQI : 32|8@1+ (0.390625,0) [0|99.6094] "%"  _4WD,ECS,EPB,ESC,TCS,TCU
 SG_ TQFR : 40|8@1+ (0.390625,0) [0|99.6094] "%"  _4WD,EPB,ESC,TCS,TCU
 SG_ RLY_AC : 6|1@1+ (1,0) [0|1] ""  _4WD,CLU,DATC,FATC,MTC,TCS,TCU
 SG_ ACK_TCS : 2|1@1+ (1,0) [0|1] ""  _4WD,ESC,TCS
 SG_ RATIO_TQI_BAS_MAX_STND : 56|8@1+ (0.0078,0) [0|2] ""  _4WD,TCU
 SG_ SWI_IGK : 0|1@1+ (1,0) [0|1] ""  _4WD,ABS,ACU,AEMC,AFLS,AHLS,CLU,CUbiS,DATC,DI_BOX,ECS,EHPS,EMS,EPB,ESC,FATC,IPM,ISG,ISS,LDWS,LKAS,LPI,MDPS,MTC,MTS,ODS,PGS,PSB_LH,PSB_RH,REA,SAS,SCC,SPAS,TCS,TCU,TMU,TPMS,YRS
 SG_ PUC_STAT : 3|1@1+ (1,0) [0|1] ""  _4WD,CUbiS,DATC,FATC,MTC,MTS,TCU,TMU
 SG_ TQI_ACOR : 8|8@1+ (0.390625,0) [0|99.6094] "%"  _4WD,EPB,ESC,TCS,TCU
 SG_ F_SUB_TQI : 7|1@1+ (1,0) [0|1] ""  _4WD,ECS,EPB,ESC,TCS,TCU
 SG_ TQ_COR_STAT : 4|2@1+ (1,0) [0|3] ""  _4WD,ESC,TCS,TCU
 SG_ F_N_ENG : 1|1@1+ (1,0) [0|1] ""  _4WD,ACU,AFLS,CUbiS,DATC,ECS,EHPS,EPB,ESC,FATC,MDPS,MTC,MTS,SCC,TCS,TCU,TMU

BO_ 704 ACU4: 8 ACU
 SG_ CF_SBR_Ind : 4|2@1+ (1,0) [0|3] ""  CLU
 SG_ CF_SWL_Ind : 0|2@1+ (1,0) [0|3] ""  CLU
 SG_ CF_TTL_Ind : 2|2@1+ (1,0) [0|3] ""  CLU

BO_ 688 SAS1: 6 SAS
 SG_ SAS_Trim : 26|1@1+ (1,0) [0|1] "" Vector__XXX
 SG_ SAS_CAL : 25|1@1+ (1,0) [0|1] "" Vector__XXX
 SG_ SAS_OK : 24|1@1+ (1,0) [0|1] "" Vector__XXX
 SG_ SAS_Speed : 16|8@1+ (4,0) [0|1016] ""  ECS,EHPS,ESC,SCC,SPAS
 SG_ SAS_Angle : 0|16@1- (0.1,0) [-3276.8|3276.7] "Deg"  ACU,AFLS,AVM,ECS,ESC,IPM,PGS,PSB_LH,PSB_RH,SCC,SPAS,TCU
 SG_ SAS_Stat : 24|8@1+ (1,0) [0|255] ""  ECS,ESC,PSB_LH,PSB_RH,SCC,SPAS
 SG_ MsgCount : 32|4@1+ (1,0) [0|15] ""  ECS,ESC,SCC,SPAS
 SG_ CheckSum : 36|4@1+ (1,0) [0|15] ""  ECS,EMS,ESC,SCC,SPAS

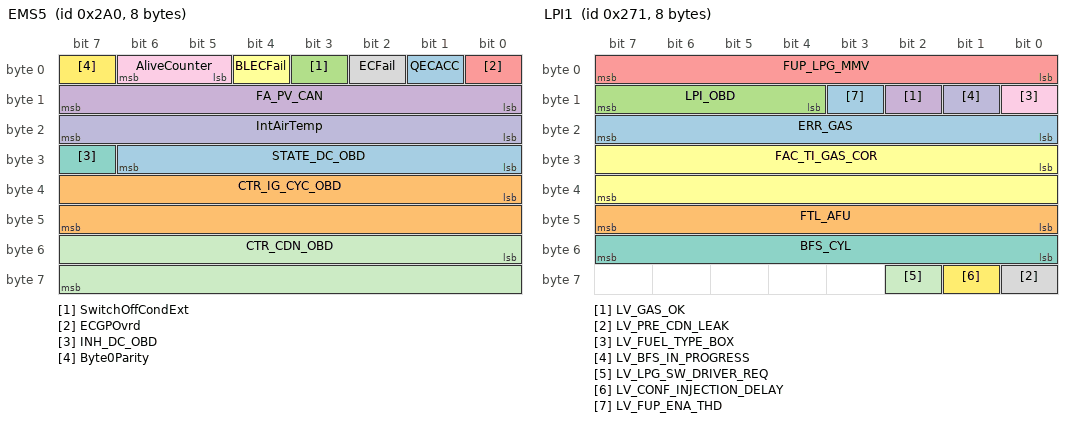
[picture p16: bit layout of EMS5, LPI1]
BO_ 672 EMS5: 8 EMS
 SG_ STATE_DC_OBD : 24|7@1+ (1,0) [0|127] ""  TCU
 SG_ CTR_IG_CYC_OBD : 32|16@1+ (1,0) [0|65535] ""  ACU,TCU
 SG_ SwitchOffCondExt : 3|1@1+ (1,0) [0|1] ""  ESC
 SG_ FA_PV_CAN : 8|8@1+ (0.3906,0) [0|99.2] "%"  ESC,TCU
 SG_ ECGPOvrd : 0|1@1+ (1,0) [0|1] ""  ESC,SCC
 SG_ BLECFail : 4|1@1+ (1,0) [0|1] ""  ESC
 SG_ INH_DC_OBD : 31|1@1+ (1,0) [0|1] ""  TCU
 SG_ ECFail : 2|1@1+ (1,0) [0|1] ""  ESC
 SG_ AliveCounter : 5|2@1+ (1,0) [0|3] ""  ESC
 SG_ IntAirTemp : 16|8@1+ (0.75,-48) [-48|143.25] "¡É"  ECS,TCU
 SG_ CTR_CDN_OBD : 48|16@1+ (1,0) [0|65535] ""  TCU
 SG_ Byte0Parity : 7|1@1+ (1,0) [0|1] ""  ESC
 SG_ QECACC : 1|1@1+ (1,0) [0|1] ""  ESC

BO_ 640 EMS3: 8 EMS
 SG_ AMP m0 : 56|8@1+ (21.22,0) [0|5411.1] "hPa"  LPI
 SG_ EOS : 16|8@1+ (1,0) [0|255] ""  LPI
 SG_ MAF : 40|8@1+ (5.447,0) [0|1388.985] "mg/TDC"  LPI
 SG_ MAP m1 : 56|8@1+ (0.47058,0) [0|119.9979] "kPa"  LPI
 SG_ TCO : 24|8@1+ (0.75,-48) [-48|143.25] "¡É"  LPI
 SG_ TIA : 48|8@1+ (0.75,-48) [-48|143.25] "¡É"  LPI
 SG_ N_32 : 32|8@1+ (32,0) [0|8160] "rpm"  LPI
 SG_ ERR_FUEL : 8|8@1+ (1,0) [0|255] ""  LPI
 SG_ LV_CRASH : 2|1@1+ (1,0) [0|1] ""  LPI
 SG_ LV_GSL_MAP M : 4|1@1+ (1,0) [0|1] ""  LPI
 SG_ LV_ENG_TURN : 5|1@1+ (1,0) [0|1] ""  LPI
 SG_ LV_BFS_CFIRM : 1|1@1+ (1,0) [0|1] ""  LPI
 SG_ LV_VB_OFF_ACT : 3|1@1+ (1,0) [0|1] ""  LPI
 SG_ LV_FUEL_TYPE_ECU : 0|1@1+ (1,0) [0|1] ""  LPI,SMK

BO_ 625 LPI1: 8 LPI
 SG_ ERR_GAS : 16|8@1+ (1,0) [0|255] ""  EMS
 SG_ FTL_AFU : 40|8@1+ (0.392,0) [0|99.96] "%"  EMS
 SG_ LPI_OBD : 12|4@1+ (1,0) [0|15] ""  EMS
 SG_ LV_GAS_OK : 10|1@1+ (1,0) [0|1] ""  EMS
 SG_ FUP_LPG_MMV : 0|8@1+ (128,0) [0|32640] "hPa"  EMS
 SG_ FAC_TI_GAS_COR : 24|16@1+ (3.05E-005,0) [0|1.9988175] ""  EMS
 SG_ BFS_CYL : 48|8@1+ (1,0) [0|6] "Cyl Nr."  EMS
 SG_ LV_PRE_CDN_LEAK : 56|1@1+ (1,0) [0|1] ""  EMS
 SG_ LV_FUEL_TYPE_BOX : 8|1@1+ (1,0) [0|1] ""  EMS
 SG_ LV_BFS_IN_PROGRESS : 9|1@1+ (1,0) [0|1] ""  EMS
 SG_ LV_LPG_SW_DRIVER_REQ : 58|1@1+ (1,0) [0|1] ""  EMS
 SG_ LV_CONF_INJECTION_DELAY : 57|1@1+ (1,0) [0|1] ""  EMS
 SG_ LV_FUP_ENA_THD : 11|1@1+ (1,0) [0|1] ""  EMS,IPM,SMK

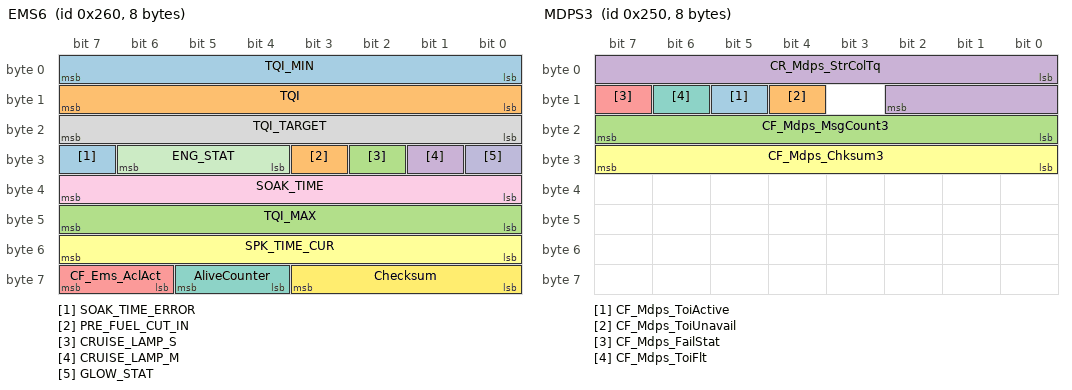
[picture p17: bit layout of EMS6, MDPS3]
BO_ 608 EMS6: 8 EMS
 SG_ SOAK_TIME_ERROR : 31|1@1+ (1,0) [0|1] ""  DATC,FATC,LPI,MTC,TCU
 SG_ PRE_FUEL_CUT_IN : 27|1@1+ (1,0) [0|1] ""  TCU
 SG_ CRUISE_LAMP_S : 26|1@1+ (1,0) [0|1] ""  CLU
 SG_ CRUISE_LAMP_M : 25|1@1+ (1,0) [0|1] ""  CLU
 SG_ CF_Ems_AclAct : 62|2@1+ (1,0) [0|3] ""  ESC
 SG_ SPK_TIME_CUR : 48|8@1+ (0.375,-35.625) [-35.625|60] "¢ª"  TCU
 SG_ AliveCounter : 60|2@1+ (1,0) [0|3] ""  ESC
 SG_ TQI_TARGET : 16|8@1+ (0.390625,0) [0|99.609375] "%"  EPB,ESC,TCS,TCU
 SG_ SOAK_TIME : 32|8@1+ (1,0) [0|255] "Min"  DATC,EPB,FATC,LPI,MTC,TCU
 SG_ GLOW_STAT : 24|1@1+ (1,0) [0|1] ""  CLU,IPM,SMK
 SG_ ENG_STAT : 28|3@1+ (1,0) [0|7] ""  CLU,EPB,ESC,EVP,IPM,SMK
 SG_ Checksum : 56|4@1+ (1,0) [0|15] ""  ESC
 SG_ TQI_MIN : 0|8@1+ (0.390625,0) [0|99.609375] "%"  ESC
 SG_ TQI : 8|8@1+ (0.390625,0) [0|99.609375] "%"  ESC,TCS,TCU
 SG_ TQI_MAX : 40|8@1+ (0.390625,0) [0|99.609375] "%"  ESC,TCS

BO_ 592 MDPS3: 8 MDPS
 SG_ CF_Mdps_ToiActive : 13|1@1+ (1,0) [0|1] ""  LKAS
 SG_ CF_Mdps_ToiUnavail : 12|1@1+ (1,0) [0|1] ""  LKAS
 SG_ CF_Mdps_MsgCount3 : 16|8@1+ (1,0) [0|255] ""  LKAS
 SG_ CR_Mdps_StrColTq : 0|11@1+ (0.0078125,-8) [-8|7.9921875] "Nm"  LKAS
 SG_ CF_Mdps_FailStat : 15|1@1+ (1,0) [0|1] ""  LKAS
 SG_ CF_Mdps_Chksum3 : 24|8@1+ (1,0) [0|255] ""  LKAS
 SG_ CF_Mdps_ToiFlt : 14|1@1+ (1,0) [0|1] ""  LKAS

BO_ 584 LKAS2: 4 LKAS
 SG_ CF_Lkas_ActToi : 12|1@1+ (1,0) [0|1] ""  MDPS
 SG_ CR_Lkas_StrToqReq : 0|11@1+ (0.0078125,-8) [-8|8] "Nm"  MDPS
 SG_ CF_Lkas_MsgCount2 : 14|4@1+ (1,0) [0|15] ""  MDPS
 SG_ CF_Lkas_Chksum2 : 24|8@1+ (1,0) [0|255] ""  MDPS
 SG_ CF_Lkas_ToiFlt : 13|1@1+ (1,0) [0|1] ""  MDPS

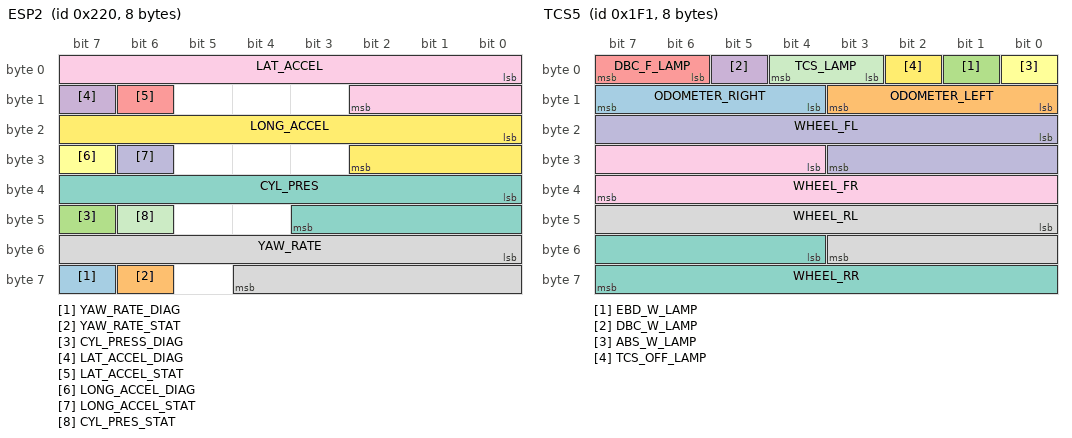
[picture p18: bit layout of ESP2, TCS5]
BO_ 544 ESP2: 8 ESC
 SG_ YAW_RATE_DIAG : 63|1@1+ (1,0) [0|1] ""  _4WD,AFLS,LDWS,PSB_LH,PSB_RH,SCC,SPAS
 SG_ YAW_RATE_STAT : 62|1@1+ (1,0) [0|1] ""  _4WD,AFLS,LDWS,LKAS,MTS,PSB_LH,PSB_RH,SCC,SPAS,TMU
 SG_ CYL_PRESS_DIAG : 47|1@1+ (1,0) [0|1] ""  _4WD,ECS,EPB,PSB_LH,PSB_RH,TCU
 SG_ LAT_ACCEL_DIAG : 15|1@1+ (1,0) [0|1] ""  _4WD,PSB_LH,PSB_RH,SCC
 SG_ LAT_ACCEL_STAT : 14|1@1+ (1,0) [0|1] ""  _4WD,LKAS,PSB_LH,PSB_RH,SCC
 SG_ LONG_ACCEL_DIAG : 31|1@1+ (1,0) [0|1] ""  _4WD,PSB_LH,PSB_RH,SPAS,TCU
 SG_ CYL_PRES : 32|12@1+ (0.1,0) [0|409.5] "bar"  _4WD,ECS,EPB,PSB_LH,PSB_RH,TCU
 SG_ YAW_RATE : 48|13@1+ (0.01,-40.95) [-40.95|40.96] "¢ª/s"  _4WD,AFLS,LDWS,LKAS,MTS,PSB_LH,PSB_RH,SCC,SPAS,TMU
 SG_ LAT_ACCEL : 0|11@1+ (0.01,-10.23) [-10.23|10.24] "m/s^2"  _4WD,LKAS,PSB_LH,PSB_RH,TCU
 SG_ LONG_ACCEL_STAT : 30|1@1+ (1,0) [0|1] ""  _4WD,LKAS,PSB_LH,PSB_RH,SPAS,TCU
 SG_ CYL_PRES_STAT : 46|1@1+ (1,0) [0|1] ""  _4WD,ECS,EPB,PSB_LH,PSB_RH,TCU
 SG_ LONG_ACCEL : 16|11@1+ (0.01,-10.23) [-10.23|10.24] "m/s^2"  _4WD,EMS,EPB,LKAS,PSB_LH,PSB_RH,SPAS,TCU

BO_ 497 TCS5: 8 ESC
 SG_ ODOMETER_RIGHT : 12|4@1+ (1,0) [0|15] "m"  _4WD,CLU
 SG_ ODOMETER_LEFT : 8|4@1+ (1,0) [0|15] "m"  _4WD,CLU
 SG_ EBD_W_LAMP : 1|1@1+ (1,0) [0|1] ""  _4WD,CLU
 SG_ DBC_W_LAMP : 5|1@1+ (1,0) [0|1] ""  _4WD,CLU
 SG_ DBC_F_LAMP : 6|2@1+ (1,0) [0|3] ""  _4WD,CLU
 SG_ ABS_W_LAMP : 0|1@1+ (1,0) [0|1] ""  _4WD,CLU,CUbiS,MTS,TMU
 SG_ WHEEL_RR : 52|12@1+ (0.125,0) [0|511.875] "km/h"  _4WD,AVM,CLU,EMS,EPB,LKAS,MTS,PGS,PSB_LH,PSB_RH,SMK,SPAS,TCU,TMU
 SG_ WHEEL_RL : 40|12@1+ (0.125,0) [0|511.875] "km/h"  _4WD,AVM,CLU,EMS,EPB,LKAS,MTS,PGS,PSB_LH,PSB_RH,SMK,SPAS,TCU,TMU
 SG_ WHEEL_FR : 28|12@1+ (0.125,0) [0|511.875] "km/h"  _4WD,AVM,CLU,EMS,EPB,LKAS,MTS,PGS,PSB_LH,PSB_RH,SMK,SPAS,TCU,TMU
 SG_ WHEEL_FL : 16|12@1+ (0.125,0) [0|511.875] "km/h"  _4WD,AVM,CLU,EMS,EPB,LKAS,MTS,PGS,PSB_LH,PSB_RH,SMK,SPAS,TCU,TMU
 SG_ TCS_LAMP : 3|2@1+ (1,0) [0|3] ""  _4WD,CLU,CUbiS,TMU
 SG_ TCS_OFF_LAMP : 2|1@1+ (1,0) [0|1] ""  _4WD,ACU,CLU

BO_ 496 TCS2: 4 ESC
 SG_ SA_Z_FLAG : 31|1@1+ (1,0) [0|1] ""  _4WD,ACU,MDPS
 SG_ SA_COUNT : 0|16@1+ (2,-32768) [-32768|98302] "¢ª"  _4WD,ACU,MDPS
 SG_ SA_Z_COUNT : 16|15@1+ (2,-32768) [-32768|32766] "¢ª"  _4WD,ACU,MDPS

BO_ 399 EMS_H2: 8 EMS
 SG_ CF_Ems_OilChg : 38|1@1+ (1,0) [0|1] ""  CLU
 SG_ CF_Ems_EtcLimpMod : 39|1@1+ (1,0) [0|1] ""  CLU
 SG_ CF_Ems_EngRunNorm : 61|1@1+ (1,0) [0|1] ""  TCU
 SG_ CF_Ems_SldPosAct : 55|1@1+ (1,0) [0|1] ""  CLU
 SG_ CF_Ems_IdlStpFCO : 58|1@1+ (1,0) [0|1] ""  CLU
 SG_ CF_Ems_HPresStat : 56|1@1+ (1,0) [0|1] ""  TCU
 SG_ CF_Ems_DownTarGr : 49|1@1+ (1,0) [0|1] ""  CLU
 SG_ CF_Ems_ActEcoAct : 60|1@1+ (1,0) [0|1] ""  CLU,TCU
 SG_ CF_Ems_IsgStat2 : 62|2@1+ (2,0) [0|3] ""  CLU
 SG_ CF_Ems_DesCurGr : 50|4@1+ (1,0) [0|15] ""  CLU
 SG_ CF_Ems_UpTarGr : 48|1@1+ (1,0) [0|1] ""  CLU
 SG_ CF_Ems_IsgStat : 35|3@1+ (1,0) [0|7] ""  CLU,EPB,MDPS,SMK,TCU
 SG_ CF_Ems_SldAct : 54|1@1+ (1,0) [0|1] ""  CLU
 SG_ CF_Ems_IsgBuz : 57|1@1+ (1,0) [0|1] ""  CLU
 SG_ CF_Ems_FCopen : 59|1@1+ (1,0) [0|1] ""  CLU
 SG_ R_NEngIdlTgC : 40|8@1+ (10,0) [0|2550] "rpm"  DATC,FATC,MTC,TCU
 SG_ R_TqAcnApvC : 0|8@1+ (0.2,0) [0|51] "Nm"  CLU,DATC,FATC,MTC
 SG_ TQI_B : 16|8@1+ (0.390625,0) [0|99.609375] "%"  TCU
 SG_ SLD_VS : 24|8@1+ (1,0) [0|255] "km/h"  CLU
 SG_ R_PAcnC : 8|8@1+ (125,0) [0|31875] "hPa"  CLU,DATC,FATC,MTC
 SG_ CF_CdaStat : 32|3@1+ (1,0) [0|7] ""  AEMC

BO_ 387 REA1: 8 REA
 SG_ CF_EndBst_RamFlt : 10|1@1+ (1,0) [0|1] ""  EMS
 SG_ CF_EndBst_HbriOverCur : 3|1@1+ (1,0) [0|1] ""  EMS
 SG_ CR_EndBst_ActPos : 16|16@1+ (0.117,0) [1.989|118.053] "¢ª"  EMS
 SG_ CR_EndBst_DemPos : 32|16@1+ (0.117,0) [0|119.691] "¢ª"  EMS
 SG_ CR_EndBst_HbriPwr : 48|16@1+ (0.045,0) [0|99.99] "%"  EMS
 SG_ CF_EndBst_PosSnsOSOR : 7|1@1+ (1,0) [0|1] ""  EMS
 SG_ CF_EndBst_PosSnsKOR : 6|1@1+ (1,0) [0|1] ""  EMS
 SG_ CF_EndBst_AgH : 12|1@1+ (1,0) [0|1] ""  EMS
 SG_ CF_EndBst_AgL : 13|1@1+ (1,0) [0|1] ""  EMS
 SG_ CF_EndBst_ORVol : 14|1@1+ (1,0) [0|1] ""  EMS
 SG_ CF_EndBst_CanFlt : 11|1@1+ (1,0) [0|1] ""  EMS
 SG_ CF_EndBst_EepFlt : 8|1@1+ (1,0) [0|1] ""  EMS
 SG_ CF_EndBst_PwmDuH : 0|1@1+ (1,0) [0|1] ""  EMS
 SG_ CF_EndBst_PwmDuL : 1|1@1+ (1,0) [0|1] ""  EMS
 SG_ CF_EndBst_HbriOverTemp : 4|1@1+ (1,0) [0|1] ""  EMS
 SG_ CF_EndBst_PwmFqOutRng : 2|1@1+ (1,0) [0|1] ""  EMS
 SG_ CF_EndBst_RomFlt : 9|1@1+ (1,0) [0|1] ""  EMS

BO_ 357 VSM2: 8 MDPS
 SG_ CF_Mdps_Def : 24|1@1+ (1,0) [0|1] ""  ESC
 SG_ CF_Mdps_SErr : 25|1@1+ (1,0) [0|1] ""  ESC
 SG_ CR_Mdps_OutTq : 12|12@1+ (0.1,-204.8) [-204.8|204.7] ""  ESC
 SG_ CR_Mdps_StrTq : 0|12@1+ (0.01,-20.48) [-20.48|20.47] "Nm"  ESC
 SG_ CF_Mdps_Chksum : 56|8@1+ (1,0) [0|255] ""  ESC
 SG_ CF_Mdps_AliveCnt : 48|4@1+ (1,0) [0|15] ""  ESC

BO_ 356 VSM1: 8 ESC
 SG_ CF_Esc_Act : 12|1@1+ (1,0) [0|1] ""  LKAS,MDPS
 SG_ CF_Esc_Def : 16|1@1+ (1,0) [0|1] ""  MDPS
 SG_ CR_Esc_StrTqReq : 0|12@1+ (0.01,-20.48) [-20.48|20.47] "Nm"  MDPS
 SG_ CF_Esc_CtrMode : 13|3@1+ (1,0) [0|7] ""  MDPS
 SG_ CF_Esc_AliveCnt : 48|4@1+ (1,0) [0|15] ""  MDPS
 SG_ CF_Esc_Chksum : 56|8@1+ (1,0) [0|15] ""  MDPS

BO_ 339 TCS1: 8 ESC
 SG_ ABS_ACT : 10|1@1+ (1,0) [0|1] ""  _4WD,ACU,ECS,EMS,EPB,PSB_LH,PSB_RH,SPAS,TCU
 SG_ AliveCounter_TCS1 : 52|4@1+ (1,0) [0|1] ""  _4WD,EMS,EPB
 SG_ DBC_CTL : 16|1@1+ (1,0) [0|1] ""  _4WD,EPB,TCU
 SG_ DBC_DEF : 18|1@1+ (1,0) [0|1] ""  _4WD,EPB,TCU
 SG_ DBC_PAS : 17|1@1+ (1,0) [0|1] ""  _4WD,EPB,TCU
 SG_ EBD_DEF : 11|1@1+ (1,0) [0|1] ""  _4WD,EPB,PSB_LH,PSB_RH,SPAS,TCU
 SG_ ESP_CTL : 14|1@1+ (1,0) [0|1] ""  _4WD,ACU,EMS,LKAS,PSB_LH,PSB_RH,SCC,SPAS,TCU
 SG_ ESP_DEF : 13|1@1+ (1,0) [0|1] ""  _4WD,ACU,EMS,LKAS,PSB_LH,PSB_RH,SCC,TCU
 SG_ ESP_PAS : 12|1@1+ (1,0) [0|1] ""  _4WD,ACU,EMS,LKAS,PSB_LH,PSB_RH,SCC,TCU
 SG_ HAC_CTL : 19|1@1+ (1,0) [0|1] ""  _4WD,EPB,TCU
 SG_ HAC_DEF : 21|1@1+ (1,0) [0|1] ""  _4WD,EPB,TCU
 SG_ HAC_PAS : 20|1@1+ (1,0) [0|1] ""  _4WD,EPB,TCU
 SG_ TCS_CTL : 9|1@1+ (1,0) [0|1] ""  _4WD,SCC,SPAS,TCU
 SG_ TCS_DEF : 8|1@1+ (1,0) [0|1] ""  _4WD,SCC,TCU
 SG_ TCS_GSC : 3|1@1+ (1,0) [0|1] ""  _4WD,TCU
 SG_ TCS_PAS : 2|1@1+ (1,0) [0|1] ""  _4WD,SCC,TCU
 SG_ TCS_REQ : 0|1@1+ (1,0) [0|1] ""  _4WD,EPB,TCU
 SG_ TQI_MSR : 32|8@1+ (0.390625,0) [0|99.609375] "%"  _4WD,EPB,TCU
 SG_ TQI_TCS : 24|8@1+ (0.390625,0) [0|99.609375] "%"  _4WD,EPB,TCU
 SG_ ABS_DIAG : 6|1@1+ (1,0) [0|1] ""  _4WD,CLU,PSB_LH,PSB_RH
 SG_ ESS_STAT : 22|2@1+ (1,0) [0|3] ""  _4WD,CLU,EPB,IPM
 SG_ TCS_MFRN : 15|1@1+ (1,0) [0|1] ""  _4WD,EPB
 SG_ MSR_C_REQ : 1|1@1+ (1,0) [0|1] ""  _4WD,EPB,TCU
 SG_ TQI_SLW_TCS : 40|8@1+ (0.390625,0) [0|99.609375] "%"  _4WD,EPB,TCU
 SG_ ESC_OFF_STEP : 49|2@1+ (1,0) [0|3] ""  CLU
 SG_ CF_Esc_BrkCtl : 48|1@1+ (1,0) [0|1] ""  EMS
 SG_ CheckSum_TCS1 : 56|8@1+ (1,0) [0|1] ""  _4WD,EMS,EPB
 SG_ CF_Esc_LimoInfo : 4|2@1+ (1,0) [0|3] ""  _4WD,SCC
 SG_ ABS_DEF : 7|1@1+ (1,0) [0|1] ""  _4WD,ACU,EMS,SCC,SPAS,TCU

BO_ 320 YRS2: 8 YRS
 SG_ CF_Yrs_Type : 52|4@1+ (1,0) [0|15] ""  ESC
 SG_ CR_Yrs_Crc2 : 56|8@1+ (1,0) [0|255] ""  ESC
 SG_ CR_Yrs_Diag : 40|8@1+ (1,0) [0|255] ""  ESC
 SG_ CF_Yrs_ExtSysStat : 32|8@1+ (1,0) [0|255] ""  ESC
 SG_ CR_Yrs_MsgCnt2 : 48|4@1+ (1,0) [0|15] ""  ESC
 SG_ CF_Yrs_SnsStat2 : 8|8@1+ (1,0) [0|255] ""  ESC
 SG_ CF_Yrs_McuStat : 0|8@1+ (1,0) [0|255] ""  ESC

BO_ 305 YRS3: 8 YRS
 SG_ CF_Yrs_AxStat : 52|4@1+ (1,0) [0|15] ""  ESC
 SG_ CR_Yrs_MsgCnt3 : 48|4@1+ (1,0) [0|15] ""  ESC
 SG_ CR_Yrs_YawAcc : 0|16@1+ (0.125,-4096) [-4096|4095.75] "¢ª/s^2"  ESC
 SG_ CF_Yrs_AxStat : 52|4@1+ (1,0) [0|15] ""  ESC
 SG_ CR_Yrs_Crc3 : 56|8@1+ (1,0) [0|255] ""  ESC
 SG_ CR_Yrs_Ax : 32|16@1+ (0.000127465,-4.17677312) [-4.17677312|4.17651819] "g"  ESC
 SG_ CF_Yrs_YawAccStat : 20|4@1+ (1,0) [0|15] ""  ESC
 SG_ CR_Yrs_Ax : 32|16@1+ (0.000127465,-4.17677312) [-4.17677312|4.17651819] "g"  ESC
 SG_ CR_Yrs_Crc3 : 56|8@1+ (1,0) [0|255] ""  ESC
 SG_ CF_Yrs_YawAccStat : 20|4@1+ (1,0) [0|15] ""  ESC
 SG_ CR_Yrs_YawAcc : 0|16@1+ (0.125,-4096) [-4096|4095.75] "¢ª/s^2"  ESC
 SG_ CR_Yrs_MsgCnt3 : 48|4@1+ (1,0) [0|15] ""  ESC

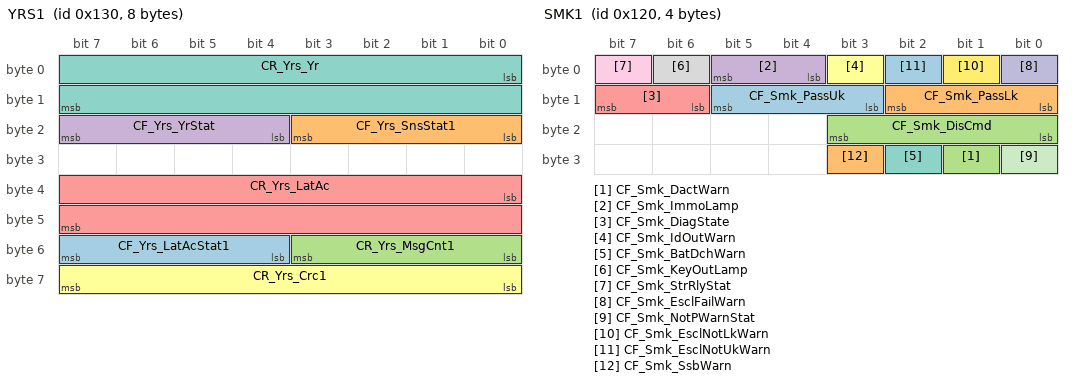
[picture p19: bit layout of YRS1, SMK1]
BO_ 304 YRS1: 8 YRS
 SG_ CF_Yrs_LatAcStat1 : 52|4@1+ (1,0) [0|15] ""  ESC
 SG_ CF_Yrs_SnsStat1 : 16|4@1+ (1,0) [0|15] ""  ESC,MTS,TMU
 SG_ CR_Yrs_MsgCnt1 : 48|4@1+ (1,0) [0|15] ""  ESC
 SG_ CF_Yrs_YrStat : 20|4@1+ (1,0) [0|15] ""  ESC,MTS,TMU
 SG_ CR_Yrs_LatAc : 32|16@1+ (0.000127465,-4.17677312) [-4.17677312|4.17651819] "g"  ESC
 SG_ CR_Yrs_Crc1 : 56|8@1+ (1,0) [0|255] ""  ESC
 SG_ CR_Yrs_Yr : 0|16@1+ (0.005,-163.84) [-163.84|163.83] "¢ª/s"  ESC,MTS,TMU

BO_ 288 SMK1: 4 SMK
 SG_ CF_Smk_PassUk : 11|3@1+ (1,0) [0|7] ""  CLU
 SG_ CF_Smk_PassLk : 8|3@1+ (1,0) [0|7] ""  CLU
 SG_ CF_Smk_DactWarn : 25|1@1+ (1,0) [0|1] ""  CLU
 SG_ CF_Smk_ImmoLamp : 4|2@1+ (1,0) [0|3] ""  CLU
 SG_ CF_Smk_DiagState : 14|2@1+ (1,0) [0|3] ""  CLU
 SG_ CF_Smk_IdOutWarn : 3|1@1+ (1,0) [0|1] ""  CLU
 SG_ CF_Smk_BatDchWarn : 26|1@1+ (1,0) [0|1] ""  CLU
 SG_ CF_Smk_KeyOutLamp : 6|1@1+ (1,0) [0|1] ""  CLU
 SG_ CF_Smk_StrRlyStat : 7|1@1+ (1,0) [0|1] ""  CLU
 SG_ CF_Smk_EsclFailWarn : 0|1@1+ (1,0) [0|1] ""  CLU
 SG_ CF_Smk_NotPWarnStat : 24|1@1+ (1,0) [0|1] ""  CLU
 SG_ CF_Smk_EsclNotLkWarn : 1|1@1+ (1,0) [0|1] ""  CLU
 SG_ CF_Smk_EsclNotUkWarn : 2|1@1+ (1,0) [0|1] ""  CLU
 SG_ CF_Smk_SsbWarn : 27|1@1+ (1,0) [0|1] ""  CLU
 SG_ CF_Smk_DisCmd : 16|4@1+ (1,0) [0|15] ""  CLU

BO_ 272 GWAY3: 8 IPM
 SG_ CF_Gway_LigCur : 6|2@1+ (1,0) [0|3] ""  CLU
 SG_ CF_Gway_SunroofOpenWarning : 23|1@1+ (1,0) [0|1] ""  CLU
 SG_ CF_Gway_ScmCur : 18|2@1+ (1,0) [0|3] ""  CLU
 SG_ CF_Gway_DrLkCur : 12|3@1+ (1,0) [0|7] ""  CLU
 SG_ CF_Gway_DrUkCur : 20|3@1+ (1,0) [0|7] ""  CLU
 SG_ CF_Gway_HAnBCur : 37|2@1+ (1,0) [0|3] ""  CLU
 SG_ CF_Gway_LDMFail : 30|2@1+ (2,0) [0|3] ""  CLU
 SG_ CF_Gway_SBLStatL : 16|1@1+ (1,0) [0|1] ""  CLU
 SG_ CF_Gway_SBLStatR : 17|1@1+ (1,0) [0|1] ""  CLU
 SG_ CF_Gway_ATTurnCur : 0|2@1+ (1,0) [0|3] ""  CLU
 SG_ CF_Gway_BrkeFluid : 36|1@1+ (1,0) [0|1] ""  CLU
 SG_ CF_Gway_BuzzerCur : 2|2@1+ (1,0) [0|3] ""  CLU
 SG_ CF_Gway_EscortCur : 4|2@1+ (1,0) [0|3] ""  CLU
 SG_ CF_Gway_PassingSW : 39|1@1+ (1,0) [0|1] ""  AFLS
 SG_ CF_Gway_RLWdwStat : 33|1@1+ (1,0) [0|1] ""  CLU
 SG_ CF_Gway_TurnUkCur : 10|2@1+ (1,0) [0|3] ""  CLU
 SG_ CF_Gway_DRVWdwStat : 32|1@1+ (1,0) [0|1] ""  CLU
 SG_ CF_Gway_HotShotIND : 40|3@1+ (1,0) [0|7] ""  CLU
 SG_ CF_Gway_MirFoldCur : 47|2@1+ (1,0) [0|3] ""  CLU
 SG_ CF_Gway_ButSysVarInd : 24|1@1+ (1,0) [0|1] ""  CLU
 SG_ CF_Gway_RRDRVWdwStat : 34|1@1+ (1,0) [0|1] ""  CLU
 SG_ CF_Gway_ASTDRVWdwStat : 35|1@1+ (1,0) [0|1] ""  CLU
 SG_ CF_Gway_PsmCur : 43|3@1+ (1,0) [0|8] ""  CLU

BO_ 161 EngFrzFrm2: 8 EMS
 SG_ PID_0Bh : 32|8@1+ (1,0) [0|255] "kPa"  TCU
 SG_ PID_09h : 24|8@1+ (0.78125,-100) [-100|99.22] "%"  TCU
 SG_ PID_08h : 16|8@1+ (0.78125,-100) [-100|99.22] "%"  TCU
 SG_ PID_07h : 8|8@1+ (0.78125,-100) [-100|99.22] "%"  TCU
 SG_ PID_06h : 0|8@1+ (0.78125,-100) [-100|99.22] "%"  TCU
 SG_ PID_23h : 40|16@1+ (10,0) [0|655350] "kPa"  TCU

BO_ 160 EngFrzFrm1: 8 EMS
 SG_ PID_0Dh : 32|8@1+ (1,0) [0|255] "km/h"  TCU
 SG_ PID_0Ch : 16|16@1+ (0.25,0) [0|16383.75] "rpm"  TCU
 SG_ PID_05h : 8|8@1+ (1,-40) [-40|215] "¡É"  TCU
 SG_ PID_04h : 0|8@1+ (0.39215686275,0) [0|100] "%"  TCU
 SG_ PID_03h : 48|16@1+ (1,0) [0|65535] ""  TCU
 SG_ PID_11h : 40|8@1+ (0.39215686275,0) [0|100] "%"  TCU

BO_ 129 EMS_DCT2: 8 EMS
 SG_ CF_Ems_EngOperStat : 8|8@1+ (1,0) [0|255] ""  TCU
 SG_ CR_Ems_IndAirTemp : 16|8@1+ (0.75,-48) [-48|143.25] "¡É"  TCU
 SG_ CF_Ems_ChkSum2 : 60|4@1+ (1,0) [0|15] ""  TCU
 SG_ CF_Ems_Alive2 : 56|4@1+ (1,0) [0|15] ""  TCU
 SG_ BRAKE_ACT : 6|2@1+ (1,0) [0|3] ""  TCU
 SG_ CR_Ems_SoakTimeExt : 0|6@1+ (5,0) [0|315] "Min"  TCU

BO_ 128 EMS_DCT1: 8 EMS
 SG_ F_SUB_TQI : 15|1@1+ (1,0) [0|1] ""  TCU
 SG_ PV_AV_CAN : 0|8@1+ (0.3906,0) [0|99.603] "%"  TCU
 SG_ CF_Ems_Alive : 56|4@1+ (1,0) [0|15] ""  TCU
 SG_ CF_Ems_ChkSum : 60|4@1+ (1,0) [0|15] ""  TCU
 SG_ TQI_ACOR : 32|8@1+ (0.390625,0) [0|99.6094] "%"  TCU
 SG_ TQ_STND : 8|6@1+ (10,0) [0|630] "Nm"  TCU
 SG_ TQ_STND : 8|6@1+ (15,0) [0|945] "Nm"  TCU
 SG_ F_N_ENG : 14|1@1+ (1,0) [0|1] ""  TCU
 SG_ TQFR : 40|8@1+ (0.390625,0) [0|99.6094] "%"  TCU
 SG_ N : 16|16@1+ (0.25,0) [0|16383.75] "rpm"  TCU
 SG_ TQI : 48|8@1+ (0.390625,0) [0|99.609375] "%"  TCU

BO_ 80 GWAY2: 4 IPM
 SG_ CF_Gway_AmpInfo : 24|2@1+ (1,0) [0|3] ""  CLU
 SG_ CF_Gway_HeadLampHighSW : 22|1@1+ (1,0) [0|1] ""  LDWS
 SG_ CF_Gway_TSigRHSW : 20|1@1+ (1,0) [0|1] ""  CLU
 SG_ CF_Gway_WiperLow : 16|1@1+ (1,0) [0|1] ""  LKAS
 SG_ CF_Gway_WiperAuto : 19|1@1+ (1,0) [0|1] ""  LKAS
 SG_ CF_Gway_WiperHigh : 18|1@1+ (1,0) [0|1] ""  LKAS
 SG_ CF_Gway_WiperIntT : 13|3@1+ (1,0) [0|7] ""  EMS,LKAS
 SG_ CF_Gway_CluModeSet : 0|2@1+ (1,0) [0|3] ""  CLU
 SG_ CF_Gway_LkasMainSW : 28|1@1+ (1,0) [0|1] ""  CLU,LKAS
 SG_ CF_Gway_WiperIntSW : 17|1@1+ (1,0) [0|1] ""  LKAS
 SG_ CF_Gway_CluGuiCtrSW : 2|6@1+ (1,0) [0|63] ""  CLU
 SG_ CF_Gway_LowLuminous : 26|2@1+ (1,0) [0|3] ""  SNV
 SG_ CF_Gway_CruiseMainSW : 29|1@1+ (1,0) [0|1] ""  EMS,LKAS
 SG_ CF_Gway_CruiseSWStat : 10|3@1+ (1,0) [0|7] ""  EMS,LKAS
 SG_ CF_Gway_WiperHighAct : 30|1@1+ (1,0) [0|1] ""  SNV
 SG_ CF_Gway_LightSWStatus : 8|2@1+ (1,0) [0|3] ""  LDWS
 SG_ CF_Gway_TSigLHSW : 21|1@1+ (1,0) [0|1] ""  CLU

BO_ 68 DATC1: 8 DATC
 SG_ CF_Datc_Type : 0|8@1+ (1,0) [0|255] ""  IPM
 SG_ CF_Datc_VerMaj : 8|8@1+ (1,0) [0|255] ""  IPM
 SG_ CF_Datc_VerMin : 16|8@1+ (1,0) [0|255] ""  IPM
 SG_ CR_Datc_OutTempC : 24|8@1+ (0.5,-41) [-41|86.5] "¡É"  IPM
 SG_ CR_Datc_OutTempF : 32|8@1+ (1,-42) [-42|213] "¡É"  IPM
 SG_ CF_Datc_IncarTemp : 40|8@1+ (0.5,-40) [-40|60] "¡É"  IPM

BO_ 67 DATC3: 8 DATC
 SG_ CF_Datc_DualDisp : 30|2@1+ (1,0) [0|3] ""  IPM
 SG_ CF_Datc_RearClimateScnDisp : 44|2@1+ (1,0) [0|3] ""  IPM
 SG_ CF_Datc_RearChgReqDisp : 46|2@1+ (1,0) [0|3] ""  IPM
 SG_ CF_Datc_AutoDefogBlink : 16|2@1+ (1,0) [0|3] ""  IPM
 SG_ CF_Datc_TempDispUnit : 0|2@1+ (1,0) [0|3] ""  IPM,TMU
 SG_ CF_Datc_RearAutoDisp : 40|2@1+ (1,0) [0|1] ""  IPM
 SG_ CF_Datc_FrontBlwDisp : 60|4@1+ (1,0) [0|15] ""  IPM
 SG_ CF_Datc_RearOffDisp : 42|2@1+ (1,0) [0|3] ""  IPM
 SG_ CF_Datc_RearBlwDisp : 52|4@1+ (1,0) [0|15] ""  IPM
 SG_ CF_Datc_OpSts : 25|3@1+ (1,0) [0|7] ""  IPM
 SG_ CF_Datc_AcDisp : 22|2@1+ (1,0) [0|3] ""  IPM
 SG_ CF_Datc_PwrInf : 32|4@1+ (1,0) [0|15] ""  IPM
 SG_ CF_Datc_AqsDisp : 20|2@1+ (1,0) [0|3] ""  IPM
 SG_ CF_Datc_ModDisp : 2|4@1+ (1,0) [0|15] ""  IPM
 SG_ CF_Datc_AutoDisp : 12|2@1+ (1,0) [0|3] ""  IPM
 SG_ CF_Datc_FrDefLed : 14|2@1+ (1,0) [0|3] ""  IPM
 SG_ CF_Datc_IonClean : 6|2@1+ (1,0) [0|3] ""  IPM
 SG_ CF_Mtc_MaxAcDisp : 28|2@1+ (1,0) [0|3] ""  IPM
 SG_ CF_Datc_ChgReqDisp : 8|2@1+ (1,0) [0|3] ""  IPM
 SG_ CF_Datc_IntakeDisp : 10|2@1+ (1,0) [0|3] ""  IPM
 SG_ CF_Datc_RearManual : 38|2@1+ (1,0) [0|3] ""  IPM
 SG_ CF_Datc_ClmScanDisp : 18|2@1+ (1,0) [0|3] ""  IPM

BO_ 66 DATC2: 8 DATC
 SG_ CR_Datc_RearDrTempDispC : 40|8@1+ (0.5,16) [17|32] "¡É"  IPM
 SG_ CR_Datc_DrTempDispF : 8|8@1+ (1,60) [62|90] "¢µ"  IPM,TMU
 SG_ CR_Datc_PsTempDispC : 16|8@1+ (0.5,16) [17|32] "¡É"  IPM,TMU
 SG_ CR_Datc_RearDrTempDispF : 48|8@1+ (1,60) [62|90] "¢µ"  IPM
 SG_ CR_Datc_DrTempDispC : 0|8@1+ (0.5,16) [17|32] "¡É"  IPM,TMU
 SG_ CR_Datc_PsTempDispF : 24|8@1+ (1,60) [62|90] "¢µ"  IPM,TMU

BO_ 64 DATC4: 8 DATC
 SG_ CR_Datc_SelfDiagCode : 8|8@1+ (1,-1) [0|254] ""  IPM
 SG_ CF_Datc_AqsLevelOut : 0|4@1+ (1,0) [0|3] ""  IPM
 SG_ CF_Datc_DiagMode : 6|2@1+ (1,0) [0|3] ""  IPM

BO_ 52 GWAY7: 8 IPM
 SG_ CF_Gway_GradeInf : 4|3@1+ (1,0) [0|7] ""  DATC,FATC,MTC
 SG_ CF_Gway_DistributeInf : 0|4@1+ (1,0) [0|15] ""  DATC,FATC,MTC
 SG_ CF_Gway_DriverInf : 7|1@1+ (1,0) [0|1] ""  CLU,DATC,FATC,MTC

BO_ 48 EMS8: 8 EMS
 SG_ CR_Ems_DutyCyc1MSV : 24|8@1+ (0.1953,0) [0|49.8] "%"  DI_BOX
 SG_ CR_Ems_DutyCyc2MSV : 32|8@1+ (0.13725,0) [0|35] "%"  DI_BOX
 SG_ CR_Ems_DutyCyc3MSV : 40|8@1+ (0.392,0) [0|100] "%"  DI_BOX
 SG_ CF_Ems_DC1NumPerMSV : 0|8@1+ (1,0) [0|255] ""  DI_BOX
 SG_ CF_Ems_DC2NumPerMSV : 8|16@1+ (1,0) [0|65535] ""  DI_BOX

BO_ 24 GWAY6: 8 IPM
 SG_ CF_Gway_TSigLHOut : 46|1@1+ (1,0) [0|1] ""  CLU
 SG_ CF_Gway_SunroofOpenWarning : 21|1@1+ (1,0) [0|1] ""  CLU
 SG_ CF_Gway_KeyReminderWarning : 40|1@1+ (1,0) [0|1] ""  CLU
 SG_ CF_Gway_KeyTeachingSound : 41|1@1+ (1,0) [0|1] ""  CLU
 SG_ CF_Gway_SeatBeltWarning : 43|1@1+ (1,0) [0|1] ""  CLU
 SG_ CF_Gway_DrvSeatBeltInd : 2|2@1+ (1,0) [0|3] ""  CLU
 SG_ CF_Gway_IgnSW : 29|3@1+ (1,0) [0|7] ""  CLU
 SG_ CF_Gway_SNVSW : 49|1@1+ (1,0) [0|1] ""  SNV
 SG_ CF_Gway_AVTail : 5|2@1+ (1,0) [0|3] ""  CLU
 SG_ CF_Gway_RLDrSW : 35|1@1+ (1,0) [0|1] ""  CLU
 SG_ CF_Gway_RRDrSW : 33|1@1+ (1,0) [0|1] ""  CLU
 SG_ CF_Gway_RkeCmd : 36|4@1+ (1,0) [0|15] ""  CLU
 SG_ CF_Gway_AstDrSW : 7|1@1+ (1,0) [0|1] ""  CLU
 SG_ CF_Gway_DrvDrSW : 4|1@1+ (1,0) [0|1] ""  CLU
 SG_ CF_Gway_PICLock : 54|3@1+ (1,0) [0|7] ""  CLU
 SG_ CF_Gway_HoodStat : 0|2@1+ (1,0) [0|3] ""  CLU
 SG_ CF_Gway_RLUnlock : 13|1@1+ (1,0) [0|1] ""  CLU
 SG_ CF_Gway_RRUnlock : 14|1@1+ (1,0) [0|1] ""  CLU
 SG_ CF_Gway_ASTUnlock : 12|1@1+ (1,0) [0|1] ""  CLU
 SG_ CF_Gway_DRVUnlock : 25|1@1+ (1,0) [0|1] ""  CLU
 SG_ CF_Gway_PICUnlock : 57|3@1+ (1,0) [0|7] ""  CLU
 SG_ CF_Gway_ParkBkeSW : 28|1@1+ (1,0) [0|1] ""  CLU
 SG_ CF_Gway_RpasOffSW : 34|1@1+ (1,0) [0|1] ""  CLU
 SG_ CF_Gway_ParkingBrakeWarning : 42|1@1+ (1,0) [0|1] ""  CLU
 SG_ CF_Gway_TSigRHOut : 45|1@1+ (1,0) [0|1] ""  CLU
 SG_ CF_Gway_TrkOpnInd : 47|1@1+ (1,0) [0|1] ""  CLU
 SG_ CF_Gway_IRLampACT : 26|1@1+ (1,0) [0|1] ""  SNV
 SG_ CF_Gway_IRLampFail : 48|1@1+ (1,0) [0|1] ""  SNV
 SG_ CF_Gway_RearFogInd : 24|1@1+ (1,0) [0|1] ""  CLU
 SG_ CF_Gway_WiperPark : 50|1@1+ (1,0) [0|1] ""  AFLS
 SG_ CF_Gway_DRVSeatBelt : 60|2@1+ (1,0) [0|3] ""  CLU
 SG_ CF_Gway_DefoggerRly : 8|1@1+ (1,0) [0|1] ""  CLU
 SG_ CF_Gway_FrontFogInd : 9|1@1+ (1,0) [0|1] ""  CLU
 SG_ CF_Gway_HLLowLHFail : 51|1@1+ (1,0) [0|1] ""  SNV
 SG_ CF_Gway_PASSeatBelt : 62|2@1+ (1,0) [0|3] ""  CLU
 SG_ CF_Gway_TailLampAct : 32|1@1+ (1,0) [0|1] ""  AVM,CLU,PGS
 SG_ CF_Gway_VehicleInfo : 10|2@1+ (1,0) [0|3] ""  CLU
 SG_ CF_Gway_DeliveryMode : 53|1@1+ (1,0) [0|1] ""  CLU
 SG_ CF_Gway_HLLowRHFail : 52|1@1+ (1,0) [0|1] ""  SNV
 SG_ CF_Gway_HeadLampHInd : 17|1@1+ (1,0) [0|1] ""  CLU
 SG_ CF_Gway_HeadLampLInd : 16|1@1+ (1,0) [0|1] ""  CLU
 SG_ CF_Gway_TeleEngState : 22|2@1+ (1,0) [0|3] ""  CLU

BO_ 21 GWAY1: 4 IPM
 SG_ CF_Gway_PBackP2Cmd : 5|1@1+ (1,0) [0|1] ""  CLU
 SG_ CF_Gway_PBackP1Cmd : 4|1@1+ (1,0) [0|1] ""  CLU
 SG_ CF_Gway_MemP2Cmd : 3|1@1+ (1,0) [0|1] ""  CLU
 SG_ CF_Gway_MemP1Cmd : 2|1@1+ (1,0) [0|1] ""  CLU
 SG_ CF_Gway_DrvKeyUk : 8|1@1+ (1,0) [0|1] ""  ECS
 SG_ CF_Gway_DrvKeyLk : 0|1@1+ (1,0) [0|1] ""  ECS

BO_ 20 CLU4: 8 CLU
 SG_ CF_Clu_EscortCurReq : 21|3@1+ (1,0) [0|7] ""  IPM
 SG_ CF_Clu_TurnUkCurReq : 38|2@1+ (1,0) [0|3] ""  IPM
 SG_ CF_Clu_LigSet : 26|3@1+ (1,0) [0|7] ""  IPM
 SG_ CF_Clu_PsmSet : 53|3@1+ (1,0) [0|7] ""  IPM
 SG_ CF_Clu_ScmSet : 46|2@1+ (1,0) [0|3] ""  IPM
 SG_ CF_Clu_DrLkSet : 13|3@1+ (1,0) [0|7] ""  IPM
 SG_ CF_Clu_DrUkSet : 8|3@1+ (1,0) [0|7] ""  IPM
 SG_ CF_Clu_HAnBSet : 34|2@1+ (1,0) [0|3] ""  IPM
 SG_ CF_Clu_TeleReq : 50|3@1+ (1,0) [0|7] ""  IPM
 SG_ CF_Clu_ATTurnSet : 40|2@1+ (1,0) [0|3] ""  IPM
 SG_ CF_Clu_BuzzerSet : 2|3@1+ (1,0) [0|7] ""  IPM
 SG_ CF_Clu_EscortSet : 18|3@1+ (1,0) [0|7] ""  IPM
 SG_ CF_Clu_LigCurReq : 29|3@1+ (1,0) [0|7] ""  IPM
 SG_ CF_Clu_PsmCurReq : 16|2@1+ (1,0) [0|3] ""  IPM
 SG_ CF_Clu_ScmCurReq : 44|2@1+ (1,0) [0|3] ""  IPM
 SG_ CF_Clu_TurnUkSet : 36|2@1+ (1,0) [0|3] ""  IPM
 SG_ CF_Clu_DrLkCurReq : 0|2@1+ (1,0) [0|3] ""  IPM
 SG_ CF_Clu_DrUkCurReq : 11|2@1+ (1,0) [0|3] ""  IPM
 SG_ CF_Clu_TeleEngReq : 48|2@1+ (1,0) [0|3] ""  IPM
 SG_ CF_Clu_ATTurnCurReq : 32|2@1+ (1,0) [0|3] ""  IPM
 SG_ CF_Clu_BuzzerCurReq : 5|3@1+ (1,0) [0|7] ""  IPM

BO_ 16 ACU3: 8 ACU
 SG_ CF_Acu_CshAct : 0|1@1+ (1,0) [0|1] ""  CUbiS,IPM,ODS,TMU

BO_ 2 ESP3: 8 ESC
 SG_ CR_Esp_Crc : 56|8@1+ (1,0) [0|255] ""  YRS
 SG_ CF_Esp_FuncDem : 16|8@1+ (1,0) [0|255] ""  YRS
 SG_ CF_Esp_DiagPtr : 40|8@1+ (1,0) [0|255] ""  YRS
 SG_ CR_Esp_MsgCnt : 48|4@1+ (1,0) [0|15] ""  YRS

BO_TX_BU_ 1984 : ECS,ESC;
BO_TX_BU_ 1680 : CLU,IPM;
BO_TX_BU_ 1352 : PAS,RPAS;
BO_TX_BU_ 1264 : CLU,IPM;
BO_TX_BU_ 1201 : ABS,ESC;
BO_TX_BU_ 688 : MDPS,SAS;
BO_TX_BU_ 288 : IPM,SMK;

CM_ SG_ 2015 FRM_FORMAT "If the value of this signal is not 2H, this signal can be ignored.*)
*) If an ECU has diagnostic communication on CAN service functionallty and communicate with an tester via CAN then must consider other message format. (DO NOT IGNORE OTHER CASES!)";
CM_ SG_ 1680 CF_Clu_ActiveEcoSW "This signal is for the Active ECO equipped vehicle only.This signal is for the Active ECO equipped vehicle only.";
CM_ SG_ 1532 CR_Ods_ID "Output period : 1000 ms until ODS_ID_Received_Flag is set to 1 in ACU1 message";
CM_ SG_ 1532 CR_Ods_RomID_L "Output period : 1000 ms until ODS_ID_Received_Flag is set to 1 in ACU1 message";
CM_ SG_ 1532 CR_Ods_RomID_H "Output period : 1000 ms until ODS_ID_Received_Flag is set to 1 in ACU1 message";
CM_ SG_ 1532 CR_Ods_Chksum_H "Output period : 1000 ms until ODS_ID_Received_Flag is set to 1 in ACU1 message";
CM_ SG_ 1532 CR_Ods_Chksum_L "Output period : 1000 ms until ODS_ID_Received_Flag is set to 1 in ACU1 message";
CM_ SG_ 1531 CR_Ods_SerNum7 "Output period : 1000 ms until ODS_ID_Received_Flag is set to 1 in ACU1 message";
CM_ SG_ 1531 CR_Ods_SerNum2 "Output period : 1000 ms until ODS_ID_Received_Flag is set to 1 in ACU1 message";
CM_ SG_ 1531 CR_Ods_SerNum1 "Output period : 1000 ms until ODS_ID_Received_Flag is set to 1 in ACU1 message";
CM_ SG_ 1531 CR_Ods_SerNum0 "Output period : 1000 ms until ODS_ID_Received_Flag is set to 1 in ACU1 message";
CM_ SG_ 1531 CR_Ods_SerNum6 "Output period : 1000 ms until ODS_ID_Received_Flag is set to 1 in ACU1 message";
CM_ SG_ 1531 CR_Ods_SerNum5 "Output period : 1000 ms until ODS_ID_Received_Flag is set to 1 in ACU1 message";
CM_ SG_ 1531 CR_Ods_SerNum4 "Output period : 1000 ms until ODS_ID_Received_Flag is set to 1 in ACU1 message";
CM_ SG_ 1531 CR_Ods_SerNum3 "Output period : 1000 ms until ODS_ID_Received_Flag is set to 1 in ACU1 message";
CM_ SG_ 1508 CF_Mdps_Flex "To broadcast MDPS steering support mode";
CM_ SG_ 1442 CF_Acu_FltStat "Transmit condition : Send ACU Diagnostic result(when crash output signal is
issued or ACU is entered to extended diagnostic mode, stop to send message)";
CM_ SG_ 1442 CF_SWL_Ind "Transmit condition : Send ACU Diagnostic result(when crash output signal is
issued or ACU is entered to extended diagnostic mode, stop to send message)";
CM_ SG_ 1442 CF_Acu_Dtc "Transmit condition : Send ACU Diagnostic result(when crash output signal is
issued or ACU is entered to extended diagnostic mode, stop to send message)
Refer to the attached file (figure)";
CM_ SG_ 1414 CF_Evp_Stat "this signal is only for case which the warning lamp is illuminated when the EVP is defective";
CM_ SG_ 1412 CF_Aaf_ActFlapStatus "Unknown : When the potentiometer or other parts are in faulty status, AAF actuator cannot recognize the position of air flaps. In this case, AAF actuator should set the value of CF_Aaf_ActFlapStatus to ¡°Unknown¡±.";
CM_ SG_ 1412 CF_Aaf_ModeStatus "Fail Safety Mode is indicated when the flap is opened by Fail Safety Mode";
CM_ SG_ 1408 ODOMETER_RIGHT "This signal will be not supported for all vehicles [started with AM ('08. 9/15)]";
CM_ SG_ 1408 ODOMETER_LEFT "This signal will be not supported for all vehicles [started with AM ('08. 9/15)]";
CM_ SG_ 1352 CF_Rpas_IndCR "*NOTE : This signal is for the ¡°HM¡± vehicle only.*NOTE : This signal is for the ¡°HM¡± vehicle only.";
CM_ SG_ 1352 CF_Fpas_IndCL "*NOTE : This signal is for the ¡°HM¡± vehicle only.*NOTE : This signal is for the ¡°HM¡± vehicle only.";
CM_ SG_ 1352 CF_Rpas_IndR "*NOTE : This signal is for the ¡°HM¡± vehicle only.*NOTE : This signal is for the ¡°HM¡± vehicle only.";
CM_ SG_ 1352 CF_Rpas_IndL "*NOTE : This signal is for the ¡°HM¡± vehicle only.*NOTE : This signal is for the ¡°HM¡± vehicle only.";
CM_ SG_ 1352 CF_Fpas_IndR "*NOTE : This signal is for the ¡°HM¡± vehicle only.*NOTE : This signal is for the ¡°HM¡± vehicle only.";
CM_ SG_ 1352 CF_Fpas_IndL "*NOTE : This signal is for the ¡°HM¡± vehicle only.*NOTE : This signal is for the ¡°HM¡± vehicle only.";
CM_ SG_ 1352 CF_Pas_SW "*NOTE : This signal is for the ¡°HM¡± vehicle only.*NOTE : This signal is for the ¡°HM¡± vehicle only.";
CM_ SG_ 1352 CF_Rpas_IndCL "*NOTE : This signal is for the ¡°HM¡± vehicle only.*NOTE : This signal is for the ¡°HM¡± vehicle only.";
CM_ SG_ 1352 CF_Fpas_IndCR "*NOTE : This signal is for the ¡°HM¡± vehicle only.*NOTE : This signal is for the ¡°HM¡± vehicle only.";
CM_ SG_ 1349 VB "In case of Delphi ECU, Output period tolerance(+1ms) will be applied to Engine Lamda3.";
CM_ SG_ 1349 FCO "In case of Delphi ECU, Output period tolerance(+1ms) will be applied to Engine Lamda3.";
CM_ SG_ 1349 L_MIL "In case of Delphi ECU, Output period tolerance(+1ms) will be applied to Engine Lamda3.";
CM_ SG_ 1349 TQI_J "In case of Delphi ECU, Output period tolerance(+1ms) will be applied to Engine Lamda3.";
CM_ SG_ 1349 AMP_CAN "In case of Delphi ECU, Output period tolerance(+1ms) will be applied to Engine Lamda3.";
CM_ SG_ 1349 IM_STAT "In case of Delphi ECU, Output period tolerance(+1ms) will be applied to Engine Lamda3.";
CM_ SG_ 1349 IM_AUTEHN "In case of Delphi ECU, Output period tolerance(+1ms) will be applied to Engine Lamda3.";
CM_ SG_ 1349 TQI_ACOR_J "In case of Delphi ECU, Output period tolerance(+1ms) will be applied to Engine Lamda3.";
CM_ SG_ 1296 CF_Gway_PasIndFIL "This signal is for ¡°IPM (Gateway)¡± applied vehicles only.";
CM_ SG_ 1296 CF_Gway_PasIndFIR "This signal is for ¡°IPM (Gateway)¡± applied vehicles only.";
CM_ SG_ 1296 CF_Gway_PasIndFOL "This signal is for ¡°IPM (Gateway)¡± applied vehicles only.";
CM_ SG_ 1296 CF_Gway_PasIndFOR "This signal is for ¡°IPM (Gateway)¡± applied vehicles only.";
CM_ SG_ 1296 CF_Gway_PasIndRIL "This signal is for ¡°IPM (Gateway)¡± applied vehicles only.";
CM_ SG_ 1296 CF_Gway_PasIndRIR "This signal is for ¡°IPM (Gateway)¡± applied vehicles only.";
CM_ SG_ 1296 CF_Gway_PasIndROL "This signal is for ¡°IPM (Gateway)¡± applied vehicles only.";
CM_ SG_ 1296 CF_Gway_PasIndROR "This signal is for ¡°IPM (Gateway)¡± applied vehicles only.";
CM_ SG_ 1296 CF_Gway_PasAlarmFR "This signal is for ¡°IPM (Gateway)¡± applied vehicles only.";
CM_ SG_ 1296 CF_Gway_PasAlarmRR "This signal is for ¡°IPM (Gateway)¡± applied vehicles only.";
CM_ SG_ 1296 CF_Gway_PasBeepAlarm "This signal is for ¡°IPM (Gateway)¡± applied vehicles only.";
CM_ SG_ 1296 CF_Gway_PasDisp "This signal is for ¡°IPM (Gateway)¡± applied vehicles only.";
CM_ SG_ 1266 Vanz "This signal is for ¡°IPM (Gateway)¡± applied vehicles only.";
CM_ SG_ 1266 CF_Clu_RheostatLvl "This signal is for ¡°IPM (Gateway)¡± applied vehicles only.
This signal has Validity with Battery (Not IGN1)";
CM_ SG_ 1266 Odometer "This signal is for ¡°IPM (Gateway)¡± applied vehicles only.";
CM_ SG_ 1266 SPEED_UNIT "This signal is for ¡°IPM (Gateway)¡± applied vehicles only.";
CM_ SG_ 1266 CF_SWL_Stat "This signal is for ¡°IPM (Gateway)¡± applied vehicles only.";
CM_ SG_ 1266 DashACCFail "This signal is for ¡°IPM (Gateway)¡± applied vehicles only.";
CM_ SG_ 1266 AliveCounter "This signal is for ¡°IPM (Gateway)¡± applied vehicles only.";
CM_ SG_ 1266 CF_Clu_SwiGearR "This signal is for ¡°IPM (Gateway)¡± applied vehicles only.";
CM_ SG_ 1266 CF_Clu_AliveCnt2 "This signal is for ¡°IPM (Gateway)¡± applied vehicles only.";
CM_ SG_ 1266 CF_Clu_AltLStatus "This signal is for ¡°IPM (Gateway)¡± applied vehicles only.";
CM_ SG_ 1266 CF_Clu_ActiveEcoSW "This signal is for ¡°IPM (Gateway)¡± applied vehicles only.";
CM_ SG_ 1266 CF_Clu_EcoDriveInf "This signal is for ¡°IPM (Gateway)¡± applied vehicles only.";
CM_ SG_ 1266 DISFail "This signal is for ¡°IPM (Gateway)¡± applied vehicles only.";
CM_ SG_ 1265 CF_Clu_FlexSteerSW "This signal is for the FlexSteer system equipped vehicle only";
CM_ SG_ 1232 _4WD_LIM_REQ "This signal is for MANDO TCS/ESC system only.";
CM_ SG_ 1200 WHL_SPD_RR "This signal is for the SCC system and higher reolution of wheel speed signal.";
CM_ SG_ 1200 WHL_SPD_RL "This signal is for the SCC system and higher reolution of wheel speed signal.";
CM_ SG_ 1200 WHL_SPD_FR "This signal is for the SCC system and higher reolution of wheel speed signal.";
CM_ SG_ 1200 WHL_SPD_FL "This signal is for the SCC system and higher reolution of wheel speed signal.";
CM_ SG_ 1151 AVH_CLU "This message is for ¡°EPB (Electric Parking Brake)¡± system applied vehicle only.";
CM_ SG_ 1151 ECD_ACT "This message is for ¡°EPB (Electric Parking Brake)¡± system applied vehicle only.";
CM_ SG_ 1151 AVH_LAMP "This message is for ¡°EPB (Electric Parking Brake)¡± system applied vehicle only.";
CM_ SG_ 1151 AVH_STAT "This message is for ¡°EPB (Electric Parking Brake)¡± system applied vehicle only.";
CM_ SG_ 1151 REQ_EPB_STAT "This message is for ¡°EPB (Electric Parking Brake)¡± system applied vehicle only.";
CM_ SG_ 1151 AVH_ALARM "This message is for ¡°EPB (Electric Parking Brake)¡± system applied vehicle only.";
CM_ SG_ 1151 AVH_I_LAMP "This message is for ¡°EPB (Electric Parking Brake)¡± system applied vehicle only.";
CM_ SG_ 1151 REQ_EPB_ACT "This message is for ¡°EPB (Electric Parking Brake)¡± system applied vehicle only.";
CM_ SG_ 1151 ROL_CNT_ESP "This message is for ¡°EPB (Electric Parking Brake)¡± system applied vehicle only.";
CM_ SG_ 1151 LDM_STAT "This message is for ¡°EPB (Electric Parking Brake)¡± system applied vehicle only.";
CM_ SG_ 1088 IDLE_UP_TCU "THIS SIGNAL IS FOR ¡°LAMBDA ENGINE¡± SYSTEM ONLY.";
CM_ SG_ 1065 FRSS "This signal is not available in a part time 4WD system and 4WD system which use propeller shaft speed.";
CM_ SG_ 1065 RRSS "This signal is not available in a part time 4WD system and 4WD system which use propeller shaft speed.";
CM_ SG_ 1065 RLSS "This signal is not available in a part time 4WD system and 4WD system which use propeller shaft speed.";
CM_ SG_ 1065 FLSS "This signal is not available in a part time 4WD system and 4WD system which use propeller shaft speed.";
CM_ SG_ 1064 _4WD_ERR "This ¨è is for the ¡°4WD ECU, MAGNA & WIA JVÞä¡± system applied vehicles only.";
CM_ SG_ 1064 CLU_DUTY "Part time 4WD system does not support this information via CAN";
CM_ SG_ 1064 _4WD_TYPE "* FF = Front engine and Front wheel driving
* FR = Front engine and Rear wheel driving";
CM_ SG_ 1056 VSetDis "This signal can be sent in km/h or MPH according to the ¡°SPEED_UNIT¡± signal (See CLU1 message).";
CM_ SG_ 914 CF_Mdps_Stat "This message is for the ¡°SPAS(Smart Parking Assist System)¡± applied vehicles only";
CM_ SG_ 914 CR_Mdps_DrvTq "This message is for the ¡°SPAS(Smart Parking Assist System)¡± applied vehicles only";
CM_ SG_ 914 CF_Mdps_Chksum "This message is for the ¡°SPAS(Smart Parking Assist System)¡± applied vehicles only";
CM_ SG_ 914 CR_Mdps_StrAng "This message is for the ¡°SPAS(Smart Parking Assist System)¡± applied vehicles only";
CM_ SG_ 914 CF_Mdps_AliveCnt "This message is for the ¡°SPAS(Smart Parking Assist System)¡± applied vehicles only";
CM_ SG_ 912 CF_Spas_Stat "This signal is for the ¡°SPAS(Smart Parking Assist System)¡± applied vehicles only.";
CM_ SG_ 912 CF_Spas_Chksum "This signal is for the ¡°SPAS(Smart Parking Assist System)¡± applied vehicles only.";
CM_ SG_ 912 CF_Spas_AliveCnt "This signal is for the ¡°SPAS(Smart Parking Assist System)¡± applied vehicles only.";
CM_ SG_ 912 CR_Spas_StrAngCmd "This signal is for the ¡°SPAS(Smart Parking Assist System)¡± applied vehicles only.";
CM_ SG_ 907 CF_Opi_Romver "Value Table is provided to HMC by Continetal for each SW version.";
CM_ SG_ 900 CF_Ems_SwiOffIC2 "This signal is for the specific engine system only. (V6/V8 GDI engine only)";
CM_ SG_ 900 CF_Ems_SwiOffIC1 "This signal is for the specific engine system only. (V6/V8 GDI engine only)";
CM_ SG_ 900 CF_Ems_DiagReqHDEV "This signal is for the specific engine system only. (V6/V8 GDI engine only)";
CM_ SG_ 900 CF_Ems_DiagFulHDEV "This signal is for the specific engine system only. (V6/V8 GDI engine only)";
CM_ SG_ 900 CR_Ems_DutyCycMSV "This signal is for the specific engine system only. (V6/V8 GDI engine only)";
CM_ SG_ 900 CF_Ems_MtGearDisp "This signal is for the specific engine system only. (V6/V8 GDI engine only)";
CM_ SG_ 900 CF_Ems_InjVBnkAct "This signal is for the specific engine system only. (V6/V8 GDI engine only)";
CM_ SG_ 900 CF_Ems_InjVActSet "This signal is for the specific engine system only. (V6/V8 GDI engine only)";
CM_ SG_ 900 CR_Ems_BatVolRly "This signal is for the specific engine system only. (V6/V8 GDI engine only)";
CM_ SG_ 900 CF_Ems_HolCurMSV "This signal is for the specific engine system only. (V6/V8 GDI engine only)";
CM_ SG_ 900 CF_Ems_PkpCurMSV "This signal is for the specific engine system only. (V6/V8 GDI engine only)";
CM_ SG_ 880 TQI_TCU_INC "This signal is valid only for the vehicle that 8th speed transmission is implemented.";
CM_ SG_ 848 CF_Fatc_CtrInf "Heater control not using CAN communication for data exchange does not send HVAC compressor type information especially.";
CM_ SG_ 816 CR_Tcu_TqDec "This message is for the ¡°DCT(Double Clutch T/M)¡± system applied vehicles only";
CM_ SG_ 816 CR_Tcu_TqInc "This message is for the ¡°DCT(Double Clutch T/M)¡± system applied vehicles only";
CM_ SG_ 816 CF_Tcu_Alive2 "This message is for the ¡°DCT(Double Clutch T/M)¡± system applied vehicles only";
CM_ SG_ 816 CF_Tcu_ChkSum2 "This message is for the ¡°DCT(Double Clutch T/M)¡± system applied vehicles only";
CM_ SG_ 816 CF_Tcu_CltStat "This message is for the ¡°DCT(Double Clutch T/M)¡± system applied vehicles only";
CM_ SG_ 816 CR_Tcu_CreepTq "This message is for the ¡°DCT(Double Clutch T/M)¡± system applied vehicles only";
CM_ SG_ 816 CF_Tcu_FuelCutReq "This message is for the ¡°DCT(Double Clutch T/M)¡± system applied vehicles only";
CM_ SG_ 816 CF_Tcu_ChgInhAC "This message is for the ¡°DCT(Double Clutch T/M)¡± system applied vehicles only";
CM_ SG_ 816 CF_Tcu_DriWarn1 "This message is for the ¡°DCT(Double Clutch T/M)¡± system applied vehicles only";
CM_ SG_ 816 CF_Tcu_DriWarn2 "This message is for the ¡°DCT(Double Clutch T/M)¡± system applied vehicles only";
CM_ SG_ 816 CF_Tcu_TqIncReq "This message is for the ¡°DCT(Double Clutch T/M)¡± system applied vehicles only
In the case of a torque increase, following conditions must be fulfilled.
CF_Tcu_TqIncReq = 1 and CR_Tcu_TqInc > 00H.";
CM_ SG_ 816 CF_Tcu_StRelStat "This message is for the ¡°DCT(Double Clutch T/M)¡± system applied vehicles only
If CAN communication is not available(eg. CAN error etc), all receivers should acknowledge Start release
NOT ready.";
CM_ SG_ 816 CR_Tcu_ShiftTq "This message is for the ¡°DCT(Double Clutch T/M)¡± system applied vehicles only";
CM_ SG_ 809 TPS "1. In diesel engine system, there is a signal relationship between TPS and PV_AV_CAN. For the details, please see PV_AV_CAN signal description page. 
2. In case of Delphi ECU, Output period tolerance(+1ms) will be applied to Engine Lamda3.";
CM_ SG_ 809 MAF_FAC_ALTI_MMV "In case of Delphi ECU, Output period tolerance(+1ms) will be applied to Engine Lamda3.";
CM_ SG_ 809 GP_CTL "1. This signal is for the diesel engine system only.
2. In case of Delphi ECU, Output period tolerance(+1ms) will be applied to Engine Lamda3.";
CM_ SG_ 809 ACC_ACT "1. There is signal relationship between ¡®ACC_ACT¡¯ and ¡®PV_AV_CAN¡¯. See ¡®PV_AV_CAN¡¯ signal description page.
2. In case of Delphi ECU, Output period tolerance(+1ms) will be applied to Engine Lamda3.";
CM_ SG_ 809 CLU_ACK "1. This signal is for the diesel engine and ISG system installed vehicles only.
2. In case of Delphi ECU, Output period tolerance(+1ms) will be applied to Engine Lamda3.";
CM_ SG_ 809 ENG_CHR "1. For the automatic variant coding at E.O.L : This signal value is valid 1.5sec later from initial IG-ON
2. In case of Delphi ECU, Output period tolerance(+1ms) will be applied to Engine Lamda3.";
CM_ SG_ 809 ENG_VOL "In case of Delphi ECU, Output period tolerance(+1ms) will be applied to Engine Lamda3.";
CM_ SG_ 809 TQ_STND "1. In case of an engine which maximum engine torque is higher than 520Nm, this factor value is 15.
2. In case of Delphi ECU, Output period tolerance(+1ms) will be applied to Engine Lamda3.";
CM_ SG_ 809 CAN_VERS "In case of Delphi ECU, Output period tolerance(+1ms) will be applied to Engine Lamda3.";
CM_ SG_ 809 CONF_TCU "1. For the automatic variant coding at E.O.L : This signal value is valid 1.5sec later from initial IG-ON
2. In case of Delphi ECU, Output period tolerance(+1ms) will be applied to Engine Lamda3.";
CM_ SG_ 809 MUL_CODE "In case of Delphi ECU, Output period tolerance(+1ms) will be applied to Engine Lamda3.";
CM_ SG_ 809 TEMP_ENG "In case of Delphi ECU, Output period tolerance(+1ms) will be applied to Engine Lamda3.";
CM_ SG_ 809 BRAKE_ACT "In case of Delphi ECU, Output period tolerance(+1ms) will be applied to Engine Lamda3.";
CM_ SG_ 809 PV_AV_CAN "In case of Delphi ECU, Output period tolerance(+1ms) will be applied to Engine Lamda3.";
CM_ SG_ 809 OD_OFF_REQ "1. This signal is available in the auto cruise control system equiped vehicles only.
2. In case of Delphi ECU, Output period tolerance(+1ms) will be applied to Engine Lamda3.";
CM_ SG_ 809 VB_OFF_ACT "1. This signal is only for the gasoline system.
2. In case of Delphi ECU, Output period tolerance(+1ms) will be applied to Engine Lamda3.";
CM_ SG_ 809 OBD_FRF_ACK "In case of Delphi ECU, Output period tolerance(+1ms) will be applied to Engine Lamda3.";
CM_ SG_ 809 CONF_MIL_FMY "1. This value represents a calibrated constant from the ECU.
2. In case of Delphi ECU, Output period tolerance(+1ms) will be applied to Engine Lamda3.";
CM_ SG_ 809 ACK_ES "In case of Delphi ECU, Output period tolerance(+1ms) will be applied to Engine Lamda3.";
CM_ SG_ 790 N "In case of Delphi ECU, Output period tolerance(+1ms) will be applied to Engine Lamda3.";
CM_ SG_ 790 VS "In case of Delphi ECU, Output period tolerance(+1ms) will be applied to Engine Lamda3.";
CM_ SG_ 790 TQI "In case of Delphi ECU, Output period tolerance(+1ms) will be applied to Engine Lamda3.";
CM_ SG_ 790 TQFR "In case of Delphi ECU, Output period tolerance(+1ms) will be applied to Engine Lamda3.";
CM_ SG_ 790 RLY_AC "In case of Delphi ECU, Output period tolerance(+1ms) will be applied to Engine Lamda3.";
CM_ SG_ 790 ACK_TCS "In case of Delphi ECU, Output period tolerance(+1ms) will be applied to Engine Lamda3.";
CM_ SG_ 790 RATIO_TQI_BAS_MAX_STND "In case of Delphi ECU, Output period tolerance(+1ms) will be applied to Engine Lamda3.";
CM_ SG_ 790 SWI_IGK "In case of Delphi ECU, Output period tolerance(+1ms) will be applied to Engine Lamda3.";
CM_ SG_ 790 PUC_STAT "In case of Delphi ECU, Output period tolerance(+1ms) will be applied to Engine Lamda3.";
CM_ SG_ 790 TQI_ACOR "In case of Delphi ECU, Output period tolerance(+1ms) will be applied to Engine Lamda3.";
CM_ SG_ 790 F_SUB_TQI "In case of Delphi ECU, Output period tolerance(+1ms) will be applied to Engine Lamda3.";
CM_ SG_ 790 TQ_COR_STAT "In case of Delphi ECU, Output period tolerance(+1ms) will be applied to Engine Lamda3.";
CM_ SG_ 790 F_N_ENG "In case of Delphi ECU, Output period tolerance(+1ms) will be applied to Engine Lamda3.";
CM_ SG_ 688 SAS_Trim "When MDPS ECU sends this message, this message value is valid 1.5 sec later from IG-ON.";
CM_ SG_ 688 SAS_CAL "When MDPS ECU sends this message, this message value is valid 1.5 sec later from IG-ON.";
CM_ SG_ 688 SAS_OK "When MDPS ECU sends this message, this message value is valid 1.5 sec later from IG-ON.";
CM_ SG_ 688 SAS_Speed "When MDPS ECU sends this message, this message value is valid 1.5 sec later from IG-ON.";
CM_ SG_ 688 SAS_Angle "When MDPS ECU sends this message, this message value is valid 1.5 sec later from IG-ON.";
CM_ SG_ 688 SAS_Stat "When MDPS ECU sends this message, this message value is valid 1.5 sec later from IG-ON.";
CM_ SG_ 688 MsgCount "When MDPS ECU sends this message, this message value is valid 1.5 sec later from IG-ON.";
CM_ SG_ 688 CheckSum "When MDPS ECU sends this message, this message value is valid 1.5 sec later from IG-ON.";
CM_ SG_ 672 STATE_DC_OBD "1. This signal is for the ¡°SCC(Smart Cruise Control)¡± system applied vehicles only
2. In case of Delphi ECU, Output period tolerance(+1ms) will be applied to Engine Lamda3.";
CM_ SG_ 672 CTR_IG_CYC_OBD "1. This signal is for the ¡°SCC(Smart Cruise Control)¡± system applied vehicles only
2. In case of Delphi ECU, Output period tolerance(+1ms) will be applied to Engine Lamda3.";
CM_ SG_ 672 SwitchOffCondExt "1. This signal is for the ¡°SCC(Smart Cruise Control)¡± system applied vehicles only
2. In case of Delphi ECU, Output period tolerance(+1ms) will be applied to Engine Lamda3.";
CM_ SG_ 672 FA_PV_CAN "1. This signal is for the ¡°SCC(Smart Cruise Control)¡± system applied vehicles only
2. In case of Delphi ECU, Output period tolerance(+1ms) will be applied to Engine Lamda3.";
CM_ SG_ 672 ECGPOvrd "1. This signal is for the ¡°SCC(Smart Cruise Control)¡± system applied vehicles only
2. In case of Delphi ECU, Output period tolerance(+1ms) will be applied to Engine Lamda3.";
CM_ SG_ 672 BLECFail "1. These signals are for the ¡°SCC(Smart Cruise Control)¡± system applied vehicles only
2. In case of Delphi ECU, Output period tolerance(+1ms) will be applied to Engine Lamda3.";
CM_ SG_ 672 INH_DC_OBD "1. This signal is for the ¡°SCC(Smart Cruise Control)¡± system applied vehicles only
2. In case of Delphi ECU, Output period tolerance(+1ms) will be applied to Engine Lamda3.";
CM_ SG_ 672 ECFail "1. This signal is for the ¡°SCC(Smart Cruise Control)¡± system applied vehicles only
2. In case of Delphi ECU, Output period tolerance(+1ms) will be applied to Engine Lamda3.";
CM_ SG_ 672 AliveCounter "1. These signals are for the ¡°SCC(Smart Cruise Control)¡± system applied vehicles only
2. In case of Delphi ECU, Output period tolerance(+1ms) will be applied to Engine Lamda3.";
CM_ SG_ 672 IntAirTemp "1. This signal is for the ¡°SCC(Smart Cruise Control)¡± system applied vehicles only
2. In case of Delphi ECU, Output period tolerance(+1ms) will be applied to Engine Lamda3.";
CM_ SG_ 672 CTR_CDN_OBD "1. This signal is for the ¡°SCC(Smart Cruise Control)¡± system applied vehicles only
2. In case of Delphi ECU, Output period tolerance(+1ms) will be applied to Engine Lamda3.";
CM_ SG_ 672 Byte0Parity "1. These signals are for the ¡°SCC(Smart Cruise Control)¡± system applied vehicles only
2. In case of Delphi ECU, Output period tolerance(+1ms) will be applied to Engine Lamda3.";
CM_ SG_ 672 QECACC "1. This signal is for the ¡°SCC(Smart Cruise Control)¡± system applied vehicles only
2. In case of Delphi ECU, Output period tolerance(+1ms) will be applied to Engine Lamda3.";
CM_ SG_ 640 AMP "1. This signal is for an LPI system only
2. In case of Delphi ECU, Output period tolerance(+1ms) will be applied to Engine Lamda3.";
CM_ SG_ 640 EOS "1. This signal is for an LPI system only
2. In case of Delphi ECU, Output period tolerance(+1ms) will be applied to Engine Lamda3.";
CM_ SG_ 640 MAF "1. This signal is for an LPI system only
2. In case of Delphi ECU, Output period tolerance(+1ms) will be applied to Engine Lamda3.";
CM_ SG_ 640 MAP "1. This signal is for an LPI system only
2. In case of Delphi ECU, Output period tolerance(+1ms) will be applied to Engine Lamda3.";
CM_ SG_ 640 TCO "1. This signal is for an LPI system only
2. In case of Delphi ECU, Output period tolerance(+1ms) will be applied to Engine Lamda3.";
CM_ SG_ 640 TIA "1. This signal is for an LPI system only
2. In case of Delphi ECU, Output period tolerance(+1ms) will be applied to Engine Lamda3.";
CM_ SG_ 640 N_32 "1. This signal is for an LPI system only
2. In case of Delphi ECU, Output period tolerance(+1ms) will be applied to Engine Lamda3.";
CM_ SG_ 640 ERR_FUEL "1. This signal is for an LPI system only
2. In case of Delphi ECU, Output period tolerance(+1ms) will be applied to Engine Lamda3.";
CM_ SG_ 640 LV_CRASH "1. This signal is for an LPI system only
2. In case of Delphi ECU, Output period tolerance(+1ms) will be applied to Engine Lamda3.";
CM_ SG_ 640 LV_GSL_MAP "1. This signal is for an LPI system only
2. In case of Delphi ECU, Output period tolerance(+1ms) will be applied to Engine Lamda3.";
CM_ SG_ 640 LV_ENG_TURN "1. This signal is for an LPI system only
2. In case of Delphi ECU, Output period tolerance(+1ms) will be applied to Engine Lamda3.";
CM_ SG_ 640 LV_BFS_CFIRM "1. This signal is for an LPI system only
2. In case of Delphi ECU, Output period tolerance(+1ms) will be applied to Engine Lamda3.";
CM_ SG_ 640 LV_VB_OFF_ACT "1. This signal is for an LPI system only
2. In case of Delphi ECU, Output period tolerance(+1ms) will be applied to Engine Lamda3.";
CM_ SG_ 640 LV_FUEL_TYPE_ECU "1. This signal is for an LPI system only
2. In case of Delphi ECU, Output period tolerance(+1ms) will be applied to Engine Lamda3.";
CM_ SG_ 625 LPI_OBD "The exact meaning of this signal and conditions that this signal is used have to be defined by the LPI interface box supplier (in accordance with the OBD regulations).";
CM_ SG_ 608 SOAK_TIME_ERROR "In case of Delphi ECU, Output period tolerance(+1ms) will be applied to Engine Lamda3.";
CM_ SG_ 608 PRE_FUEL_CUT_IN "In case of Delphi ECU, Output period tolerance(+1ms) will be applied to Engine Lamda3.";
CM_ SG_ 608 CRUISE_LAMP_S "In case of Delphi ECU, Output period tolerance(+1ms) will be applied to Engine Lamda3.";
CM_ SG_ 608 CRUISE_LAMP_M "In case of Delphi ECU, Output period tolerance(+1ms) will be applied to Engine Lamda3.";
CM_ SG_ 608 CF_Ems_AclAct "In case of Delphi ECU, Output period tolerance(+1ms) will be applied to Engine Lamda3.";
CM_ SG_ 608 SPK_TIME_CUR "In case of Delphi ECU, Output period tolerance(+1ms) will be applied to Engine Lamda3.";
CM_ SG_ 608 AliveCounter "In case of Delphi ECU, Output period tolerance(+1ms) will be applied to Engine Lamda3.";
CM_ SG_ 608 TQI_TARGET "In case of Delphi ECU, Output period tolerance(+1ms) will be applied to Engine Lamda3.";
CM_ SG_ 608 SOAK_TIME "In case of Delphi ECU, Output period tolerance(+1ms) will be applied to Engine Lamda3.";
CM_ SG_ 608 GLOW_STAT "In case of Delphi ECU, Output period tolerance(+1ms) will be applied to Engine Lamda3.";
CM_ SG_ 608 ENG_STAT "In case of Delphi ECU, Output period tolerance(+1ms) will be applied to Engine Lamda3.";
CM_ SG_ 608 Checksum "In case of Delphi ECU, Output period tolerance(+1ms) will be applied to Engine Lamda3.";
CM_ SG_ 608 TQI_MIN "In case of Delphi ECU, Output period tolerance(+1ms) will be applied to Engine Lamda3.";
CM_ SG_ 608 TQI "In case of Delphi ECU, Output period tolerance(+1ms) will be applied to Engine Lamda3.";
CM_ SG_ 608 TQI_MAX "In case of Delphi ECU, Output period tolerance(+1ms) will be applied to Engine Lamda3.";
CM_ SG_ 497 ODOMETER_RIGHT "This signal will be not supported for all vehicles [started with AM ('08. 9/15)]";
CM_ SG_ 497 ODOMETER_LEFT "This signal will be not supported for all vehicles [started with AM ('08. 9/15)]";
CM_ SG_ 496 SA_Z_FLAG "This signal is for the Non-CAN Type Streering Angle Sensor ONLY.";
CM_ SG_ 496 SA_COUNT "This signal is for the Non-CAN Type Streering Angle Sensor ONLY.";
CM_ SG_ 496 SA_Z_COUNT "This signal is for the Non-CAN Type Streering Angle Sensor ONLY.";
CM_ SG_ 399 CF_Ems_OilChg "In case of Delphi ECU, Output period tolerance(+1ms) will be applied to Engine Lamda3.";
CM_ SG_ 399 CF_Ems_EtcLimpMod "In case of Delphi ECU, Output period tolerance(+1ms) will be applied to Engine Lamda3.";
CM_ SG_ 399 CF_Ems_EngRunNorm "In case of Delphi ECU, Output period tolerance(+1ms) will be applied to Engine Lamda3.";
CM_ SG_ 399 CF_Ems_SldPosAct "In case of Delphi ECU, Output period tolerance(+1ms) will be applied to Engine Lamda3.";
CM_ SG_ 399 CF_Ems_IdlStpFCO "In case of Delphi ECU, Output period tolerance(+1ms) will be applied to Engine Lamda3.";
CM_ SG_ 399 CF_Ems_HPresStat "In case of Delphi ECU, Output period tolerance(+1ms) will be applied to Engine Lamda3.";
CM_ SG_ 399 CF_Ems_DownTarGr "In case of Delphi ECU, Output period tolerance(+1ms) will be applied to Engine Lamda3.";
CM_ SG_ 399 CF_Ems_ActEcoAct "In case of Delphi ECU, Output period tolerance(+1ms) will be applied to Engine Lamda3.";
CM_ SG_ 399 CF_Ems_IsgStat2 "In case of Delphi ECU, Output period tolerance(+1ms) will be applied to Engine Lamda3.";
CM_ SG_ 399 CF_Ems_DesCurGr "In case of Delphi ECU, Output period tolerance(+1ms) will be applied to Engine Lamda3.";
CM_ SG_ 399 CF_Ems_UpTarGr "In case of Delphi ECU, Output period tolerance(+1ms) will be applied to Engine Lamda3.";
CM_ SG_ 399 CF_Ems_IsgStat "In case of Delphi ECU, Output period tolerance(+1ms) will be applied to Engine Lamda3.";
CM_ SG_ 399 CF_Ems_SldAct "In case of Delphi ECU, Output period tolerance(+1ms) will be applied to Engine Lamda3.";
CM_ SG_ 399 CF_Ems_IsgBuz "In case of Delphi ECU, Output period tolerance(+1ms) will be applied to Engine Lamda3.";
CM_ SG_ 399 CF_Ems_FCopen "In case of Delphi ECU, Output period tolerance(+1ms) will be applied to Engine Lamda3.";
CM_ SG_ 399 R_NEngIdlTgC "In case of Delphi ECU, Output period tolerance(+1ms) will be applied to Engine Lamda3.";
CM_ SG_ 399 R_TqAcnApvC "In case of Delphi ECU, Output period tolerance(+1ms) will be applied to Engine Lamda3.";
CM_ SG_ 399 TQI_B "In case of Delphi ECU, Output period tolerance(+1ms) will be applied to Engine Lamda3.";
CM_ SG_ 399 SLD_VS "In case of Delphi ECU, Output period tolerance(+1ms) will be applied to Engine Lamda3.";
CM_ SG_ 399 R_PAcnC "In case of Delphi ECU, Output period tolerance(+1ms) will be applied to Engine Lamda3.";
CM_ SG_ 399 CF_CdaStat "In case of Delphi ECU, Output period tolerance(+1ms) will be applied to Engine Lamda3.";
CM_ SG_ 357 CR_Mdps_StrTq "PH > 0 : Left Direction (CCW)
PH < 0 : Right Direction (CW)";
CM_ SG_ 356 CR_Esc_StrTqReq "(PH) > 0 : Left Direction (CCW)
(PH) < 0 : Right Direction (CW)";
CM_ SG_ 305 CF_Yrs_AxStat "Synchronous modeAsynchronous mode";
CM_ SG_ 305 CR_Yrs_MsgCnt3 "Asynchronous modeSynchronous mode";
CM_ SG_ 305 CR_Yrs_YawAcc "Asynchronous modeSynchronous mode";
CM_ SG_ 305 CR_Yrs_Crc3 "Asynchronous modeSynchronous mode";
CM_ SG_ 305 CR_Yrs_Ax "Asynchronous modeSynchronous mode";
CM_ SG_ 305 CF_Yrs_YawAccStat "Asynchronous modeSynchronous mode";
CM_ SG_ 288 CF_Smk_PassUk "This signal is for ¡°IPM (Gateway)¡± applied vehicles only.";
CM_ SG_ 288 CF_Smk_PassLk "This signal is for ¡°IPM (Gateway)¡± applied vehicles only.";
CM_ SG_ 288 CF_Smk_DactWarn "This signal is for ¡°IPM (Gateway)¡± applied vehicles only.";
CM_ SG_ 288 CF_Smk_ImmoLamp "This signal is for ¡°IPM (Gateway)¡± applied vehicles only.";
CM_ SG_ 288 CF_Smk_DiagState "This signal is for ¡°IPM (Gateway)¡± applied vehicles only.";
CM_ SG_ 288 CF_Smk_IdOutWarn "This signal is for ¡°IPM (Gateway)¡± applied vehicles only.";
CM_ SG_ 288 CF_Smk_BatDchWarn "This signal is for ¡°IPM (Gateway)¡± applied vehicles only.";
CM_ SG_ 288 CF_Smk_KeyOutLamp "This signal is for ¡°IPM (Gateway)¡± applied vehicles only.";
CM_ SG_ 288 CF_Smk_StrRlyStat "This signal is for ¡°IPM (Gateway)¡± applied vehicles only.";
CM_ SG_ 288 CF_Smk_EsclFailWarn "This signal is for ¡°IPM (Gateway)¡± applied vehicles only.";
CM_ SG_ 288 CF_Smk_NotPWarnStat "This signal is for ¡°IPM (Gateway)¡± applied vehicles only.";
CM_ SG_ 288 CF_Smk_EsclNotLkWarn "This signal is for ¡°IPM (Gateway)¡± applied vehicles only.";
CM_ SG_ 288 CF_Smk_EsclNotUkWarn "This signal is for ¡°IPM (Gateway)¡± applied vehicles only.";
CM_ SG_ 288 CF_Smk_SsbWarn "This signal is for ¡°IPM (Gateway)¡± applied vehicles only.";
CM_ SG_ 288 CF_Smk_DisCmd "This signal is for ¡°IPM (Gateway)¡± applied vehicles only.";
CM_ SG_ 272 CF_Gway_LigCur "This signal is for ¡°IPM (Gateway)¡± applied vehicles only.";
CM_ SG_ 272 CF_Gway_SunroofOpenWarning "This signal is applied for BCM B-C Gateway vehicle.";
CM_ SG_ 272 CF_Gway_ScmCur "This signal is for ¡°IPM (Gateway)¡± applied vehicles only.";
CM_ SG_ 272 CF_Gway_DrLkCur "This signal is for ¡°IPM (Gateway)¡± applied vehicles only.";
CM_ SG_ 272 CF_Gway_DrUkCur "This signal is for ¡°IPM (Gateway)¡± applied vehicles only.";
CM_ SG_ 272 CF_Gway_LDMFail "This signal is for ¡°IPM (Gateway)¡± applied vehicles only.";
CM_ SG_ 272 CF_Gway_SBLStatL "This signal is for ¡°IPM (Gateway)¡± applied vehicles only.";
CM_ SG_ 272 CF_Gway_SBLStatR "This signal is for ¡°IPM (Gateway)¡± applied vehicles only.";
CM_ SG_ 272 CF_Gway_ATTurnCur "This signal is for ¡°IPM (Gateway)¡± applied vehicles only.";
CM_ SG_ 272 CF_Gway_BuzzerCur "This signal is for ¡°IPM (Gateway)¡± applied vehicles only.";
CM_ SG_ 272 CF_Gway_EscortCur "This signal is for ¡°IPM (Gateway)¡± applied vehicles only.";
CM_ SG_ 272 CF_Gway_TurnUkCur "This signal is for ¡°IPM (Gateway)¡± applied vehicles only.";
CM_ SG_ 272 CF_Gway_ButSysVarInd "This signal is for BCM B-C CAN Gateway vehicle.";
CM_ SG_ 272 CF_Gway_PsmCur "This signal is for ¡°IPM (Gateway)¡± applied vehicles only.";
CM_ SG_ 160 PID_04h "See PID 43h of SAE J1979 for an additional definition of engine load";
CM_ SG_ 160 PID_03h "Fuel systems do not normally refer to injector banks. Fuel systems are intended to represent completely different fuel systems that can independently enter and exit closed loop fuel. Banks of injectors on a V-engine are generally not independent and share the same closed-loop enablement criteria.";
CM_ SG_ 160 PID_11h "See PID 45h of SAE J1979 for a definition of Relative Throttle Position";
CM_ SG_ 129 CF_Ems_EngOperStat "1. This signal is for the ¡°Bosch Gasoline EMS for LuK DCT(Double Clutch T/M)¡± system
applied vehicles only.
2. This signa is same as EOS in EMS3 message. ";
CM_ SG_ 129 CR_Ems_IndAirTemp "1. This signal is for the ¡°Bosch Gasoline EMS for LuK DCT(Double Clutch T/M)¡± system
applied vehicles only.
2. This signal is same as TIA in EMS3 message.";
CM_ SG_ 129 CF_Ems_ChkSum2 "This signal is for the ¡°Bosch Gasoline EMS for LuK DCT(Double Clutch T/M)¡± system
applied vehicles only.";
CM_ SG_ 129 CF_Ems_Alive2 "This signal is for the ¡°Bosch Gasoline EMS for LuK DCT(Double Clutch T/M)¡± system
applied vehicles only.";
CM_ SG_ 129 BRAKE_ACT "This signal is for the ¡°Bosch Gasoline EMS for LuK DCT(Double Clutch T/M)¡± system
applied vehicles only.";
CM_ SG_ 129 CR_Ems_SoakTimeExt "This signal is for the ¡°Bosch Gasoline EMS for LuK DCT(Double Clutch T/M)¡± system
applied vehicles only.";
CM_ SG_ 128 F_SUB_TQI "This signal is for the ¡°Bosch Gasoline EMS for LuK DCT(Double Clutch T/M)¡± system
applied vehicles only.";
CM_ SG_ 128 PV_AV_CAN "This signal is for the ¡°Bosch Gasoline EMS for LuK DCT(Double Clutch T/M)¡± system
applied vehicles only.";
CM_ SG_ 128 CF_Ems_Alive "This signal is for the ¡°Bosch Gasoline EMS for LuK DCT(Double Clutch T/M)¡± system
applied vehicles only.";
CM_ SG_ 128 CF_Ems_ChkSum "This signal is for the ¡°Bosch Gasoline EMS for LuK DCT(Double Clutch T/M)¡± system
applied vehicles only.";
CM_ SG_ 128 TQI_ACOR "This signal is for the ¡°Bosch Gasoline EMS for LuK DCT(Double Clutch T/M)¡± system
applied vehicles only.";
CM_ SG_ 128 TQ_STND "This signal is for the ¡°Bosch Gasoline EMS for LuK DCT(Double Clutch T/M)¡± system
applied vehicles only.This signal is for the ¡°Bosch Gasoline EMS for LuK DCT(Double Clutch T/M)¡± system
applied vehicles only.";
CM_ SG_ 128 F_N_ENG "This signal is for the ¡°Bosch Gasoline EMS for LuK DCT(Double Clutch T/M)¡± system
applied vehicles only.";
CM_ SG_ 128 TQFR "This signal is for the ¡°Bosch Gasoline EMS for LuK DCT(Double Clutch T/M)¡± system
applied vehicles only.";
CM_ SG_ 128 N "This signal is for the ¡°Bosch Gasoline EMS for LuK DCT(Double Clutch T/M)¡± system
applied vehicles only.";
CM_ SG_ 128 TQI "This signal is for the ¡°Bosch Gasoline EMS for LuK DCT(Double Clutch T/M)¡± system
applied vehicles only.";
CM_ SG_ 80 CF_Gway_AmpInfo "This signal is for ¡°IPM (Gateway)¡± applied vehicles only.";
CM_ SG_ 80 CF_Gway_HeadLampHighSW "This signal is for ¡°IPM (Gateway)¡± applied vehicles only.";
CM_ SG_ 80 CF_Gway_TSigRHSW "This signal is for ¡°IPM (Gateway)¡± applied vehicles only.";
CM_ SG_ 80 CF_Gway_WiperLow "This signal is for ¡°IPM (Gateway)¡± applied vehicles only.";
CM_ SG_ 80 CF_Gway_WiperAuto "This signal is for ¡°IPM (Gateway)¡± applied vehicles only.";
CM_ SG_ 80 CF_Gway_WiperHigh "This signal is for ¡°IPM (Gateway)¡± applied vehicles only.";
CM_ SG_ 80 CF_Gway_WiperIntT "This signal is for ¡°IPM (Gateway)¡± applied vehicles only.";
CM_ SG_ 80 CF_Gway_CluModeSet "This signal is for ¡°IPM (Gateway)¡± applied vehicles only.";
CM_ SG_ 80 CF_Gway_LkasMainSW "This signal is for ¡°IPM (Gateway)¡± applied vehicles only.";
CM_ SG_ 80 CF_Gway_WiperIntSW "This signal is for ¡°IPM (Gateway)¡± applied vehicles only.";
CM_ SG_ 80 CF_Gway_CluGuiCtrSW "This signal is for ¡°IPM (Gateway)¡± applied vehicles only.";
CM_ SG_ 80 CF_Gway_CruiseMainSW "This signal is for ¡°IPM (Gateway)¡± applied vehicles only.";
CM_ SG_ 80 CF_Gway_CruiseSWStat "This signal is for ¡°IPM (Gateway)¡± applied vehicles only.";
CM_ SG_ 80 CF_Gway_LightSWStatus "This signal is for ¡°IPM (Gateway)¡± applied vehicles only.";
CM_ SG_ 80 CF_Gway_TSigLHSW "This signal is for ¡°IPM (Gateway)¡± applied vehicles only.";
CM_ SG_ 68 CF_Datc_Type "This signal is for ¡°IPM (Gateway)¡± applied vehicles only.";
CM_ SG_ 68 CF_Datc_VerMaj "This signal is for ¡°IPM (Gateway)¡± applied vehicles only.";
CM_ SG_ 68 CF_Datc_VerMin "This signal is for ¡°IPM (Gateway)¡± applied vehicles only.";
CM_ SG_ 68 CR_Datc_OutTempC "This signal is for ¡°IPM (Gateway)¡± applied vehicles only.";
CM_ SG_ 68 CR_Datc_OutTempF "This signal is for ¡°IPM (Gateway)¡± applied vehicles only.";
CM_ SG_ 67 CF_Datc_DualDisp "This signal is for ¡°IPM (Gateway)¡± applied vehicles only.";
CM_ SG_ 67 CF_Datc_AutoDefogBlink "This signal is for ¡°IPM (Gateway)¡± applied vehicles only.";
CM_ SG_ 67 CF_Datc_TempDispUnit "This signal is for ¡°IPM (Gateway)¡± applied vehicles only.";
CM_ SG_ 67 CF_Datc_FrontBlwDisp "This signal is for ¡°IPM (Gateway)¡± applied vehicles only.";
CM_ SG_ 67 CF_Datc_RearBlwDisp "This signal is for ¡°IPM (Gateway)¡± applied vehicles only.";
CM_ SG_ 67 CF_Datc_OpSts "This signal is for ¡°IPM (Gateway)¡± applied vehicles only.";
CM_ SG_ 67 CF_Datc_AcDisp "This signal is for ¡°IPM (Gateway)¡± applied vehicles only.";
CM_ SG_ 67 CF_Datc_PwrInf "This signal is for ¡°IPM (Gateway)¡± applied vehicles only.";
CM_ SG_ 67 CF_Datc_AqsDisp "This signal is for ¡°IPM (Gateway)¡± applied vehicles only.";
CM_ SG_ 67 CF_Datc_ModDisp "This signal is for ¡°IPM (Gateway)¡± applied vehicles only.";
CM_ SG_ 67 CF_Datc_AutoDisp "This signal is for ¡°IPM (Gateway)¡± applied vehicles only.";
CM_ SG_ 67 CF_Datc_FrDefLed "This signal is for ¡°IPM (Gateway)¡± applied vehicles only.";
CM_ SG_ 67 CF_Datc_IonClean "This signal is for ¡°IPM (Gateway)¡± applied vehicles only.";
CM_ SG_ 67 CF_Mtc_MaxAcDisp "This signal is for ¡°IPM (Gateway)¡± applied vehicles only.";
CM_ SG_ 67 CF_Datc_ChgReqDisp "This signal is for ¡°IPM (Gateway)¡± applied vehicles only.";
CM_ SG_ 67 CF_Datc_IntakeDisp "This signal is for ¡°IPM (Gateway)¡± applied vehicles only.";
CM_ SG_ 67 CF_Datc_RearManual "This signal is for ¡°IPM (Gateway)¡± applied vehicles only.";
CM_ SG_ 67 CF_Datc_ClmScanDisp "This signal is for ¡°IPM (Gateway)¡± applied vehicles only.";
CM_ SG_ 66 CR_Datc_DrTempDispF "This signal is for ¡°IPM (Gateway)¡± applied vehicles only.";
CM_ SG_ 66 CR_Datc_PsTempDispC "This signal is for ¡°IPM (Gateway)¡± applied vehicles only.";
CM_ SG_ 66 CR_Datc_DrTempDispC "This signal is for ¡°IPM (Gateway)¡± applied vehicles only.";
CM_ SG_ 66 CR_Datc_PsTempDispF "This signal is for ¡°IPM (Gateway)¡± applied vehicles only.";
CM_ SG_ 64 CR_Datc_SelfDiagCode "This signal is for ¡°IPM (Gateway)¡± applied vehicles only.";
CM_ SG_ 64 CF_Datc_DiagMode "This signal is for ¡°IPM (Gateway)¡± applied vehicles only.";
CM_ SG_ 52 CF_Gway_GradeInf "This signal is for ¡°IPM (Gateway)¡± applied vehicles only.";
CM_ SG_ 52 CF_Gway_DistributeInf "This signal is for ¡°IPM (Gateway)¡± applied vehicles only.";
CM_ SG_ 52 CF_Gway_DriverInf "This signal is for ¡°IPM (Gateway)¡± applied vehicles only.";
CM_ SG_ 48 CR_Ems_DutyCyc1MSV "1. This signal is for the ¡°DI_BOX(Direction Injection interface BOX)¡± applied vehicles only.
2. This signal output period can be changed according to the engine RPM.";
CM_ SG_ 48 CR_Ems_DutyCyc2MSV "1. This signal is for the ¡°DI_BOX(Direction Injection interface BOX)¡± applied vehicles only.
2. This signal output period can be changed according to the engine RPM.";
CM_ SG_ 48 CR_Ems_DutyCyc3MSV "1. This signal is for the ¡°DI_BOX(Direction Injection interface BOX)¡± applied vehicles only.
2. This signal output period can be changed according to the engine RPM.";
CM_ SG_ 48 CF_Ems_DC1NumPerMSV "1. This signal is for the ¡°DI_BOX(Direction Injection interface BOX)¡± applied vehicles only.
2. This signal output period can be changed according to the engine RPM.";
CM_ SG_ 48 CF_Ems_DC2NumPerMSV "1. This signal is for the ¡°DI_BOX(Direction Injection interface BOX)¡± applied vehicles only.
2. This signal output period can be changed according to the engine RPM.";
CM_ SG_ 24 CF_Gway_TSigLHOut "This signal is for ¡°IPM (Gateway)¡± applied vehicles only.";
CM_ SG_ 24 CF_Gway_KeyReminderWarning "This signal is for ¡°IPM (Gateway)¡± applied vehicles only.";
CM_ SG_ 24 CF_Gway_KeyTeachingSound "This signal is for ¡°IPM (Gateway)¡± applied vehicles only.";
CM_ SG_ 24 CF_Gway_SeatBeltWarning "This signal is for ¡°IPM (Gateway)¡± applied vehicles only.";
CM_ SG_ 24 CF_Gway_DrvSeatBeltInd "This signal is for ¡°IPM (Gateway)¡± applied vehicles only.";
CM_ SG_ 24 CF_Gway_IgnSW "This signal is for ¡°IPM (Gateway)¡± applied vehicles only.";
CM_ SG_ 24 CF_Gway_AVTail "This signal is for ¡°IPM (Gateway)¡± applied vehicles only.";
CM_ SG_ 24 CF_Gway_RLDrSW "This signal is for ¡°IPM (Gateway)¡± applied vehicles only.";
CM_ SG_ 24 CF_Gway_RRDrSW "This signal is for ¡°IPM (Gateway)¡± applied vehicles only.";
CM_ SG_ 24 CF_Gway_RkeCmd "This signal is for ¡°IPM (Gateway)¡± applied vehicles only.";
CM_ SG_ 24 CF_Gway_AstDrSW "This signal is for ¡°IPM (Gateway)¡± applied vehicles only.";
CM_ SG_ 24 CF_Gway_DrvDrSW "This signal is for ¡°IPM (Gateway)¡± applied vehicles only.";
CM_ SG_ 24 CF_Gway_ParkBkeSW "This signal is for ¡°IPM (Gateway)¡± applied vehicles only.";
CM_ SG_ 24 CF_Gway_RpasOffSW "This signal is for ¡°IPM (Gateway)¡± applied vehicles only.";
CM_ SG_ 24 CF_Gway_ParkingBrakeWarning "This signal is for ¡°IPM (Gateway)¡± applied vehicles only.";
CM_ SG_ 24 CF_Gway_TSigRHOut "This signal is for ¡°IPM (Gateway)¡± applied vehicles only.";
CM_ SG_ 24 CF_Gway_TrkOpnInd "This signal is for ¡°IPM (Gateway)¡± applied vehicles only.";
CM_ SG_ 24 CF_Gway_RearFogInd "This signal is for ¡°IPM (Gateway)¡± applied vehicles only.";
CM_ SG_ 24 CF_Gway_FrontFogInd "This signal is for ¡°IPM (Gateway)¡± applied vehicles only.";
CM_ SG_ 24 CF_Gway_TailLampAct "This signal is for ¡°IPM (Gateway)¡± applied vehicles only.";
CM_ SG_ 24 CF_Gway_HeadLampHInd "This signal is for ¡°IPM (Gateway)¡± applied vehicles only.";
CM_ SG_ 24 CF_Gway_HeadLampLInd "This signal is for ¡°IPM (Gateway)¡± applied vehicles only.";
CM_ SG_ 21 CF_Gway_DrvKeyUk "This signal is for ¡°IPM (Gateway)¡± applied vehicles only.";
CM_ SG_ 21 CF_Gway_DrvKeyLk "This signal is for ¡°IPM (Gateway)¡± applied vehicles only.";
CM_ SG_ 20 CF_Clu_EscortCurReq "This signal is for ¡°IPM (Gateway)¡± applied vehicles only.
When this signal change, the message (CLU4) is sent 3 times.";
CM_ SG_ 20 CF_Clu_TurnUkCurReq "This signal is for ¡°IPM (Gateway)¡± applied vehicles only.
When this signal change, the message (CLU4) is sent 3 times.";
CM_ SG_ 20 CF_Clu_LigSet "This signal is for ¡°IPM (Gateway)¡± applied vehicles only.
When this signal change, the message (CLU4) is sent 3 times.";
CM_ SG_ 20 CF_Clu_PsmSet "This signal is for ¡°IPM (Gateway)¡± applied vehicles only.
When this signal change, the message (CLU4) is sent 3 times.";
CM_ SG_ 20 CF_Clu_ScmSet "This signal is for ¡°IPM (Gateway)¡± applied vehicles only.
When this signal change, the message (CLU4) is sent 3 times.";
CM_ SG_ 20 CF_Clu_DrLkSet "This signal is for ¡°IPM (Gateway)¡± applied vehicles only.
When this signal change, the message (CLU4) is sent 3 times.";
CM_ SG_ 20 CF_Clu_DrUkSet "This signal is for ¡°IPM (Gateway)¡± applied vehicles only.
When this signal change, the message (CLU4) is sent 3 times.";
CM_ SG_ 20 CF_Clu_ATTurnSet "This signal is for ¡°IPM (Gateway)¡± applied vehicles only.
When this signal change, the message (CLU4) is sent 3 times.";
CM_ SG_ 20 CF_Clu_BuzzerSet "This signal is for ¡°IPM (Gateway)¡± applied vehicles only.
When this signal change, the message (CLU4) is sent 3 times.";
CM_ SG_ 20 CF_Clu_EscortSet "This signal is for ¡°IPM (Gateway)¡± applied vehicles only.
When this signal change, the message (CLU4) is sent 3 times.";
CM_ SG_ 20 CF_Clu_LigCurReq "This signal is for ¡°IPM (Gateway)¡± applied vehicles only.
When this signal change, the message (CLU4) is sent 3 times.";
CM_ SG_ 20 CF_Clu_PsmCurReq "This signal is for ¡°IPM (Gateway)¡± applied vehicles only.
When this signal change, the message (CLU4) is sent 3 times.";
CM_ SG_ 20 CF_Clu_ScmCurReq "This signal is for ¡°IPM (Gateway)¡± applied vehicles only.
When this signal change, the message (CLU4) is sent 3 times.";
CM_ SG_ 20 CF_Clu_TurnUkSet "This signal is for ¡°IPM (Gateway)¡± applied vehicles only.
When this signal change, the message (CLU4) is sent 3 times.";
CM_ SG_ 20 CF_Clu_DrLkCurReq "This signal is for ¡°IPM (Gateway)¡± applied vehicles only.
When this signal change, the message (CLU4) is sent 3 times.";
CM_ SG_ 20 CF_Clu_DrUkCurReq "This signal is for ¡°IPM (Gateway)¡± applied vehicles only.
When this signal change, the message (CLU4) is sent 3 times.";
CM_ SG_ 20 CF_Clu_ATTurnCurReq "This signal is for ¡°IPM (Gateway)¡± applied vehicles only.
When this signal change, the message (CLU4) is sent 3 times.";
CM_ SG_ 20 CF_Clu_BuzzerCurReq "This signal is for ¡°IPM (Gateway)¡± applied vehicles only.
When this signal change, the message (CLU4) is sent 3 times.";
BA_DEF_  "Baudrate" INT 50000 1000000;
BA_DEF_ SG_  "GenSigSendType" ENUM  "Cyclic","OnWrite","OnWriteWithRepetition","OnChange","OnChangeWithRepetition","IfActive","IfActiveWithRepetition","NoSigSendType";
BA_DEF_  "BusType" STRING ;
BA_DEF_  "DBName" STRING ;
BA_DEF_ BO_  "GenMsgCycleTime" INT 2 50000;
BA_DEF_ BO_  "GenMsgDelayTime" INT 1 1000;
BA_DEF_ BO_  "GenMsgNrOfRepetitions" INT 1 999999;
BA_DEF_ BO_  "GenMsgSendType" ENUM  "cyclic","spontaneous","cyclicIfActive","spontaneousWithDelay","cyclicAndSpontaneous","cyclicAndSpontaneousWithDelay","spontaneousWithRepetition","cyclicIfActiveAndSpontaneousWD";
BA_DEF_ SG_  "GenSigStartValue" FLOAT 0 1E+011;
BA_DEF_DEF_  "Baudrate" 500000;
BA_DEF_DEF_  "GenSigSendType" "NoSigSendType";
BA_DEF_DEF_  "BusType" "CAN";
BA_DEF_DEF_  "DBName" "";
BA_DEF_DEF_  "GenMsgCycleTime" 10;
BA_DEF_DEF_  "GenMsgDelayTime" 1;
BA_DEF_DEF_  "GenMsgNrOfRepetitions" 3;
BA_DEF_DEF_  "GenMsgSendType" "cyclic";
BA_DEF_DEF_  "GenSigStartValue" 0;
BA_ "DBName" "PassengerCars_V192";
BA_ "GenMsgSendType" BO_ 2015 1;
BA_ "GenMsgSendType" BO_ 1984 1;
BA_ "GenMsgCycleTime" BO_ 1680 100;
BA_ "GenMsgCycleTime" BO_ 1616 100;
BA_ "GenMsgCycleTime" BO_ 1552 100;
BA_ "GenMsgCycleTime" BO_ 1532 1000;
BA_ "GenMsgCycleTime" BO_ 1531 1000;
BA_ "GenMsgCycleTime" BO_ 1530 1000;
BA_ "GenMsgCycleTime" BO_ 1524 100;
BA_ "GenMsgCycleTime" BO_ 1523 100;
BA_ "GenMsgCycleTime" BO_ 1520 200;
BA_ "GenMsgCycleTime" BO_ 1508 100;
BA_ "GenMsgCycleTime" BO_ 1504 50;
BA_ "GenMsgCycleTime" BO_ 1461 50;
BA_ "GenMsgCycleTime" BO_ 1442 1000;
BA_ "GenMsgCycleTime" BO_ 1441 1000;
BA_ "GenMsgCycleTime" BO_ 1440 1000;
BA_ "GenMsgCycleTime" BO_ 1437 300;
BA_ "GenMsgCycleTime" BO_ 1435 100;
BA_ "GenMsgCycleTime" BO_ 1419 100;
BA_ "GenMsgCycleTime" BO_ 1417 100;
BA_ "GenMsgCycleTime" BO_ 1415 100;
BA_ "GenMsgCycleTime" BO_ 1414 100;
BA_ "GenMsgCycleTime" BO_ 1412 100;
BA_ "GenMsgCycleTime" BO_ 1411 100;
BA_ "GenMsgCycleTime" BO_ 1408 20;
BA_ "GenMsgCycleTime" BO_ 1378 100;
BA_ "GenMsgCycleTime" BO_ 1365 100;
BA_ "GenMsgCycleTime" BO_ 1362 100;
BA_ "GenMsgCycleTime" BO_ 1352 100;
BA_ "GenMsgCycleTime" BO_ 1350 100;
BA_ "GenMsgCycleTime" BO_ 1296 100;
BA_ "GenMsgCycleTime" BO_ 1288 50;
BA_ "GenMsgCycleTime" BO_ 1286 50;
BA_ "GenMsgCycleTime" BO_ 1285 50;
BA_ "GenMsgCycleTime" BO_ 1266 20;
BA_ "GenMsgCycleTime" BO_ 1265 100;
BA_ "GenMsgCycleTime" BO_ 1264 20;
BA_ "GenMsgCycleTime" BO_ 1232 20;
BA_ "GenMsgCycleTime" BO_ 1201 20;
BA_ "GenMsgCycleTime" BO_ 1200 20;
BA_ "GenMsgCycleTime" BO_ 1151 20;
BA_ "GenMsgCycleTime" BO_ 1075 50;
BA_ "GenMsgCycleTime" BO_ 1072 20;
BA_ "GenMsgCycleTime" BO_ 1065 20;
BA_ "GenMsgCycleTime" BO_ 1064 20;
BA_ "GenMsgCycleTime" BO_ 1056 20;
BA_ "GenMsgCycleTime" BO_ 1017 20;
BA_ "GenMsgCycleTime" BO_ 928 50;
BA_ "GenMsgCycleTime" BO_ 914 20;
BA_ "GenMsgCycleTime" BO_ 912 20;
BA_ "GenMsgCycleTime" BO_ 907 20;
BA_ "GenMsgCycleTime" BO_ 904 20;
BA_ "GenMsgCycleTime" BO_ 901 20;
BA_ "GenMsgCycleTime" BO_ 900 100;
BA_ "GenMsgCycleTime" BO_ 898 20;
BA_ "GenMsgCycleTime" BO_ 896 20;
BA_ "GenMsgCycleTime" BO_ 848 20;
BA_ "GenMsgCycleTime" BO_ 704 100;
BA_ "GenMsgCycleTime" BO_ 497 20;
BA_ "GenMsgCycleTime" BO_ 496 20;
BA_ "GenMsgCycleTime" BO_ 305 20;
BA_ "GenMsgCycleTime" BO_ 288 200;
BA_ "GenMsgSendType" BO_ 288 4;
BA_ "GenMsgCycleTime" BO_ 272 100;
BA_ "GenMsgSendType" BO_ 272 4;
BA_ "GenMsgCycleTime" BO_ 161 100;
BA_ "GenMsgCycleTime" BO_ 160 100;
BA_ "GenMsgCycleTime" BO_ 80 200;
BA_ "GenMsgSendType" BO_ 80 4;
BA_ "GenMsgCycleTime" BO_ 68 1000;
BA_ "GenMsgSendType" BO_ 68 4;
BA_ "GenMsgCycleTime" BO_ 67 1000;
BA_ "GenMsgSendType" BO_ 67 4;
BA_ "GenMsgCycleTime" BO_ 66 1000;
BA_ "GenMsgSendType" BO_ 66 4;
BA_ "GenMsgCycleTime" BO_ 64 200;
BA_ "GenMsgSendType" BO_ 64 4;
BA_ "GenMsgCycleTime" BO_ 52 1000;
BA_ "GenMsgSendType" BO_ 52 4;
BA_ "GenMsgCycleTime" BO_ 48 20;
BA_ "GenMsgSendType" BO_ 48 4;
BA_ "GenMsgCycleTime" BO_ 24 200;
BA_ "GenMsgSendType" BO_ 24 4;
BA_ "GenMsgSendType" BO_ 21 1;
BA_ "GenMsgSendType" BO_ 20 1;
BA_ "GenMsgSendType" BO_ 16 1;
BA_ "GenSigStartValue" SG_ 1984 SAS_CID 688;
BA_ "GenSigStartValue" SG_ 1552 GPLG3_STAT 15;
BA_ "GenSigStartValue" SG_ 1552 GPLG4_STAT 15;
BA_ "GenSigStartValue" SG_ 1552 GPLG5_STAT 15;
BA_ "GenSigStartValue" SG_ 1552 GPLG6_STAT 15;
BA_ "GenSigStartValue" SG_ 1552 GPC_OT_STAT 3;
BA_ "GenSigStartValue" SG_ 1552 GPC_OV_STAT 3;
BA_ "GenSigStartValue" SG_ 1552 GPC_SW_COND 3;
BA_ "GenSigStartValue" SG_ 1552 GPC_SW_OPEN 3;
BA_ "GenSigStartValue" SG_ 1552 GPC_TO_STAT 3;
BA_ "GenSigStartValue" SG_ 1552 GPC_UV_STAT 3;
BA_ "GenSigStartValue" SG_ 1552 GPLG2_STAT 15;
BA_ "GenSigStartValue" SG_ 1552 GPLG1_STAT 15;
BA_ "GenSigStartValue" SG_ 1552 GPCM_CTRL 15;
BA_ "GenSigStartValue" SG_ 1552 GPCM_ERROR 15;
BA_ "GenSigStartValue" SG_ 1508 CF_Mdps_Flex 3;
BA_ "GenSigStartValue" SG_ 1461 ACC_ObjDist 2047;
BA_ "GenSigStartValue" SG_ 1461 ACC_ObjStatus 3;
BA_ "GenSigStartValue" SG_ 1461 ACC_ObjRelSpd 4095;
BA_ "GenSigStartValue" SG_ 1461 ACC_ObjLatPos 511;
BA_ "GenSigStartValue" SG_ 1442 CF_Acu_ExtOfSab 1;
BA_ "GenSigStartValue" SG_ 1435 CR_Tcu_GearSelDisp2 9;
BA_ "GenSigStartValue" SG_ 1412 CF_Aaf_SolFlapStatus 1;
BA_ "GenSigStartValue" SG_ 1412 CF_Aaf_ActFlapStatus 1;
BA_ "GenSigStartValue" SG_ 1411 CF_Cubis_HUDisp 15;
BA_ "GenSigStartValue" SG_ 1349 AMP_CAN 28;
BA_ "GenSigStartValue" SG_ 1232 _4WD_TQC_LIM 64255;
BA_ "GenSigStartValue" SG_ 1088 ETL_TCU 255;
BA_ "GenSigStartValue" SG_ 1088 SPK_RTD_TCU 255;
BA_ "GenSigStartValue" SG_ 1087 TEMP_AT 255;
BA_ "GenSigStartValue" SG_ 1087 TQI_TCU 255;
BA_ "GenSigStartValue" SG_ 1087 G_SEL_DISP 9;
BA_ "GenSigStartValue" SG_ 1075 EPB_FAIL 2;
BA_ "GenSigStartValue" SG_ 1075 EPB_FORCE 1000;
BA_ "GenSigStartValue" SG_ 1065 CLU_PRES 800;
BA_ "GenSigStartValue" SG_ 1065 Ster_Pos 600;
BA_ "GenSigStartValue" SG_ 1017 Height_FL 128;
BA_ "GenSigStartValue" SG_ 1017 Height_RR 128;
BA_ "GenSigStartValue" SG_ 1017 Height_RL 128;
BA_ "GenSigStartValue" SG_ 1017 Height_FR 128;
BA_ "GenSigStartValue" SG_ 914 CF_Mdps_Stat 1;
BA_ "GenSigStartValue" SG_ 914 CR_Mdps_DrvTq 2048;
BA_ "GenSigStartValue" SG_ 912 CF_Spas_Stat 1;
BA_ "GenSigStartValue" SG_ 898 CF_Ems_ModeledAmbTemp 82;
BA_ "GenSigStartValue" SG_ 898 CF_Ems_DecelReq 4094;
BA_ "GenSigStartValue" SG_ 898 CR_Ems_EngOilTemp 53.333333333;
BA_ "GenSigStartValue" SG_ 880 N_TGT_LUP 255;
BA_ "GenSigStartValue" SG_ 880 SLOPE_TCU 32;
BA_ "GenSigStartValue" SG_ 852 CF_Lvr_GearInf 9;
BA_ "GenSigStartValue" SG_ 816 CR_Tcu_TqDec 255;
BA_ "GenSigStartValue" SG_ 816 CR_Tcu_CreepTq 512;
BA_ "GenSigStartValue" SG_ 809 TPS 31.99999787;
BA_ "GenSigStartValue" SG_ 809 MAF_FAC_ALTI_MMV 128;
BA_ "GenSigStartValue" SG_ 809 TEMP_ENG 255;
BA_ "GenSigStartValue" SG_ 809 BRAKE_ACT 1;
BA_ "GenSigStartValue" SG_ 809 CONF_MIL_FMY 3;
BA_ "GenSigStartValue" SG_ 790 RATIO_TQI_BAS_MAX_STND 127;
BA_ "GenSigStartValue" SG_ 790 SWI_IGK 1;
BA_ "GenSigStartValue" SG_ 688 SAS_Stat 7;
BA_ "GenSigStartValue" SG_ 592 CR_Mdps_StrColTq 1024;
BA_ "GenSigStartValue" SG_ 584 CR_Lkas_StrToqReq 1024;
BA_ "GenSigStartValue" SG_ 544 YAW_RATE 4095;
BA_ "GenSigStartValue" SG_ 544 LAT_ACCEL 1023;
BA_ "GenSigStartValue" SG_ 544 LONG_ACCEL 1023;
BA_ "GenSigStartValue" SG_ 496 SA_COUNT 16384;
BA_ "GenSigStartValue" SG_ 357 CR_Mdps_OutTq 2048;
BA_ "GenSigStartValue" SG_ 357 CR_Mdps_StrTq 2048;
BA_ "GenSigStartValue" SG_ 356 CR_Esc_StrTqReq 2048;
BA_ "GenSigStartValue" SG_ 339 TQI_TCS 255;
BA_ "GenSigStartValue" SG_ 339 TQI_SLW_TCS 255;
BA_ "GenSigStartValue" SG_ 305 CF_Yrs_AxStat 4;
BA_ "GenSigStartValue" SG_ 305 CF_Yrs_YawAccStat 4;
BA_ "GenSigStartValue" SG_ 304 CR_Yrs_LatAc 32768;
BA_ "GenSigStartValue" SG_ 304 CR_Yrs_Yr 32768;
BA_ "GenSigStartValue" SG_ 161 PID_09h 128;
BA_ "GenSigStartValue" SG_ 161 PID_08h 128;
BA_ "GenSigStartValue" SG_ 161 PID_07h 128;
BA_ "GenSigStartValue" SG_ 161 PID_06h 128;
BA_ "GenSigStartValue" SG_ 160 PID_05h 40;
BA_ "GenSigStartValue" SG_ 129 BRAKE_ACT 1;
BA_ "GenSigStartValue" SG_ 68 CR_Datc_OutTempF 42;
BA_ "GenSigStartValue" SG_ 68 CF_Datc_IncarTemp 80;
BA_ "GenSigStartValue" SG_ 66 CR_Datc_RearDrTempDispC -32;
BA_ "GenSigStartValue" SG_ 66 CR_Datc_DrTempDispF -60;
BA_ "GenSigStartValue" SG_ 66 CR_Datc_PsTempDispC -32;
BA_ "GenSigStartValue" SG_ 66 CR_Datc_RearDrTempDispF -60;
BA_ "GenSigStartValue" SG_ 66 CR_Datc_PsTempDispF -60;
BA_ "GenSigStartValue" SG_ 64 CR_Datc_SelfDiagCode 1;
BA_ "GenSigStartValue" SG_ 24 CF_Gway_DeliveryMode 1;
BA_ "GenSigSendType" SG_ 21 CF_Gway_PBackP2Cmd 4;
BA_ "GenSigSendType" SG_ 21 CF_Gway_PBackP1Cmd 4;
BA_ "GenSigSendType" SG_ 21 CF_Gway_MemP2Cmd 4;
BA_ "GenSigSendType" SG_ 21 CF_Gway_MemP1Cmd 4;
VAL_ 2015 REQ_RESPONSE 2 "No response required" 1 "Response required" 0 "Reserved" ;
VAL_ 2015 SID 41 "Enable transmission of normal CAN messages. (Resume normal CAN communication)" 40 "Disable transmission of normal CAN messages. (Stop normal CAN communication)" ;
VAL_ 2015 FRM_FORMAT 2 "Single frame and should analyze next two data of this message" ;
VAL_ 1984 CCW 5 "Reset SAS_CAL flag" 3 "Request calibration and acceptance of SAS_CID" ;
VAL_ 1680 IGN_SW 4 "Start" 3 "IGN" 2 "ACC" 1 "Key In" 0 "Key Off" ;
VAL_ 1680 CF_Clu_FlexStrgModeSwi 3 "Reserved" 2 "Comfort" 1 "Sports" 0 "Standard" ;
VAL_ 1680 PIC_Lock 3 "Lock" 2 "Lock &amp; No.2" 1 "Lock &amp; No.1" 0 "None" ;
VAL_ 1680 AST_DR_SW 3 "Invalid" 2 "Reserved" 1 "Open" 0 "Close" ;
VAL_ 1680 DRV_DR_SW 3 "Invalid" 2 "Reserved" 1 "Open" 0 "Close" ;
VAL_ 1680 PIC_Unlock 4 "PIC Key Reminder" 3 "Unlock" 2 "Unlock &amp; No.2" 1 "Unlock &amp; No.1" 0 "None" ;
VAL_ 1680 CF_HoodStat 3 "Invalid" 2 "Reserved" 1 "Hood Open" 0 "Hood Close
1H : Hood Open
2H : Reserved
3H : Invalid" ;
VAL_ 1680 CF_SWL_Stat 7 "Lamp Circuit Failure" 3 "ACU message error" 2 "Lamp Flashing" 1 "Lamp On" 0 "Lamp OFF" ;
VAL_ 1680 DRV_Key_Lock 1 "Driver door key lock" 0 "Off" ;
VAL_ 1680 DRV_Seat_Belt 3 "Invalid" 2 "Failed" 1 "Unbelted" 0 "Belted" ;
VAL_ 1680 PAS_Seat_Belt 3 "Invalid" 2 "Failed" 1 "Unbelted" 0 "Belted" ;
VAL_ 1680 DRV_Key_Unlock 1 "Driver door key unlock" 0 "Off" ;
VAL_ 1680 CF_Clu_HazardSW 1 "Hazard switch is ¡°ON¡±" 0 "Hazard switch is ¡°OFF¡±" ;
VAL_ 1680 CF_Clu_SwiGearR 3 "Invalid" 2 "Reserved" 1 "Gear_R Switch On" 0 "Gear_R Switch Off" ;
VAL_ 1680 CF_Clu_WiperLow 1 "ON" 0 "OFF(the value for invalid signal)" ;
VAL_ 1680 CF_Clu_TurnSigLh 1 "ON" 0 "OFF(the value for invalid signal)" ;
VAL_ 1680 CF_Clu_TurnSigRh 1 "ON" 0 "OFF(the value for invalid signal)" ;
VAL_ 1680 CF_Clu_WiperAuto 1 "ON" 0 "OFF(the value for invalid signal)" ;
VAL_ 1680 CF_Clu_WiperHigh 1 "ON" 0 "OFF(the value for invalid signal)" ;
VAL_ 1680 CF_Clu_WiperIntT 4 "Step 5" 3 "Step 4" 2 "Step 3" 1 "Step 2" 0 "Step 1(the value for invalid signal)" ;
VAL_ 1680 CF_Clu_AltLStatus 1 "On (Open or High)" 0 "Off (Low)" ;
VAL_ 1680 CF_Clu_LdwsLkasSW 1 "ON" 0 "OFF(the value for invalid signal)" ;
VAL_ 1680 CF_Clu_WiperIntSW 1 "ON" 0 "OFF(the value for invalid signal)" ;
VAL_ 1680 TRUNK_OPEN_STATUS 3 "Invalid" 2 "Reserved" 1 "Trunk Open" 0 "Trunk Close" ;
VAL_ 1680 CF_Clu_ActiveEcoSW 1 "Active ECO switch is pressed (ON)" 0 "Active ECO switch is not pressed (OFF)" ;
VAL_ 1680 CF_Clu_EcoDriveInf 7 "Error" 3 "Red Lamp On" 2 "Yellow Lamp On" 1 "Green Lamp On" 0 "Not Activated" ;
VAL_ 1680 CF_Clu_HeadLampLow 1 "Head Lamp Low Beam On" 0 "Head Lamp Low Beam Off" ;
VAL_ 1680 CF_Clu_RainSnsStat 6 "Fault 3" 5 "Fault 2" 4 "Fault 1" 3 "High" 2 "Low" 1 "Rain Detected" 0 "OFF" ;
VAL_ 1680 CF_Clu_HeadLampHigh 1 "Head Lamp High Beam On" 0 "Head Lamp High Beam Off" ;
VAL_ 1680 CF_Clu_LkasDispMode 3 "Reserved" 2 "Lane Guidance" 1 "Reverse Torque" 0 "Not Available" ;
VAL_ 1680 RKE_CMD 7 "Reserved" 6 "Unlock" 5 "Lock" 4 "Unlock &amp; No.2" 3 "Lock &amp; No.2" 2 "Unlock &amp; No.1" 1 "Lock &amp; No.1" 0 "None" ;
VAL_ 1616 CF_Afls_LedHLStat 3 "AFLS is defective" 2 "Reserved" 1 "AFLS Off" 0 "AFLS is in normal condition" ;
VAL_ 1616 AFLS_STAT 3 "AFLS is defective" 2 "Reserved" 1 "AFLS Off" 0 "AFLS is in normal condition" ;
VAL_ 1616 CF_Afls_TrfChgStat 1 "Traffic Change Mode" 0 "Nomal Mode" ;
VAL_ 1552 GPLG3_STAT 15 "N/A (ECU has not calculated the signal value so far)" 14 "Error detected (ECU cannot supply the correct status signal due to internal or external error)" 2 "Short circuit" 1 "Line Open " 0 "Normal condition (No fault)" ;
VAL_ 1552 GPLG4_STAT 15 "N/A (ECU has not calculated the signal value so far)" 14 "Error detected (ECU cannot supply the correct status signal due to internal or external error)" 2 "Short circuit" 1 "Line Open " 0 "Normal condition (No fault)" ;
VAL_ 1552 GPLG5_STAT 15 "N/A (ECU has not calculated the signal value so far)" 14 "Error detected (ECU cannot supply the correct status signal due to internal or external error)" 2 "Short circuit" 1 "Line Open " 0 "Normal condition (No fault)" ;
VAL_ 1552 GPLG6_STAT 15 "N/A (ECU has not calculated the signal value so far)" 14 "Error detected (ECU cannot supply the correct status signal due to internal or external error)" 2 "Short circuit" 1 "Line Open " 0 "Normal condition (No fault)" ;
VAL_ 1552 GPC_OT_STAT 3 "N/A (ECU has not calculated the signal value so far)" 2 "Signal Error. (ECU cannot supply the correct status signal due to internal or external error)" 1 "Fault Active (Glow plugs are switched off)" 0 "No fault" ;
VAL_ 1552 GPC_OV_STAT 3 "N/A (ECU has not calculated the signal value so far)" 2 "Signal Error. (ECU cannot supply the correct status signal due to internal or external error)" 1 "Fault Active (Supply voltage is over limit)" 0 "No fault" ;
VAL_ 1552 GPC_SW_COND 3 "N/A (ECU has not calculated the signal value so far)" 2 "Signal Error. (ECU cannot supply the correct status signal due to internal or external error)" 1 "Fault" 0 "No fault" ;
VAL_ 1552 GPC_SW_OPEN 3 "N/A (ECU has not calculated the signal value so far)" 2 "Signal Error. (ECU cannot supply the correct status signal due to internal or external error)" 1 "At least one power stage does not switch on" 0 "No fault" ;
VAL_ 1552 GPC_TO_STAT 3 "N/A (ECU has not calculated the signal value so far)" 2 "Signal Error. (ECU cannot supply the correct status signal due to internal or external error)" 1 "Fault Active (Relevant message timeout)" 0 "No fault" ;
VAL_ 1552 GPC_UV_STAT 3 "N/A (ECU has not calculated the signal value so far)" 2 "Signal Error. (ECU cannot supply the correct status signal due to internal or external error)" 1 "Fault Active (Supply voltage is under limit)" 0 "No fault" ;
VAL_ 1552 GPLG2_STAT 15 "N/A (ECU has not calculated the signal value so far)" 14 "Error detected (ECU cannot supply the correct status signal due to internal or external error)" 2 "Short circuit" 1 "Line Open " 0 "Normal condition (No fault)" ;
VAL_ 1552 GPLG1_STAT 15 "N/A (ECU has not calculated the signal value so far)" 14 "Error detected (ECU cannot supply the correct status signal due to internal or external error)" 2 "Short circuit" 1 "Line Open " 0 "Normal condition (No fault)" ;
VAL_ 1552 GPCM_CTRL 15 "N/A (ECU has not calculated the signal value so far)" 14 "Signal Error (ECU cannot supply the correct status signal due to internal or external error)" 2 "Default glowing (Communication to EMS is broken). Glowing is controlled internally" 1 "Engine start glow on (normal operation).At least one glow plug is glowing" 0 "Glow off ? No glow plug is glowing" ;
VAL_ 1552 GPCM_ERROR 15 "N/A (ECU has not calculated the signal value so far)" 14 "Signal Error (ECU cannot supply the correct status signal due to internal or external error)" 1 "Error present in glow system. It¡¯s a concatenation of all other error status bits. If any error is present in the system, this signal is set" 0 "No error present in glow system" ;
VAL_ 1530 CR_Wcs_ClassStat 4 "Indeterminate" 2 "Adult (Class2)" 1 "Child (Class1)" 0 "Empty (Class0)" ;
VAL_ 1530 CF_Ods_AcuRcvSN 1 "ACU Serial Number Received" 0 "ACU Serial Number not received" ;
VAL_ 1530 CF_Ods_WgtStat 1 "Occupant above ¡°allow¡± threshold" 0 "Occupant below ¡°allow¡± threshold" ;
VAL_ 1530 CF_Ods_EcuFail 1 "ECU Fault exists" 0 "No ECU Fault exists" ;
VAL_ 1530 CF_Ods_BtsFail 1 "Belt Tension Sensor Fault exists" 0 "No Belt Tension Sensor Fault exists" ;
VAL_ 1530 CF_Ods_PsFail 1 "Pressure Sensor Fault exists" 0 "No Pressue Sensor Fault exists" ;
VAL_ 1530 CF_Ods_PrcCmd 1 "Command in process" 0 "No command in process" ;
VAL_ 1530 CF_Ods_EolCal 1 "Request to re-zero the empty seat offset" 0 "No re-zero request" ;
VAL_ 1530 CF_Ods_OccStat 1 "Seat Occupied" 0 "Seat not occupied" ;
VAL_ 1524 PSB_RH_ACT 1 "PSB retract cycle active" 0 "No PSB motor activation" ;
VAL_ 1524 PSB_RH_FAIL 3 "Signal not valid" 2 "Defect, PSB warning light off" 1 "Failure/Service Required" 0 "No failure" ;
VAL_ 1523 PSB_LH_ACT 1 "PSB retract cycle active" 0 "No PSB motor activation" ;
VAL_ 1523 PSB_LH_FAIL 3 "Signal not valid" 2 "Defect, PSB warning light off" 1 "Failure/Service Required" 0 "No failure" ;
VAL_ 1520 TPMS_W_LAMP 3 "Reserved" 2 "TPMS Malfunction Warning lamp BLINKING(2Hz)" 1 "TPMS Malfunction Warning lamp ON" 0 "TPMS Malfunction Warning lamp OFF" ;
VAL_ 1520 TREAD_W_LAMP 3 "Reserved" 2 "TREAD Warning lamp BLINKING(2Hz)" 1 "TREAD Warning lamp ON" 0 "TREAD Warning lamp OFF" ;
VAL_ 1520 POS_FL_W_LAMP 1 "FL POSITION Warning lamp ON" 0 "FL POSITION Warning lamp OFF" ;
VAL_ 1520 POS_FR_W_LAMP 1 "FR POSITION Warning lamp ON" 0 "FR POSITION Warning lamp OFF" ;
VAL_ 1520 POS_RL_W_LAMP 1 "RL POSITION Warning lamp ON" 0 "RL POSITION Warning lamp OFF" ;
VAL_ 1520 POS_RR_W_LAMP 1 "RR POSITION Warning lamp ON" 0 "RR POSITION Warning lamp OFF" ;
VAL_ 1508 CF_Mdps_Flex 3 "Reserved" 2 "Comport Mode" 1 "Sport Mode" 0 "Standard Mode" ;
VAL_ 1508 CF_Mdps_FlexStat 3 "Reserved" 2 "MDPS Fault" 1 "Input Condition Error(Velocity Only)" 0 "Normal" ;
VAL_ 1508 CF_Mdps_FlexDisp 1 "Display" 0 "No Display" ;
VAL_ 1508 CF_Mdps_WLmp 3 "MDPS Malfunction Warning lamp BLANKING(1Hz) : Diagnostic mode" 2 "MDPS Malfunction Warning lamp ON" 1 "MDPS Malfunciton Warning lamp BLANKING(2Hz) : Power Limit Assist Mode" 0 "MDPS Malfunction Warning lamp OFF" ;
VAL_ 1504 Leveling_Off 1 "Leveling control deactivated by user" 0 "Leveling control active (normal)" ;
VAL_ 1504 Lowering 1 "lowering" 0 "no change of level" ;
VAL_ 1504 REQ_level 7 "High" 6 "Off-road" 5 "Normal" 4 "Highway" 3 "Low" ;
VAL_ 1504 ACT_Height 7 "High" 6 "Off-road" 5 "Normal" 4 "Highway" 3 "Low" ;
VAL_ 1504 ECS_W_LAMP 1 "On" 0 "Off" ;
VAL_ 1504 REQ_Height 3 "3H : Low" 2 "2H : High" 1 "1H : Normal" 0 "No Manual Switch input" ;
VAL_ 1504 LC_overheat 1 "System is overheated (cooling in progress)" 0 "Normal" ;
VAL_ 1504 REQ_Damping 3 "Reserved" 2 "Hard" 1 "Soft" 0 "Auto" ;
VAL_ 1504 Damping_Mode 3 "Reserved" 2 "Hard" 1 "Soft" 0 "Auto" ;
VAL_ 1504 ECS_DIAG 1 "ECS is diagnosis states" 0 "ECS is not diagnosis states" ;
VAL_ 1504 Lifting 1 "raising" 0 "no change of level" ;
VAL_ 1504 ECS_DEF 1 "ECS is defective" 0 "ECS is not defective" ;
VAL_ 1504 SYS_NA 1 "System temporary not available" 0 "System available" ;
VAL_ 1504 L_CHG_NA 1 "Height level change not available" 0 "-" ;
VAL_ 1461 ACC_ObjStatus 3 "SCC Pre-Safe I/F inactive (No VI platform detected)" 2 "Reserved" 1 "SCC Object detected" 0 "No SCC object detected" ;
VAL_ 1442 CF_Acu_ExtOfSab 3 "Not used" 2 "Side(or Side/Curtain) Airbag exists." 1 "Side(or Side/Curtain) Airbag doesn't exist." 0 "ACU EOL Programming Mode" ;
VAL_ 1442 CF_Acu_FltStat 3 "Not used" 2 "Fault does not exist" 1 "Fault status is historic" 0 "Fault status is active" ;
VAL_ 1442 CF_SWL_Ind 3 "Not used" 2 "Warning Lamp flash" 1 "Warning Lamp off" 0 "Warning Lamp on" ;
VAL_ 1440 CF_Ods_FltClrReq 1 "Request to clear ODS Fault codes" 0 "No Fault Clear Requested" ;
VAL_ 1440 CF_DriBkl_FltStat 1 "Fault condition exists" 0 "No Fault" ;
VAL_ 1440 CF_PasBkl_FltStat 1 "Fault condition exists" 0 "No Fault" ;
VAL_ 1440 CF_Abg_DepInhEnt 1 "Crash event with Passenger Front/Side Airbag Inhibited" 0 "Default Value" ;
VAL_ 1440 CF_PasBkl_Stat 1 "Passenger Seat Belt Latched" 0 "Passenger Seat Belt Not Latched" ;
VAL_ 1440 CF_DriBkl_Stat 1 "Driver Seat Belt Latched " 0 "Driver Seat Belt Not Latched" ;
VAL_ 1440 CF_Abg_DepEnt 1 "Crash event with Passenger Front/Side Airbag not Inhibited" 0 "Default Value" ;
VAL_ 1440 CF_Ods_SNRcv 1 "Acknowledgement for the Correct S/N Received" 0 "Request to send ODS Serial Number" ;
VAL_ 1440 CF_Ods_IDRcv 1 "Acknowledgement for the Correct ODS Identifier Received" 0 "Request to send ODS Identifier" ;
VAL_ 1440 CF_Ods_RZReq 1 "Request to re-zero the empty seat offset" 0 "No re-zero request" ;
VAL_ 1437 CF_Ahls_WarnMsg 3 "Invalid" 2 "AHLS fired" 1 "AHLS malfunction" 0 "AHLS normal operation" ;
VAL_ 1437 CF_Ahls_WarnLamp 3 "Invalid" 2 "The warning lamp blink(2Hz)" 1 "Turn on the warning lamp" 0 "Turn off the warning lamp" ;
VAL_ 1435 CF_TCU_WarnMsg 4 "Warning message 4" 3 "Warning message 3" 2 "Warning message 2" 1 "Warning message 1" 0 "No Warning message" ;
VAL_ 1435 CF_TCU_WarnSnd 1 "Warning Sound" 0 "No Warning Sound" ;
VAL_ 1435 CF_Tcu_EolStat 1 "EOL completed" 0 "EOL not completed" ;
VAL_ 1435 CR_Tcu_GearSelDisp2 15 "Fault" 14 "Intermediate Position" 13 "Reserved" 12 "Paddle shift (D-position)" 11 "Sub-Rom Communication error" 10 "Sub-Rom Communication" 9 "Not Display at Cluster" 8 "sports mode / manual shift / paddle shift" 7 "R" 6 "N" 5 "D" 4 "DS mode" 3 "3" 2 "2" 1 "L" 0 "P" ;
VAL_ 1435 CF_TCU_WarnImg 1 "Warning Image" 0 "No Warning Image" ;
VAL_ 1419 CF_Lca_IndRight 3 "Indicator output check" 2 "Indicator blinking(warning)" 1 "Indicator on (information)" 0 "Indicator output off" ;
VAL_ 1419 CF_Lca_IndLeft 3 " Indicator output check" 2 " Indicator blinking(warning)" 1 "Indicator on (information)" 0 "Indicator output off" ;
VAL_ 1419 CF_Lca_Stat 3 "System Failure" 2 "System Active" 1 "System Passive" 0 "System is Off" ;
VAL_ 1417 CF_Ehps_StrMode 3 "Reserved" 2 "Reserved" 1 "Sport mode" 0 "Normal mode" ;
VAL_ 1417 CF_Ehps_Warn 3 "Reserved" 2 "2nd warning message and buzzer request for cluster" 1 "1st warning message request for cluster" 0 "Normal" ;
VAL_ 1415 CF_Tmu_ReqRepCnd 3 "Reserved" 2 "Reprogramming complete" 1 "Reprogramming request" 0 "Normal state" ;
VAL_ 1415 CF_Tmu_AirconCtr 1 "Activate air conditioner automatic control" 0 "Deactivate air conditioner automatic control" ;
VAL_ 1415 CF_Tmu_VehImmo 1 "Vehicle Immobilization On" 0 "Vehicle Immobilization Off" ;
VAL_ 1415 CF_Tmu_TempSet 15 "23.5¡É/75¢µ" 14 "23¡É/74¢µ" 13 "22.5¡É/73¢µ" 12 "22¡É/72¢µ" 11 "21.5¡É/71¢µ" 10 "21¡É/70¢µ" 9 "20.5¡É/69¢µ" 8 "20¡É/68¢µ" 7 "19.5¡É/67¢µ" 6 "19¡É/66¢µ" 5 "18.5¡É/65¢µ" 4 "18¡É/64¢µ" 3 "17.5¡É/63¢µ" 32 "High" 2 "Low" 31 "31.5¡É" 30 "31¡É/High" 29 "30.5¡É/89¢µ" 28 "30¡É/88¢µ" 27 "29.5¡É/87¢µ" 26 "29¡É/86¢µ" 25 "28.5¡É/85¢µ" 24 "28¡É/84¢µ" 23 "27.5¡É/83¢µ" 22 "27¡É/82¢µ" 21 "26.5¡É/81¢µ" 20 "26¡É/80¢µ" 19 "25.5¡É/79¢µ" 18 "25¡É/78¢µ" 17 "24.5¡É/77¢µ" 16 "24¡É/76¢µ" 1 "Display" 0 "Blank" ;
VAL_ 1415 CF_Tmu_VehSld 1 "Vehicle Slow Down On" 0 "Vehicle Slow Down Off" ;
VAL_ 1415 CF_Tmu_TempMd 1 "Fahrenheit Mode" 0 "Centigrade Mode" ;
VAL_ 1414 CF_Evp_Stat 1 "EVP is defective" 0 "EVP is no defective" ;
VAL_ 1412 CF_Aaf_MilOnReq 1 "MIL ON" 0 "MIL OFF" ;
VAL_ 1412 CF_Aaf_WrnLamp 1 "Warning Lamp/Message On" 0 "Warning Lamp/Message Off" ;
VAL_ 1412 CF_Aaf_SolFlapStatus 2 "OPEN" 1 "CLOSE" ;
VAL_ 1412 CF_Aaf_ActFlapStatus 3 "Unknown" 2 "OPEN" 1 "CLOSE" ;
VAL_ 1412 CF_Aaf_ModeStatus 7 "Reserved" 6 "Safe Mode" 5 "Fail Safety Mode" 4 "Coast Down Mode" 3 "HS &amp; HP Mode" 2 "High Performance Mode" 1 "High Speed Mode" 0 "Normal Mode" ;
VAL_ 1411 CF_Cubis_HUDisp 3 "MTS(Served)" 2 "MTS(Unserved)" 1 "AVN" 0 "AUDIO" ;
VAL_ 1408 ABS_DEF 1 "ABS is defective" 0 "ABS is not defective" ;
VAL_ 1408 EBD_DEF 1 "EBD is defective" 0 "EBD is not defective" ;
VAL_ 1408 ABS_DIAG 1 "ABS is diagnostic mode" 0 "ABS is not diagnostic mode" ;
VAL_ 1408 ESS_STAT 3 "ESS extended function 'active' (Hazard lamp blinking)" 2 "ESS system is defective" 1 "ESS control ¡°active¡± (Emergency stop condition)" 0 "ESS control ¡°inactive¡± (Normal condition)" ;
VAL_ 1408 EBD_W_LAMP 1 "EBD Warning lamp ON" 0 "EBD Warning lamp OFF" ;
VAL_ 1408 ABS_W_LAMP 1 "ABS Warning lamp ON" 0 "ABS Warning lamp OFF" ;
VAL_ 1408 ABS_ACT 1 "ABS control active" 0 "ABS control inactive" ;
VAL_ 1378 CF_Hud_Brightness 19 "Step 20" 18 "Step 19" 17 "Step 18" 16 "Step 17" 15 "Step 16" 14 "Step 15" 13 "Step 14" 12 "Step 13" 11 "Step 12" 10 "Step 11" 9 "Step 10" 8 "Step 9" 7 "Step 8" 6 "Step 7" 5 "Step 6" 4 "Step 5" 3 "Step 4" 2 "Step 3" 1 "Step 2" 0 "Step 1" ;
VAL_ 1378 CF_Hud_HeightStaus 19 "Step 20" 18 "Step 19" 17 "Step 18" 16 "Step 17" 15 "Step 16" 14 "Step 15" 13 "Step 14" 12 "Step 13" 11 "Step 12" 10 "Step 11" 9 "Step 10" 8 "Step 9" 7 "Step 8" 6 "Step 7" 5 "Step 6" 4 "Step 5" 3 "Step 4" 2 "Step 3" 1 "Step 2" 0 "Step 1" ;
VAL_ 1365 CF_Fpcm_PreSnrDisc 1 "Pressure Sensor Disconnect Error" 0 "Normal Operation" ;
VAL_ 1365 CF_Fpcm_PreSnrShort 1 "Pressure Sensor Short Error" 0 "Normal Operation" ;
VAL_ 1365 CF_Fpcm_LPCtrOverVol 1 "LP Fuel Pump Controller Over Voltage" 0 "Normal Operation" ;
VAL_ 1365 CF_Fpcm_LPPumpOverCur 1 "LP Pump Over Current" 0 "Normal Operation" ;
VAL_ 1365 CF_Fpcm_LPPumpDiscShort 1 "LP Fuel Pump Disconnect or Short Error" 0 "Normal Operation" ;
VAL_ 1365 CF_Fpcm_LP_System_Error 1 "System Error for Low PressureSystem" 0 "Normal Operation" ;
VAL_ 1362 CF_Snv_IRLampControl 3 "Reserved" 2 "Reserved" 1 "IR-Lamp On" 0 "IR-Lamp Off   " ;
VAL_ 1362 CF_SNV_DisplayControl 3 "Reserved" 2 "Display On " 1 "Display Black" 0 "Display Off " ;
VAL_ 1362 CF_Snv_BeepWarning 3 "Reserved" 2 "Reserved" 1 "Beep Warning" 0 "None" ;
VAL_ 1362 CF_Snv_DetectionEnable 1 "Detection Mode Enable " 0 "Detection Mode Disable  " ;
VAL_ 1362 CF_Snv_PedestrianDetect 3 "Reserved" 2 "Reserved" 1 "Detected" 0 "None   " ;
VAL_ 1362 CF_Snv_WarningMessage 7 "Reserved" 6 " System ON &amp;luminous intensity Low &amp; H/Lamp On &amp; IR LAMP All Fail" 5 "System ON &amp; luminous intensity Low &amp; H/Lamp On &amp; IR LAMP Right Fail" 4 "System ON &amp; luminous intensity Low &amp; H/Lamp On &amp; IR LAMP Left Fail" 3 "System ON &amp; luminous intensity Low &amp; H/Lamp Off " 2 "System ON &amp; luminous intensity High (day) " 1 "System Failure " 0 "No Warning" ;
VAL_ 1352 CF_Rpas_IndCR 4 "Malfunction" 3 "3rd Warning" 2 "2nd Warning" 1 "1st Warning" 0 "OFF" ;
VAL_ 1352 CF_Fpas_IndCL 4 "Malfunction" 3 "3rd Warning" 2 "2nd Warning" 1 "1st Warning" 0 "OFF" ;
VAL_ 1352 CF_Rpas_IndR 4 "Malfunction" 3 "3rd Warning" 2 "2nd Warning" 1 "1st Warning" 0 "OFF" ;
VAL_ 1352 CF_Rpas_IndL 4 "Malfunction" 3 "3rd Warning" 2 "2nd Warning" 1 "1st Warning" 0 "OFF" ;
VAL_ 1352 CF_Fpas_IndR 4 "Malfunction" 3 "3rd Warning" 2 "2nd Warning" 1 "1st Warning" 0 "OFF" ;
VAL_ 1352 CF_Fpas_IndL 4 "Malfunction" 3 "3rd Warning" 2 "2nd Warning" 1 "1st Warning" 0 "OFF" ;
VAL_ 1352 CF_Pas_SW 1 "ON" 0 "OFF" ;
VAL_ 1352 CF_Rpas_IndCL 4 "Malfunction" 3 "3rd Warning" 2 "2nd Warning" 1 "1st Warning" 0 "OFF" ;
VAL_ 1352 CF_Fpas_IndCR 4 "Malfunction" 3 "3rd Warning" 2 "2nd Warning" 1 "1st Warning" 0 "OFF" ;
VAL_ 1350 CF_DiBox_SedInjVErrSPI 1 "ERROR" 0 "NO ERROR" ;
VAL_ 1350 CF_DiBox_FrtInjVErrSPI 1 "ERROR" 0 "NO ERROR" ;
VAL_ 1350 CF_DiBox_SedInjVChg 1 "ERROR" 0 "NO ERROR" ;
VAL_ 1350 CF_DiBox_FrtInjVChg 1 "ERROR" 0 "NO ERROR" ;
VAL_ 1349 L_MIL 1 "Check Engine lamp ON" 0 "Check Engine lamp OFF" ;
VAL_ 1349 IM_STAT 1 "Immobilizer passive" 0 "Immobilizer active" ;
VAL_ 1349 IM_AUTEHN 1 "Lock" 0 "Unlock" ;
VAL_ 1296 CF_Gway_PasSys 3 "reserved" 2 "reserved" 1 "ON" 0 "OFF" ;
VAL_ 1296 CF_Gway_PasAlarm_Spkr_Rcnt 3 "3¡¯rd warning alarm level (the closest status with obstacle)" 2 "2¡¯nd warning alarm level" 1 "1¡¯st warning alarm level" 0 "OFF(No warning alarm)" ;
VAL_ 1296 CF_Gway_PasIndFC 7 "Malfunction (sensor fail)" 6 "Noise bit ON" 5 "Reserved" 4 "Reserved" 3 "3rd warning" 2 "2nd warning" 1 "1st warning" 0 "OFF (No warning alarm)" ;
VAL_ 1296 CF_Gway_PasIndRC 7 "Malfunction (sensor fail)" 6 "Noise bit ON" 5 "Reserved" 4 "Reserved" 3 "3rd warning" 2 "2nd warning" 1 "1st warning" 0 "OFF (No warning alarm)" ;
VAL_ 1296 CF_Gway_PasIndFIL 7 "Malfunction (sensor fail)" 6 "Noise bit ON" 3 "3rd warning" 2 "2nd warning" 1 "1st warning" 0 "OFF (No warning alarm)" ;
VAL_ 1296 CF_Gway_PasIndFIR 7 "Malfunction (sensor fail)" 6 "Noise bit ON" 3 "3rd warning" 2 "2nd warning" 1 "1st warning" 0 "OFF (No warning alarm)" ;
VAL_ 1296 CF_Gway_PasIndFOL 7 "Malfunction (sensor fail)" 6 "Noise bit ON" 3 "3rd warning" 2 "2nd warning" 1 "1st warning" 0 "OFF (No warning alarm)" ;
VAL_ 1296 CF_Gway_PasIndFOR 7 "Malfunction (sensor fail)" 6 "Noise bit ON" 3 "3rd warning" 2 "2nd warning" 1 "1st warning" 0 "OFF (No warning alarm)" ;
VAL_ 1296 CF_Gway_PasIndRIL 7 "Malfunction (sensor fail)" 6 "Noise bit ON" 3 "3rd warning" 2 "2nd warning" 1 "1st warning" 0 "OFF (No warning alarm)" ;
VAL_ 1296 CF_Gway_PasIndRIR 7 "Malfunction (sensor fail)" 6 "Noise bit ON" 3 "3rd warning" 2 "2nd warning" 1 "1st warning" 0 "OFF (No warning alarm)" ;
VAL_ 1296 CF_Gway_PasIndROL 7 "Malfunction (sensor fail)" 6 "Noise bit ON" 3 "3rd warning" 2 "2nd warning" 1 "1st warning" 0 "OFF (No warning alarm)" ;
VAL_ 1296 CF_Gway_PasIndROR 7 "Malfunction (sensor fail)" 6 "Noise bit ON" 3 "3rd warning" 2 "2nd warning" 1 "1st warning" 0 "OFF (No warning alarm)" ;
VAL_ 1296 CF_Gway_PasAlarmFR 3 "3rd warning" 2 "2nd warning" 1 "1st warning" 0 "OFF (No warning alarm)" ;
VAL_ 1296 CF_Gway_PasAlarmRR 3 "3rd warning" 2 "2nd warning" 1 "1st warning" 0 "OFF (No warning alarm)" ;
VAL_ 1296 CF_Gway_PasBeepAlarm 3 "Change to TGS ¡®R¡¯ warning alarm" 2 "Reserved" 1 "PAS Failure State warning alarm" 0 "OFF (No warning alarm)" ;
VAL_ 1296 CF_Gway_PasAlarm_Spkr_Flh 3 "3¡¯rd warning alarm level (the closest status with obstacle)" 2 "2¡¯nd warning alarm level" 1 "1¡¯st warning alarm level" 0 "OFF(No warning alarm)" ;
VAL_ 1296 CF_Gway_PasAlarm_Spkr_Frh 3 "3¡¯rd warning alarm level (the closest status with obstacle)" 2 "2¡¯nd warning alarm level" 1 "1¡¯st warning alarm level" 0 "OFF(No warning alarm)" ;
VAL_ 1296 CF_Gway_PasAlarm_Spkr_Rlh 3 "3¡¯rd warning alarm level (the closest status with obstacle)" 2 "2¡¯nd warning alarm level
" 1 "1¡¯st warning alarm level" 0 "OFF(No warning alarm)" ;
VAL_ 1296 CF_Gway_PasAlarm_Spkr_Rrh 3 "3¡¯rd warning alarm level (the closest status with obstacle)" 2 "2¡¯nd warning alarm level" 1 "1¡¯st warning alarm level" 0 "OFF(No warning alarm)" ;
VAL_ 1296 CF_Gway_PasAlarm_Spkr_Fcnt 3 "3¡¯rd warning alarm level (the closest status with obstacle)" 2 "2¡¯nd warning alarm level" 1 "1¡¯st warning alarm level" 0 "OFF(No warning alarm)" ;
VAL_ 1296 CF_Gway_PasDisp 3 "Invalid" 2 "RPAS Display" 1 "PAS Display" 0 "OFF (No Display)" ;
VAL_ 1288 CF_Lkas_ActiveMode 2 "Lane Guide" 1 "Reverse Torque" 0 "Unavailable" ;
VAL_ 1288 CF_Lkas_RHWarning 2 "LDWS Warning Type 2" 1 "LDWS Warning Type 1" 0 "No Warning" ;
VAL_ 1288 CF_Lkas_LHWarning 2 "LDWS Warning Type 2" 1 "LDWS Warning Type 1" 0 "No Warning" ;
VAL_ 1288 CF_Lkas_SysState 15 "System Failure" 14 "System Not Calibrated " 6 "Mode 2 Right Line" 5 "Mode 2 Left Line" 4 "Mode 2 Full Lane" 3 "Mode 1 ? MDPS Control" 2 "System Unavailable" 1 "Low Vehicle Speed" 0 "System OFF" ;
VAL_ 1288 CF_Lkas_SysWarning 7 "LKAS Internal Failure" 6 "Vehicle Dynamics Sensor Failure (yaw, wheel speed, lat acc, long acc)" 5 "MDPS Failure " 4 "Hands-Off Warning" 3 "Out-of-Control State" 2 "Wiper High Unavailable" 1 "Missing Lane Marking" 0 "No Info" ;
VAL_ 1286 CF_Spas_RRS_Alarm 3 "3¡¯nd warning alarm level (the closest status with obstacle)" 2 "2¡¯nd warning alarm level" 1 "1¡¯st warning alarm level " 0 "OFF(No warning alarm)" ;
VAL_ 1286 CF_Spas_StatAlarm 1 "SPAS&amp;PAS Function Alarm ON " 0 "SPAS&amp;PAS Function Alarm OFF" ;
VAL_ 1286 CF_Spas_RLS_Alarm 3 "3¡¯nd warning alarm level (the closest status with obstacle)" 2 "2¡¯nd warning alarm level" 1 "1¡¯st warning alarm level " 0 "OFF(No warning alarm)" ;
VAL_ 1286 CF_Spas_RCS_Alarm 3 "3¡¯nd warning alarm level (the closest status with obstacle)" 2 "2¡¯nd warning alarm level" 1 "1¡¯st warning alarm level " 0 "OFF(No warning alarm)" ;
VAL_ 1286 CF_Spas_FRS_Alarm 3 "3¡¯nd warning alarm level (the closest status with obstacle)" 2 "2¡¯nd warning alarm level" 1 "1¡¯st warning alarm level " 0 "OFF(No warning alarm)" ;
VAL_ 1286 CF_Spas_FLS_Alarm 3 "3¡¯nd warning alarm level (the closest status with obstacle)" 2 "2¡¯nd warning alarm level" 1 "1¡¯st warning alarm level " 0 "OFF(No warning alarm)" ;
VAL_ 1286 CF_Spas_FCS_Alarm 3 "3¡¯nd warning alarm level (the closest status with obstacle)" 2 "2¡¯nd warning alarm level" 1 "1¡¯st warning alarm level " 0 "OFF(No warning alarm)" ;
VAL_ 1286 CF_Spas_VolDown 3 "Not supported" 2 "Reserved" 1 "ON (activation of warning alarm) " 0 "OFF (deactivation of warning alarm)" ;
VAL_ 1286 CF_Spas_BeepAlarm 13 "Brake intervention activation warning alarm" 12 "SPAS parking out complete warning alarm" 11 "¡°Gear Shift to Forward¡± warning alarm" 10 "¡°Gear Shift to Backward¡± warning alarm" 9 "¡°System abort¡± message during SPAS driving warning alarm" 8 "¡°Scan complete¡± message warning" 7 "¡°Stop¡± message during SPAS function warning alarm" 4 "SPAS parking complete warning alarm" 3 "Change to TGS ¡°R¡± warning alarm" 1 "SPAS/PAS Failure State warning alarm" 0 "No warning alarm" ;
VAL_ 1285 CF_Spas_Disp 3 "SPAS displaly" 2 "SPAS display" 1 "PAS display" 0 "No display" ;
VAL_ 1285 CF_Spas_BEEP_Alarm 13 "Brake intervention activation warning alarm" 12 "SPAS parking out complete warning alarm" 11 "¡°Gear Shift to Forward¡± warning alarm" 10 "¡°Gear Shift to Backward¡± warning alarm" 9 "¡°System abort¡± message during SPAS driving warning alarm" 8 "¡°Scan complete¡± message warning" 7 "¡°Stop¡± message during SPAS function warning alarm" 4 "SPAS parking complete warning alarm" 3 "Change to TGS ¡°R¡± warning alarm" 1 "SPAS/PAS Failure State warning alarm" 0 "No warning alarm" ;
VAL_ 1285 CF_Spas_RI_Ind 7 "Malfunction (sensor fail)" 3 "3¡¯nd warning level (the closest status with obstacle)" 2 "2¡¯nd warning level" 1 "1¡¯st warning level" 0 "OFF (No warning)" ;
VAL_ 1285 CF_Spas_FIL_Ind 7 "Malfunction (sensor fail)" 3 "3¡¯nd warning level (the closest status with obstacle)" 2 "2¡¯nd warning level" 1 "1¡¯st warning level" 0 "OFF (No warning)" ;
VAL_ 1285 CF_Spas_FIR_Ind 7 "Malfunction (sensor fail)" 3 "3¡¯nd warning level (the closest status with obstacle)" 2 "2¡¯nd warning level" 1 "1¡¯st warning level" 0 "OFF (No warning)" ;
VAL_ 1285 CF_Spas_FOL_Ind 7 "Malfunction (sensor fail)" 3 "3¡¯nd warning level (the closest status with obstacle)" 2 "2¡¯nd warning level" 1 "1¡¯st warning level" 0 "OFF (No warning)" ;
VAL_ 1285 CF_Spas_FOR_Ind 7 "Malfunction (sensor fail)" 3 "3¡¯nd warning level (the closest status with obstacle)" 2 "2¡¯nd warning level" 1 "1¡¯st warning level" 0 "OFF (No warning)" ;
VAL_ 1285 CF_Spas_RIL_Ind 7 "Malfunction (sensor fail)" 3 "3¡¯nd warning level (the closest status with obstacle)" 2 "2¡¯nd warning level" 1 "1¡¯st warning level" 0 "OFF (No warning)" ;
VAL_ 1285 CF_Spas_RIR_Ind 7 "Malfunction (sensor fail)" 3 "3¡¯nd warning level (the closest status with obstacle)" 2 "2¡¯nd warning level" 1 "1¡¯st warning level" 0 "OFF (No warning)" ;
VAL_ 1285 CF_Spas_ROL_Ind 7 "Malfunction (sensor fail)" 3 "3¡¯nd warning level (the closest status with obstacle)" 2 "2¡¯nd warning level" 1 "1¡¯st warning level" 0 "OFF (No warning)" ;
VAL_ 1285 CF_Spas_ROR_Ind 7 "Malfunction (sensor fail)" 3 "3¡¯nd warning level (the closest status with obstacle)" 2 "2¡¯nd warning level" 1 "1¡¯st warning level" 0 "OFF (No warning)" ;
VAL_ 1285 CF_Spas_FR_Alarm 3 "3¡¯nd warning alarm level (the closest status with obstacle)" 2 "2¡¯nd warning alarm level" 1 "¡¯st warning alarm level " 0 "OFF(No warning alarm)" ;
VAL_ 1285 CF_Spas_HMI_Stat 51 "Brake intervention activation" 49 "Finishing automatic steering activation for parking out" 47 "Requesting gear shift to backward in parking out mode" 46 "Requesting gear shift to forward in parking out mode" 44 "Automatic steering activation for parking out" 42 "Requesting gear shift to backward in parking out mode after detecting parking out space" 41 "Detecting parking out space - right" 40 "Detecting parking out space - left" 39 "Parking out mode selection - right" 38 "Parking out mode selection - left" 34 "System deactivation by TRAILER MODE" 33 "Requesting EPB AUTO-HOLD OFF" 32 "Over speed of vehicle " 31 "System failed" 30 "System auto-canceled" 28 "Finishing automatic steering activation" 26 "Requesting gear shift to backward during automatic steering activation" 25 "Requesting gear shift to forward during automatic steering activation" 23 "Automatic steering activation" 20 "Finishing parking space - left parallel" 19 "Finishing parking space - right parallel" 18 "Finishing parking space - left perpendicular" 17 "Finishing parking space - right perpendicular" 15 "Requesting Steering Wheel to right side in left perpendicular parking" 14 "Requesting Steering Wheel to left side in right perpendicular parking" 13 "Requesting stop of vehicle in perpendicular parking" 10 "Detecting parking space - left parallel" 9 "Detecting parking space - right parallel" 8 "Detecting parking space - left perpendicular" 7 "Detecting parking space - right perpendicular" 4 "Parking mode selection - left parallel" 3 "Parking mode selection - right parallel" 2 "Parking mode selection - left perpendicular" 1 "Parking mode selection - right perpendicular" 0 "No Display" ;
VAL_ 1285 CF_Spas_RR_Alarm 3 "3¡¯nd warning alarm level (the closest status with obstacle)" 2 "2¡¯nd warning alarm level" 1 "1¡¯st warning alarm level " 0 "OFF(No warning alarm)" ;
VAL_ 1285 CF_Spas_FI_Ind 7 "Malfunction (sensor fail)" 3 "3¡¯nd warning level (the closest status with obstacle)" 2 "2¡¯nd warning level" 1 "1¡¯st warning level" 0 "OFF (No warning)" ;
VAL_ 1266 CF_Clu_RheostatLvl 21 "Step 21 (Detent)" 20 "Step 20 (Reset Value)" 19 "Step 19" 18 "Step 18" 17 "Step 17" 16 "Step 16" 15 "Step 15" 14 "Step 14" 13 "Step 13" 12 "Step 12" 11 "Step 11" 10 "Step 10" 9 "Step 9" 8 "Step 8" 7 "Step 7" 6 "Step 6" 5 "Step 5" 4 "Step 4" 3 "Step 3" 2 "Step 2" 1 "Step 1" 0 "Reserved" ;
VAL_ 1266 SPEED_UNIT 1 "MPH" 0 "Km/h" ;
VAL_ 1266 CF_SWL_Stat 7 "Lamp Circuit Failure" 3 "ACU message error" 2 "Lamp Flashing" 1 "Lamp On" 0 "Lamp OFF" ;
VAL_ 1266 DashACCFail 1 "Failure" 0 "No failure" ;
VAL_ 1266 CF_Clu_SwiGearR 3 "Invalid" 2 "Reserved" 1 "Gear_R Switch On" 0 "Gear_R Switch Off" ;
VAL_ 1266 CF_Clu_DetentOut 1 "Detent On" 0 "Detent Off" ;
VAL_ 1266 CF_Clu_AltLStatus 1 "On (Open or High)" 0 "Off (Low)" ;
VAL_ 1266 CF_Clu_LdwsLkasSW 1 "ON" 0 "OFF(the value for invalid signal)" ;
VAL_ 1266 CF_Clu_ActiveEcoSW 1 "Active ECO switch is pressed (ON)" 0 "Active ECO switch is not pressed (OFF)" ;
VAL_ 1266 CF_Clu_EcoDriveInf 7 "Error" 3 "Red Lamp On" 2 "Yellow Lamp On" 1 "Green Lamp On" 0 "Not Activated" ;
VAL_ 1266 DISFail 1 "Failure" 0 "No failure" ;
VAL_ 1265 CF_Clu_HudTbtSet 1 "on" 0 "off" ;
VAL_ 1265 CF_Clu_RefDetMod 1 "Refuel detected" 0 "Non refuel detected" ;
VAL_ 1265 CF_Clu_ALightStat 1 "ON" 0 "OFF" ;
VAL_ 1265 CF_Clu_AcnCltEnRq 1 "A/C clutch enable request" 0 "A/C clutch disable request" ;
VAL_ 1265 CF_Clu_FxSteerCur 3 "Reserved" 2 "Comfort" 1 "Sport" 0 "Standard" ;
VAL_ 1265 CF_Clu_FxSteerVty 1 "The value of CF_Clu_FxSteerCur is valid" 0 "The value of CF_Clu_FxSteerCur is Invalid" ;
VAL_ 1265 CF_Clu_HudLdwsSet 1 "on" 0 "off" ;
VAL_ 1265 CF_Clu_InstantFCU 3 "MPG(UK)" 2 "MPG(US)" 1 "L/100km" 0 "km/L" ;
VAL_ 1265 CF_Clu_DefoggerRly 1 "ON(CRASH)" 0 "OFF" ;
VAL_ 1265 CF_Clu_FlexSteerSW 1 "Flex steer switch is pressed (ON)" 0 "Flex steer switch is NOT pressed (OFF)" ;
VAL_ 1265 CF_Clu_HudFontSize 3 "Reserved" 2 "Small" 1 "Middle" 0 "Large" ;
VAL_ 1265 CF_Clu_HudSpeedset 1 "on" 0 "off" ;
VAL_ 1265 CF_Clu_LowfuelWarn 3 "Invalid" 2 "Not used" 1 "Low fuel Warning is on" 0 "Low fuel Warning is off" ;
VAL_ 1265 CF_Clu_TrailerMode 1 "Trailer Mode" 0 "Normal Mode" ;
VAL_ 1265 CF_Clu_HeadLampTail 1 "ON" 0 "OFF" ;
VAL_ 1265 CF_Clu_HudBrightSet 3 "Reserved" 2 "Down" 1 "Up" 0 "Default" ;
VAL_ 1265 CF_Clu_HudFontColor 3 "sky blue" 2 "green" 1 "yellow" 0 "white" ;
VAL_ 1265 CF_Clu_HudHeightSet 3 "Reserved" 2 "Down" 1 "Up" 0 "Default" ;
VAL_ 1265 CF_Clu_SportsModeSwi 3 "Invalid" 2 "Snow" 1 "Sports" 0 "Normal" ;
VAL_ 1265 CF_Clu_Detent 1 "ON(Daytime Max)" 0 "OFF(Night Max)" ;
VAL_ 1265 CF_Clu_FrtFog 1 "ON" 0 "OFF" ;
VAL_ 1265 CF_Clu_AvsmCur 1 "AVSM SYSTEM OFF" 0 "AVSM SYSTEM ON" ;
VAL_ 1265 CF_Clu_CluInfo 1 "SVC" 0 "Conventional" ;
VAL_ 1265 CF_Clu_AcnRqSwi 1 "A/C on request" 0 "A/C off request" ;
VAL_ 1265 CF_Clu_TripUnit 3 "Invailid" 2 "mile" 1 "km" 0 "Not Used" ;
VAL_ 1265 CF_Clu_HudDisSet 1 "on" 0 "off" ;
VAL_ 1265 CF_Clu_HudSccSet 1 "on" 0 "off" ;
VAL_ 1264 DISFail 1 "Failure" 0 "No failure" ;
VAL_ 1264 CF_Clu_SldMainSW 1 "SLD main switch pressed (Enable/Disable SLD)" 0 "SLD main switch not pressed (Idle position)" ;
VAL_ 1264 CF_ButSys_VarInd 1 "PushStartOption" 0 "Non PushStartOption" ;
VAL_ 1264 CruiseSWStatus 7 "Failure in Control Switches" 4 "ACC/SCC cancel" 3 "Time gap (Distance, SCC only)" 2 "Set / Minus" 1 "Resume / Plus" 0 " Idle Position" ;
VAL_ 1264 CF_StrRly_Stat 1 "Starter relay output ON" 0 "Starter relay output OFF" ;
VAL_ 1264 CF_Blr_MaxStat 1 "Max blower speed is selected" 0 "Max blower speed is not selected" ;
VAL_ 1264 CruiseSW_Main 1 "ACC/SCC main switch pressed (Enable/Dsable SCC)" 0 "ACC/SCC main switch not pressed (Idle position)" ;
VAL_ 1264 VEHICLE_INFO 1 "VI" 0 "BH" ;
VAL_ 1264 P_Brake_ACT 1 "Parking brake is activated" 0 "Parking brake is not activated" ;
VAL_ 1264 DashACCFail 1 "Failure" 0 "No failure" ;
VAL_ 1264 SPEED_UNIT 1 "MPH" 0 "km/h" ;
VAL_ 1232 _4WD_OPEN 3 "Error" 2 "Torque limit" 1 "Clutch off" 0 "Passive" ;
VAL_ 1232 _4WD_LIM_MODE 1 "Minimum limitation mode" 0 "Maximum limitation mode" ;
VAL_ 1232 _4WD_LIM_REQ 1 "Request duty limit from ESC" 0 "No request from ESC" ;
VAL_ 1201 WHL_DIR_FL 3 "Error identifier" 2 "Backward direction" 1 "Forward direction" 0 "Unknown (Wheel moving stop state or Not applied wheel sensor for direction)" ;
VAL_ 1201 WHL_DIR_FR 3 "Error identifier" 2 "Backward direction" 1 "Forward direction" 0 "Unknown (Wheel moving stop state or Not applied wheel sensor for direction)" ;
VAL_ 1201 WHL_DIR_RL 3 "Error identifier" 2 "Backward direction" 1 "Forward direction" 0 "Unknown (Wheel moving stop state or Not applied wheel sensor for direction)" ;
VAL_ 1201 WHL_DIR_RR 3 "Error identifier" 2 "Backward direction" 1 "Forward direction" 0 "Unknown (Wheel moving stop state or Not applied wheel sensor for direction)" ;
VAL_ 1151 AVH_CLU 1 "On AVH Activation, Vehicle is not secured and driver is still inside" 0 "AVH is off" ;
VAL_ 1151 ECD_ACT 1 "ECD is active(operating)" 0 "ECD is not active" ;
VAL_ 1151 AVH_LAMP 6 "Lamp Status : White Blinking" 5 "Lamp Status : Green Blinking" 4 "Lamp Status : Yallow Blinking" 3 "AVH READY (Lamp Status : White On)" 2 "AVH ACTIVE (Lamp Status : Green On)" 1 "AVH failure (Lamp Status : Yallow On)" 0 "AVH Off (Lamp Status : Off)" ;
VAL_ 1151 AVH_STAT 3 "Reserved" 2 "Being released" 1 "Vehicle is held by the service brake" 0 "No apply" ;
VAL_ 1151 REQ_EPB_STAT 1 "REQ_EPB_ACT signal is invalid" 0 "REQ_EPB_ACT signal is valid" ;
VAL_ 1151 AVH_ALARM 1 "On AVH Activation, Vehicle is not secured and driver is still inside =&gt; comfortable tone" 0 "No alarm" ;
VAL_ 1151 AVH_I_LAMP 3 "Reserved" 2 "Reserved" 1 "Lamp Off" 0 "Lamp On" ;
VAL_ 1151 REQ_EPB_ACT 3 "Close request in secure mode" 2 "Close request in comfort mode" 1 "Release request" 0 "No request" ;
VAL_ 1151 LDM_STAT 1 "ESC can¡¯t perform DBF/AVH (requested by switch)" 0 "ESC ready to DBF/AVH (requested by switch)" ;
VAL_ 1088 ETL_TCU 255 "No reduction" 0 "Max. reduction" ;
VAL_ 1088 N_INC_TCU 1 "Engine speed increase is requested" 0 "No request" ;
VAL_ 1088 IDLE_UP_TCU 1 "IDLE UP request" 0 "No IDLE UP request" ;
VAL_ 1088 FAN_CTRL_TCU 3 "High-Speed Control" 2 "Mid-Speed Control" 1 "Low-Speed Control" 0 "Fan control is not needed" ;
VAL_ 1088 FUEL_CUT_TCU 1 "Fuel cut request from TCU" 0 "No request" ;
VAL_ 1088 INH_FUEL_CUT 1 "Fuel cut inhibition request from TCU" 0 "No request" ;
VAL_ 1088 BRAKE_ACT_TCU 3 "Brake switch failure." 2 "Brake switch is pressed (ON)" 1 "Brake switch is not pressed (OFF)" 0 "TMS does not support this function." ;
VAL_ 1088 CUR_GR 14 "Reverse speed" 8 "8th speed" 7 "7th speed" 6 "6th speed" 5 "5th speed" 4 "4th speed" 3 "3rd speed" 2 "2nd speed" 1 "1st speed" 0 "if N or P are detected (no frictional connection)" ;
VAL_ 1087 F_OBD 1 "OBD error present" 0 "no error present" ;
VAL_ 1087 F_TCU 3 "not used" 2 "diagnostic failure in TCU, limp home activated" 1 "diagnostic failure in TCU" 0 "no failure" ;
VAL_ 1087 SWI_CC 3 "Off slip lock up" 2 "Fully lock up" 1 "Slip lock up" 0 "No lock up control" ;
VAL_ 1087 SWI_GS 1 "gear change is active" 0 "no gear change" ;
VAL_ 1087 TAR_GC 7 "Reverse speed" 6 "More than 6th speed (if provided)" 5 "5th speed (if provided)" 4 "4th speed" 3 "3rd speed" 2 "2nd speed" 1 "1st speed" 0 "if N or P are detected (no frictional connection)" ;
VAL_ 1087 TQI_TCU_INC 255 "Max. Increase" 0 "No request" ;
VAL_ 1087 TQI_TCU 255 "No reduction" 0 "Max. reduction" ;
VAL_ 1087 TCU_STAT 1 "actuator test in process" 0 "normal" ;
VAL_ 1087 TCU_TYPE 3 "DCT" 2 "CVT" 1 "Step A/T" 0 "Reserved" ;
VAL_ 1087 GEAR_TYPE 6 "6 ? Speed A/T or DCT" 5 "5 ? Speed A/T or DCT" 4 "4 ? Speed A/T or DCT" 3 "3 ? Speed A/T or DCT" ;
VAL_ 1087 G_SEL_DISP 15 "fault" 14 "Intermediate Position" 13 "Reserved" 12 "Paddle shift (D-position)" 11 "Sub-Rom Communication Error" 10 "Sub-Rom Communication" 9 "Not Display at Cluster" 8 "sports mode / manual shift / paddle shift" 7 "R" 6 "N" 5 "D" 4 "DS Mode" 3 "3" 2 "2" 1 "L" 0 "P" ;
VAL_ 1075 EPB_CLU 3 "EPB applies by ESC request" 2 "Driver tries to DAR but safety condition is not satisfied" 1 "EPB is in maintenance mode" 0 "Off" ;
VAL_ 1075 EPB_RBL 1 "Request to turn on rear brake lights" 0 "No request" ;
VAL_ 1075 ESP_ACK 1 "Acknowledge for external ESC request" 0 "Idle / No acknowledge" ;
VAL_ 1075 EPB_FAIL 5 "EPB Permanently Not Available" 4 "EPB Temporarily Not Available" 3 "EPB Diagnostic" 2 "EPB Initialization State" 1 "EPB No failure" 0 "Not valid" ;
VAL_ 1075 EPB_ALARM 3 "Reserved" 2 "Uncomfortable tone" 1 "Comfortable tone (Sound once)" 0 "Off" ;
VAL_ 1075 EPB_FORCE 0 "EPB Fully released" ;
VAL_ 1075 EPB_F_LAMP 3 "Reserved" 2 "EOL configuration not done or Emergency released" 1 "Failure detected or in diagnosis mode" 0 "No failure" ;
VAL_ 1075 EPB_I_LAMP 2 "Dynamic Braking (EPB) or Driver Action Requested" 1 "Apply State (EPB)" 0 "Release State (EPB/ AVH)" ;
VAL_ 1075 EPB_STATUS 5 "Dynamic braking via EPB" 4 "Releasing in progress" 3 "Clamping in progress" 2 "Clamped" 1 "Released" 0 "See details in EPB_FRC_ERR" ;
VAL_ 1075 EPB_SWITCH 3 "Switch failure" 2 "Release position (push)" 1 "Apply position (pull)" 0 "Neutral position" ;
VAL_ 1075 EPB_DBF_REQ 1 "Dynamic braking request" 0 "No Request" ;
VAL_ 1075 EPB_FRC_ERR 3 "Force not measurable (e.g. sensor failure)" 2 "Emergency release" 1 "Clamp position not reached" 0 "No failure" ;
VAL_ 1075 EPB_DBF_STAT 1 "EPB_DBF_REQ signal is invalid" 0 "EPB_DBF_REQ signal is valid" ;
VAL_ 1072 MaxGear 7 "7th Gear" 6 "6th Gear" 5 "5th Gear" 4 "4th Gear" 3 "3th Gear" 2 "2nd Gear" 1 "1st Gear" 0 "No request" ;
VAL_ 1072 DriverBraking 1 "Brake pedal pressed" 0 "Brake pedal not pressed" ;
VAL_ 1072 StandStill 1 "stand still detected" 0 "No stand still detected" ;
VAL_ 1072 PBRAKE_ACT 1 "Parking brake is activated" 0 "Parking brake is not activated" ;
VAL_ 1072 BrakeLight 1 "Activate brake lights" 0 "No request" ;
VAL_ 1072 ACC_EQUIP 1 "SCC is equipped" 0 "SCC is not equipped" ;
VAL_ 1072 ACCReqLim 3 "Deceleration Limited" 2 "Acceleration Limited" 1 "Limited No Limitation" 0 "No request" ;
VAL_ 1072 ACCEnable 3 "SCC disabled irreversible due to communication error" 2 "SCC disabled irreversible" 1 "SCC disabled reversible" 0 "SCC enabled" ;
VAL_ 1072 DCEnable 1 "Enable deceleration control" 0 "Disable deceleration control" ;
VAL_ 1072 MinGear 7 "7th Gear" 6 "6th Gear" 5 "5th Gear" 4 "4th Gear" 3 "3th Gear" 2 "2nd Gear" 1 "1st Gear" 0 "No request" ;
VAL_ 1072 ACC_REQ 1 "Enable SCC torque request" 0 "No request" ;
VAL_ 1072 DriverOverride 3 "Not defined" 2 "Override by deceleration" 1 "Override by acceleration pedal" 0 "No override" ;
VAL_ 1064 LOW_ACT 1 "LOW mode is activated" 0 "LOW mode is inactive" ;
VAL_ 1064 _4H_ACT 1 "4H mode is activated" 0 "4H mode is inactive" ;
VAL_ 1064 _2H_ACT 1 "2H mode is activated" 0 "2H mode is inactive" ;
VAL_ 1064 LOCK_ACT 1 "LOCK mode is activated" 0 "LOCK mode is inactive" ;
VAL_ 1064 AUTO_ACT 1 "AUTO mode is activated" 0 "AUTO mode is inactive" ;
VAL_ 1064 _4WD_TYPE 3 "Electric shift 4WD (FR)" 2 "Electronic 4WD (FR)" 1 "Electronic 4WD (FF)" 0 "Reserved" ;
VAL_ 1056 SCCInfoDisplay 4 "Display ¡°Available to resume acceleration control¡±" 3 "Display ¡°Object disappeared at low speed¡±" 2 "Display ¡°Conventional Cruise Mode¡±" 1 "Display ¡°SCC Mode¡±" 0 "-" ;
VAL_ 1056 MainMode_ACC 1 "ON" 0 "OFF" ;
VAL_ 1056 TakeOverReq 1 "Takeover request" 0 "No takeover request" ;
VAL_ 1056 ACCFailInfo 3 "SCC Service Required" 2 "System temporairy unavailable" 1 "Performance degredation" 0 "System without error" ;
VAL_ 1056 ACCMode 3 "Shutoff" 2 "Override" 1 "Engaged" 0 "Off" ;
VAL_ 1056 PreFill 1 "Pre-filling of the brake system is required" 0 "No pre-filling of the brake system is required" ;
VAL_ 1056 StopReq 1 "Stop control is required" 0 "No request" ;
VAL_ 1056 DriverAlertDisplay 3 "Reserved" 2 "Display ¡°No SCC Engage Condition!¡°" 1 "Display ¡°SCC Disengaged¡°" 0 "-" ;
VAL_ 1056 TauGapSet 4 "4th level distance" 3 "3rd level distance" 2 "2nd level distance" 1 "1st level distance" 0 "No time gap set" ;
VAL_ 1056 ObjValid 1 "In-path object detected" 0 "No in-path object detected" ;
VAL_ 1017 Height_FL 254 "Not initialized" ;
VAL_ 1017 Height_RR 254 "Not initialized" ;
VAL_ 1017 Height_RL 254 "Not initialized" ;
VAL_ 1017 Height_FR 254 "Not initialized" ;
VAL_ 928 CF_Ldws_RecLL 1 "Left line recognized" 0 "Left line unrecognized" ;
VAL_ 928 CF_Ldws_RecRL 1 "Right line recognized" 0 "Right line unrecognized" ;
VAL_ 928 CF_Ldws_FunStop 1 "LDWS function is stopped by Wiper High mode" 0 "LDWS operate at normal condition" ;
VAL_ 928 CF_Ldws_HbaLamp 1 "HBA Indicator Lamp On" 0 "HBA Indicator Lamp Off" ;
VAL_ 928 CF_Ldws_SysStat 7 "System Fail" 6 "System Not Calibrated" 3 "System On &amp; Lane Unrecognized" 2 "System On &amp; Lane Recognize" 1 "System On" 0 "System Ready" ;
VAL_ 928 CF_Ldws_HbaSysStat 7 "System Fail" 2 "HBA ON &amp; High Beam ON" 1 "HBA ON &amp; High Beam OFF" 0 "HBA OFF" ;
VAL_ 928 CF_Ldws_RHWarning 3 "Reserved" 2 "Lane departure second step warning engaged" 1 "Lane departure first step warning engaged" 0 "None Warning is generated" ;
VAL_ 928 CF_Ldws_SpdExceed 1 "Over threshold speed" 0 "Under threshold speed" ;
VAL_ 928 CF_Ldws_TurnSigLh 1 "ON" 0 "OFF" ;
VAL_ 928 CF_Ldws_TurnSigRh 1 "ON" 0 "OFF" ;
VAL_ 928 CF_Ldws_HapWarning 1 "Operate haptic warning" 0 "No operation" ;
VAL_ 928 CF_Ldws_LHWarning 3 "Reserved" 2 "Lane departure second step warning engaged" 1 "Lane departure first step warning engaged" 0 "None Warning is generated" ;
VAL_ 914 CF_Mdps_Stat 15 "Not Available" 7 "Steering aborted the automatic function" 6 "Steering went to error internally" 5 "Steering requested to go to final activation step" 4 "Steering requested to go to first activation step" 3 "Steering set in standby by SPAS" 2 "Steering ready, waits for SPAS command" 1 "Steering still in initialization phase" 0 "Reserved" ;
VAL_ 912 CF_Spas_Stat 7 "SPAS_Abort" 6 "SPAS_Failure" 5 "SPAS_Angle_Control_Active" 4 "SPAS_Active" 3 "SPAS_Standby" 2 "SPAS_NewStart" 1 "SPAS_Init" 0 "Reserved" ;
VAL_ 912 CF_Spas_TestMode 1 "SPAS is in Test Mode" 0 "SPAS is not in Test Mode" ;
VAL_ 907 CF_Opi_Hall_Fail 1 "Failure Detected" 0 "No Failure Detected" ;
VAL_ 907 CF_Opi_Over_Vol 1 "Failure Detected" 0 "No Failure Detected" ;
VAL_ 907 CF_Opi_Over_Cur 1 "Failure Detected" 0 "No failure Detected" ;
VAL_ 907 CF_Opi_Flt 1 "Failure Detected" 0 "No Failure Detected" ;
VAL_ 907 CF_Opi_Motor_Dir 1 "Counter Clock Wise(CCW)" 0 "Clock Wise(CW)" ;
VAL_ 907 CF_Opi_Over_Temp 1 "Failure Detected" 0 "No Failure Detected" ;
VAL_ 904 CF_VSM_Stat 3 "Permanently not available" 2 "Temporarily not available" 1 "Available" 0 "Not applicable" ;
VAL_ 904 CF_VSM_DecCmdAct 1 "Request valid" 0 "No request" ;
VAL_ 904 CF_VSM_ConfMode 7 "Reserved" 6 "Reserved" 5 "Reserved" 4 "Reserved" 3 "Reserved" 2 "CDM On" 1 "CDM Off" 0 "Reserved" ;
VAL_ 904 CF_VSM_Warn 3 "Warning level 3" 2 "Warning level 2" 1 "Warning level 1" 0 "No warning" ;
VAL_ 904 CF_VSM_Prefill 1 "Pre-fill" 0 "No pre-fill" ;
VAL_ 904 CF_VSM_HBACmd 3 "Lowered threshold 3" 2 "Lowered threshold 2" 1 "Lowered threshold 1" 0 "Standard threshold" ;
VAL_ 904 CF_VSM_BeltCmd 2 "Haptic warning" 1 "Pre-crash full retraction" 0 "Release / No alert" ;
VAL_ 904 CR_VSM_Alive 15 "Signal Invalid" ;
VAL_ 901 CF_VSM_Handshake 1 "Okay" 0 "Not okay" ;
VAL_ 901 CF_VSM_ConfSwi 3 "Error Identifier (switch failure detected by ESC or CAN communication failure)" 2 "Reserved" 1 "Switch Pressed" 0 "Switch Not Pressed" ;
VAL_ 901 CF_DriBkeStat 1 "Driver is braking" 0 "Driver is not braking / failure" ;
VAL_ 901 CR_ESP_Alive 15 "Signal Invalid" ;
VAL_ 901 CF_VSM_Coded 1 "Coded" 0 "Not coded" ;
VAL_ 901 CF_VSM_Avail 3 "Permanently not available" 2 "Temporarily not available" 1 "Available" 0 "Not available" ;
VAL_ 900 CF_Ems_SwiOffIC2 1 "Switch Off" 0 "Switch On" ;
VAL_ 900 CF_Ems_SwiOffIC1 1 "Switch Off" 0 "Switch On" ;
VAL_ 900 CF_Ems_DiagReqHDEV 1 "Result requested" 0 "Result not equested" ;
VAL_ 900 CF_Ems_DiagFulHDEV 1 "Condition fulfilled" 0 "Condition not fulfilled" ;
VAL_ 900 CF_Ems_MtGearDisp 7 "Reserved" 6 "No information (No signal of gear position switch.)" 5 "R" 4 "More than 4th speed" 3 "3rd speed" 2 "2nd speed" 1 "1st speed" 0 "N" ;
VAL_ 898 CF_Ems_OPSFail 1 "fail" 0 "ok" ;
VAL_ 898 CF_Ems_RepModChk 3 "Reserved" 2 "Reprogramming condition NG" 1 "Reprogramming condition OK" 0 "Normal state" ;
VAL_ 898 CF_Ems_AAFOpenReq 1 "AAF open request" 0 "None" ;
VAL_ 898 CF_Ems_DnShftReq 14 "Reserved" 13 "Reserved" 12 "Reserved" 11 "Reserved" 10 "Reserved" 9 "Reserved" 8 "Downshift request to 8th gear" 7 "Downshift request to 7th gear" 6 "Downshift request to 6th gear" 5 "Downshift request to 5th gear" 4 "Downshift request to 4th gear" 3 "Downshift request to 3rd gear" 2 "Downshift request to 2nd gear" 1 "Downshift request to 1st gear" 0 "Downshift control request is not active" ;
VAL_ 898 CF_Ems_BrkReq 1 "Brake control request is active" 0 "Brake control request is not active" ;
VAL_ 896 CF_DiBox_SPIErrSedMSV 1 "ERROR" 0 "NO ERROR" ;
VAL_ 896 CF_DiBox_SPIErrFrtMSV 1 "ERROR" 0 "NO ERROR" ;
VAL_ 896 CF_DiBox_IniStatMSV 1 "SUCCESS" 0 "NO SUCESS" ;
VAL_ 896 CF_DiBox_IDErrFrtMSV 1 "ERROR" 0 "NO ERROR" ;
VAL_ 896 CF_DiBox_IDErrSedMSV 1 "ERROR" 0 "NO ERROR" ;
VAL_ 880 TQI_TCU_INC 255 "Max. Increase" 0 "No request" ;
VAL_ 880 CF_Tcu_TarGr 14 "Reverse speed" 8 "8th speed" 7 "7th speed" 6 "6th speed" 5 "5th speed" 4 "4th speed" 3 "3rd speed" 2 "2nd speed" 1 "1st speed" 0 " if N or P are detected (no frictional connection)" ;
VAL_ 880 CF_Tcu_InhCda 1 "TCU prohibits CDA transition" 0 "CDA transition is available" ;
VAL_ 880 CF_Tcu_InhVis 1 "TCU inhibits ECU from changing VGIS status" 0 "There¡¯s no request from TCU" ;
VAL_ 880 CF_Tcu_NCStat 3 "NC Exit" 2 "NC Applied" 1 "NC Entry" 0 "No NC" ;
VAL_ 880 CF_Tcu_SptRdy 1 "Ready" 0 "Not Ready" ;
VAL_ 880 CF_Tcu_ITPhase 1 "Inertia Phase(Real Shifting)" 0 "In-Gear" ;
VAL_ 880 CF_Tcu_PRelReq 1 "E-shifter Parking Release" 0 "No Request" ;
VAL_ 880 CF_Tcu_ShfPatt 15 "None of the above" 9 "Sport Drive (Optional)" 8 "Active ECO (Optional)" 7 "Cruise_Uphill 2 (Optional)" 6 "Cruise_Uphill 1 (Optional)" 5 "Cruise (Optional)" 4 "Downhill 1 (Optional)" 3 "Reserved" 2 "Uphill 2 (Optional)" 1 "Uphill 1 (Optional)" 0 "Normal (ECO)" ;
VAL_ 880 CF_Tcu_BkeOnReq 1 "Brake On Request" 0 "No request" ;
VAL_ 880 CF_Tcu_IsgInhib 1 "ISG is available" 0 "TCU inhibits the ISG function" ;
VAL_ 880 CF_Tcu_SbwPInfo 1 "non P" 0 "P" ;
VAL_ 880 CF_Tcu_TqGrdLim 255 "No torque gradient limitation" ;
VAL_ 880 CF_Tcu_ActEcoRdy 1 "Ready" 0 "Not Ready" ;
VAL_ 852 CF_Lvr_SftButStat 3 "Fault" 2 "Safety Button On" 1 "Safety Button Off" 0 "Not supported" ;
VAL_ 852 CF_Lvr_GearInf 15 "Fault" 9 "Initial value" 8 "Gear lever position in Sport mode/ Manual mode" 7 "Gear lever position R" 6 "Gear lever position N" 5 "Gear lever position D" 0 "Gear lever position P" ;
VAL_ 852 CF_Lvr_PosInf 15 "Fault " 12 "Gear lever position ¡°M -¡±" 11 "Gear lever position ¡°M+¡±" 10 "Gear lever position M (Ds)" 9 "Nd" 8 "Nr" 7 "Gear lever position D" 6 "Intermediate position N-D" 5 "Gear lever position N" 4 "Intermediate position R-N" 3 "Gear lever position R" 2 "Intermediate position P-R" 1 "Gear lever position P" 0 "Initial value" ;
VAL_ 852 CF_Lvr_PRelStat 1 "Parking Released" 0 "Parking Not Released" ;
VAL_ 848 CF_Fatc_ActiveEco 1 "Active ECO Button is selected" 0 "Active ECO Button is not selected" ;
VAL_ 848 CF_Fatc_AcnCltEnRq 1 "A/C clutch enable request" 0 "A/C clutch disable request" ;
VAL_ 848 CF_Fatc_IsgStopReq 1 "Disable (Engine Stop is prohibited)" 0 "Enable" ;
VAL_ 848 CF_Fatc_PtcRlyStat 1 "PTC Relay On" 0 "PTC Relay Off" ;
VAL_ 848 CF_Fatc_EngStartReq 1 "Engine Auto Start Request" 0 "Normal" ;
VAL_ 848 CF_Fatc_AutoActivation 1 "Automatic control is Active" 0 "invalid" ;
VAL_ 848 CF_FATC_Iden 3 "FATC Type 3 (reserved)" 2 "FATC Type 2 (Halla)" 1 "FATC Type 1 (Doowon)" 0 "FATC Type 0 (reserved)" ;
VAL_ 848 CF_Fatc_Compload 3 "A/C On and Engine Speed 2 stage up request" 2 "A/C On and Engine Speed 1 stage up request" 1 "A/C On request" 0 "A/C Off request" ;
VAL_ 848 CF_Fatc_AcnRqSwi 1 "A/C on request" 0 "A/C off request" ;
VAL_ 848 CF_Fatc_BlwrMax 1 "Max blower speed is selected" 0 "Max blower speed is not selected" ;
VAL_ 848 CF_Fatc_EcvFlt 1 "A/C on request" 0 "A/C off request" ;
VAL_ 848 CF_Fatc_BlwrOn 1 "HVAC Blower on" 0 "HVAC Blower off" ;
VAL_ 848 CF_Fatc_CtrInf 3 "Fixed Compressor" 2 "External Compressor without Comp clutch" 1 "External Compressor with Comp clutch" 0 "Internal Compressor" ;
VAL_ 816 CR_Tcu_TqDec 255 "No Decrease" 0 "Max. Decrease" ;
VAL_ 816 CR_Tcu_TqInc 255 "Max. Increase" 0 "No Increase" ;
VAL_ 816 CF_Tcu_CltStat 3 "1 clutch locked" 2 "Even Clutch slipping" 1 "Odd Clutch slipping" 0 "Drivetrain (both clutches) open" ;
VAL_ 816 CF_Tcu_FuelCutReq 1 "Activation of Fuel Cut request" 0 "No Fuel Cut request" ;
VAL_ 816 CF_Tcu_ChgInhAC 1 "Freeze AC clutch" 0 "-" ;
VAL_ 816 CF_Tcu_DriWarn2 3 "Start Hold" 2 "None-EOL" 1 "Clutch OFF" 0 "Normal Display" ;
VAL_ 816 CF_Tcu_TqIncReq 1 "Torque increase controls" 0 "Passive" ;
VAL_ 816 CF_Tcu_StRelStat 1 "Start release NOT ready" 0 "Start release ready" ;
VAL_ 816 CR_Tcu_ShiftTq 255 "Max. Increase" 0 "No Increase" ;
VAL_ 809 TPS 255 "Throttle defective" 245 "Throttle perpendicular" 32 "Idle (port value is learnt)" ;
VAL_ 809 GP_CTL 3 "Reserved" 2 "System Error" 1 "Glow plug on request" 0 "Glow plug off request" ;
VAL_ 809 ACC_ACT 1 "Auto cruise control is active " 0 "Auto cruise control is not active" ;
VAL_ 809 CLU_ACK 1 "Clutch is operating" 0 "Clutch is not operating" ;
VAL_ 809 ENG_CHR 9 "Fuel - FFV ETC -Applied" 8 "Fuel - FFV ETC- No" 7 "Fuel - Gasoline GDI, ETC-Applied" 6 "Fuel - Diesel, ETC - Applied" 5 "Fuel - LPI(LPG), ETC - Applied" 4 "Fuel - Gasoline, ETC - Applied" 3 "Fuel - Gasoline GDI, ETC -No" 2 "Fuel - Diesel, ETC - No" 1 "Fuel - Diesel, ETC - No" 0 "Fuel - Gasoline, ETC - No" ;
VAL_ 809 CONF_TCU 15 "M/T vehicle" 11 "DCT vehicle (DCT A/T)" 10 "CVT vehicle (CVT A/T)" 0 "A/T vehicle (Step Shift A/T)" ;
VAL_ 809 MUL_CODE 3 "TQ_STND" 2 "OBD_FRF_ACK" 1 "CONF_TCU" 0 "CAN_VERS" ;
VAL_ 809 BRAKE_ACT 3 "Brake switch failure" 2 "Brake switch is pressed (ON)" 1 "Brake switch is not pressed (OFF)" 0 "EMS does not support this function." ;
VAL_ 809 PV_AV_CAN 255 "Accelerator Pedal is defective (fail state) or
Non-ETC system (APS is not installed)" 254 "Accelerator Pedal fully activated" 0 "Accelerator Pedal not activated" ;
VAL_ 809 OD_OFF_REQ 1 "Over drive off request to TCU by the cruise control function" 0 "Normal operation" ;
VAL_ 809 VB_OFF_ACT 1 "battery disconnection detected and failure memory erased" 0 "no battery disconnection detected" ;
VAL_ 809 CONF_MIL_FMY 5 "MIL Treatment K-OBD, Failure Memory Management K-OBD" 4 "MIL Treatment E-OBD, Failure Memory Management E-OBD" 3 "MIL Treatment OBD-II, Failure Memory Management OBD-II" 2 "MIL Treatment OBD-II, Exception : CARB_COMP_OBD" 1 "MIL Treatment OBD-I, Failure Memory Management OBD-I" 0 "no MIL, Failure Memory Management OBD-I" ;
VAL_ 809 ACK_ES 1 "Acknowledgement 'engine stopped'" 0 "No acknowledgement" ;
VAL_ 790 RLY_AC 1 "Air conditioner compressor relay ON" 0 "Air conditioner compressor relay OFF" ;
VAL_ 790 ACK_TCS 1 "TCS message received, and no plausibility error" 0 "TCS message not received within the last 500 ms, or a plausibility error in torque intervention is 'ON'" ;
VAL_ 790 SWI_IGK 1 "KEY ON" 0 "KEY OFF, control unit in self-holding phase" ;
VAL_ 790 PUC_STAT 1 "Engine in fuel cut off" 0 "Engine not in fuel cut off" ;
VAL_ 790 F_SUB_TQI 1 "Error on Torque Measurement" 0 "No error" ;
VAL_ 790 TQ_COR_STAT 3 "Due to a failure detected by a diagnosis function of the engine management system, the desired torque intervention for TCS regarding the ignition angle and cylinder shut-off is no longer executed.
The torque intervention is terminated, the engine managemen" 2 "The torque reduction regarding the ignition angle retardation cannot be completely executed. A cylinder shut-off is not possible at this time. Therefore a remaining torque (as difference between TQI_ASR/GS_REQ and TQI_INTV) is present and cannot be reduced" 1 "The desired intervention regarding ignition angle retardation and cylinder shut-off is executed; however, the requested target torque can not be adjusted precisely (torque steps)" 0 "The desired intervention regarding ignition angle retardation and cylinder shut-off is executed. (Default value)" ;
VAL_ 790 F_N_ENG 1 "Engine speed sensor defective" 0 "No error" ;
VAL_ 704 CF_SBR_Ind 3 "Not used" 2 "SBR Lamp flash" 1 "SBR Lamp off" 0 "SBR Lamp on" ;
VAL_ 704 CF_SWL_Ind 3 "Not used" 2 "Warning Lamp flash" 1 "Warning Lamp off" 0 "Warning Lamp on" ;
VAL_ 704 CF_TTL_Ind 3 "Not used" 2 "Telltale Lamp flash" 1 "Telltale Lamp off" 0 "Telltale Lamp on" ;
VAL_ 672 SwitchOffCondExt 1 "Switch off condition detected" 0 "No switch off condition detected" ;
VAL_ 672 FA_PV_CAN 255 "Accelerator Pedal is defective (fail state) or
Non-ETC system (APS is not installed)" 254 "Accelerator Pedal fully activated" 0 "Accelerator Pedal not activated" ;
VAL_ 672 ECGPOvrd 1 "Driver Override" 0 "No Driver Override" ;
VAL_ 672 BLECFail 1 "Failure detected" 0 "No Failure detected" ;
VAL_ 672 INH_DC_OBD 1 "Inhibition of standardized vehicle operation and all numerators/denominators for RMB" 0 "Enable of standardized vehicle operation and all numerators/denominators for RBM" ;
VAL_ 672 ECFail 1 "Failure detected" 0 "No Failure detected" ;
VAL_ 672 QECACC 1 "Failure detected" 0 "No Failure detected" ;
VAL_ 640 LV_CRASH 1 "Activation" 0 "Deactivation" ;
VAL_ 640 LV_GSL_MAP 1 "MAP signal send" 0 "AMP signal send" ;
VAL_ 640 LV_ENG_TURN 1 "Activation" 0 "Deactivation" ;
VAL_ 640 LV_BFS_CFIRM 1 "Confirmed" 0 "Not Confirmed" ;
VAL_ 640 LV_VB_OFF_ACT 1 "Activation" 0 "Deactivation" ;
VAL_ 640 LV_FUEL_TYPE_ECU 1 "Gas" 0 "Gasoline" ;
VAL_ 625 LV_GAS_OK 1 "Gas system is OK" 0 "Gas system is not OK" ;
VAL_ 625 LV_PRE_CDN_LEAK 1 "Active" 0 "Not Active" ;
VAL_ 625 LV_FUEL_TYPE_BOX 1 "Gas" 0 "Gasoline" ;
VAL_ 625 LV_BFS_IN_PROGRESS 1 "Progress" 0 "No progress" ;
VAL_ 625 LV_LPG_SW_DRIVER_REQ 1 "LPG Switch Pressed" 0 "LPG Switch Not Pressed" ;
VAL_ 625 LV_CONF_INJECTION_DELAY 1 "Active" 0 "Not Active" ;
VAL_ 625 LV_FUP_ENA_THD 1 "The pressure is enough high to start engine" 0 "The pressure is too low to start engine" ;
VAL_ 608 SOAK_TIME_ERROR 1 "Failure detected" 0 "No Failure detected" ;
VAL_ 608 PRE_FUEL_CUT_IN 1 "Indication of fuel cut in previous to stop fuel cut off" 0 "Continue to fuel cut off control" ;
VAL_ 608 CRUISE_LAMP_S 1 "Cruise SET switch indication lamp turn ON" 0 "Cruise SET switch indication lamp turn OFF" ;
VAL_ 608 CRUISE_LAMP_M 1 "Cruise MAIN switch indication lamp turn ON" 0 "Cruise MAIN switch indication lamp turn OFF" ;
VAL_ 608 CF_Ems_AclAct 3 "Accelerator pedal position sensor failure" 2 "Reserved" 1 "Accelerator pedal pressed" 0 "Accelerator pedal not pressed" ;
VAL_ 608 GLOW_STAT 1 "Lamp On" 0 "Lamp Off" ;
VAL_ 608 ENG_STAT 7 "Fault" 6 "Reserved" 5 "Reserved" 4 "Reserved" 3 "Running" 2 "Stalled" 1 "Cranking" 0 "Engine Stop" ;
VAL_ 592 CF_Mdps_ToiActive 1 "Activated" 0 "Deactivated" ;
VAL_ 592 CF_Mdps_ToiUnavail 1 "Unavailable" 0 "Available" ;
VAL_ 592 CF_Mdps_FailStat 1 "In fail state" 0 "Not in fail state" ;
VAL_ 592 CF_Mdps_ToiFlt 1 "Faulty" 0 "No fault" ;
VAL_ 584 CF_Lkas_ActToi 1 "Activate TOI" 0 "De-activate TOI" ;
VAL_ 584 CF_Lkas_ToiFlt 1 "Fault Present" 0 "No Fault" ;
VAL_ 544 YAW_RATE_DIAG 1 "Yaw rate signal is not available temporarily" 0 "Yaw rate signal is available" ;
VAL_ 544 YAW_RATE_STAT 1 "Yaw rate sensor signal is invalid" 0 "Yaw rate sensor signal is valid" ;
VAL_ 544 CYL_PRESS_DIAG 1 "Master cylinder pressure is not available temporarily" 0 "Master cylinder pressure signal is available" ;
VAL_ 544 LAT_ACCEL_DIAG 1 "Lateral acceleration signal is not available temporarily" 0 "Lateral acceleration signal is available" ;
VAL_ 544 LAT_ACCEL_STAT 1 "Lateral acceleration signal is invalid" 0 "Lateral acceleration signal is valid" ;
VAL_ 544 LONG_ACCEL_DIAG 1 "Longitudinal acceleration signal is not available temporarily" 0 "Longitudinal acceleration signal is available" ;
VAL_ 544 LONG_ACCEL_STAT 1 "Longitudinal acceleration signal is invalid" 0 "Longitudinal acceleration signal is valid" ;
VAL_ 544 CYL_PRES_STAT 1 "Master cylinder pressure signal is invalid" 0 "Master cylinder pressure signal is valid" ;
VAL_ 497 EBD_W_LAMP 1 "EBD Warning lamp ON" 0 "EBD Warning lamp OFF" ;
VAL_ 497 DBC_W_LAMP 1 "DBC Warning lamp ON" 0 "DBC Warning lamp OFF" ;
VAL_ 497 DBC_F_LAMP 3 "Reserved" 2 "DBC Function lamp BLINKING(2Hz)" 1 "DBC Function lamp ON" 0 "DBC Function lamp OFF" ;
VAL_ 497 ABS_W_LAMP 1 "ABS Warning lamp ON" 0 "ABS Warning lamp OFF" ;
VAL_ 497 TCS_LAMP 3 "Reserved" 2 "TCS/ESC Function/Warning Lamp BLINKING(2Hz)" 1 "TCS/ESC Function/Warning Lamp ON" 0 "TCS/ESC Function/Warning Lamp OFF" ;
VAL_ 497 TCS_OFF_LAMP 1 "TCS/ESC OFF SW Lamp ON" 0 "TCS/ESC OFF SW Lamp OFF" ;
VAL_ 496 SA_Z_FLAG 1 "Zero point detection" 0 "No zero point detection" ;
VAL_ 399 CF_Ems_OilChg 1 "OIL LEVEL LAMP On" 0 "OIL LEVEL LAMP Off" ;
VAL_ 399 CF_Ems_EtcLimpMod 1 "ETC Limphome mode by ECU" 0 "Engine control is available" ;
VAL_ 399 CF_Ems_EngRunNorm 1 "Engine Running" 0 "Engine Stop or Starting Phase" ;
VAL_ 399 CF_Ems_SldPosAct 1 "Positive action is active" 0 "Positive action is not active" ;
VAL_ 399 CF_Ems_IdlStpFCO 1 "Fuel consumption(=1mL)" 0 "Not fuel consumption" ;
VAL_ 399 CF_Ems_HPresStat 1 "Fuel Tank is in high Pressure" 0 "Fuel Tank is not in high Pressure" ;
VAL_ 399 CF_Ems_DownTarGr 1 "Gear Shiftdown Display On" 0 "Gear Shiftdown Display Off" ;
VAL_ 399 CF_Ems_ActEcoAct 1 "Active Eco Drive is active" 0 "Active Eco Drive is not active" ;
VAL_ 399 CF_Ems_IsgStat2 3 "two wheel test mode" 2 "In Auto Start status, when rapidly accelerating before complete gear shift. (Economy ISG Only)" 1 "The condition for not-activated battery sensor. (Except EOL condition.)" 0 "Default" ;
VAL_ 399 CF_Ems_DesCurGr 7 "Error ID" 6 "Gear Position '6' display" 5 "Gear Position '5' display" 4 "Gear Position '4' display" 3 "Gear Position '3' display" 2 "Gear Position '2' display" 1 "Gear Position '1' display" 0 "No display" ;
VAL_ 399 CF_Ems_UpTarGr 1 "Gear Shiftup Display On" 0 "Gear Shiftup Display Off" ;
VAL_ 399 CF_Ems_SldAct 1 "Speed limiter function is active" 0 "Speed limiter function is not active" ;
VAL_ 399 CF_Ems_IsgBuz 1 "Request buzzer ON " 0 "Initial Value " ;
VAL_ 399 CF_CdaStat 7 "Fault in CDA operation" 6 "Reserved" 5 "Reserved" 4 "Reserved" 3 "Reserved" 2 "CDA ON (Solenoid Valve ON)" 1 "Preparation for CDA operation" 0 "CDA OFF (Solenoid Valve OFF)" ;
VAL_ 387 CF_EndBst_RamFlt 1 "Error" 0 "No Error" ;
VAL_ 387 CF_EndBst_HbriOverCur 1 "Error" 0 "No Error" ;
VAL_ 387 CF_EndBst_PosSnsOSOR 1 "Error" 0 "No Error" ;
VAL_ 387 CF_EndBst_PosSnsKOR 1 "Error" 0 "No Error" ;
VAL_ 387 CF_EndBst_AgH 1 "Error" 0 "No Error" ;
VAL_ 387 CF_EndBst_AgL 1 "Error" 0 "No Error" ;
VAL_ 387 CF_EndBst_ORVol 1 "Error" 0 "No Error" ;
VAL_ 387 CF_EndBst_CanFlt 1 "Error" 0 "No Error" ;
VAL_ 387 CF_EndBst_EepFlt 1 "Error" 0 "No Error" ;
VAL_ 387 CF_EndBst_PwmDuH 1 "Error" 0 "No Error" ;
VAL_ 387 CF_EndBst_PwmDuL 1 "Error" 0 "No Error" ;
VAL_ 387 CF_EndBst_HbriOverTemp 1 "Error" 0 "No Error" ;
VAL_ 387 CF_EndBst_PwmFqOutRng 1 "Error" 0 "No Error" ;
VAL_ 387 CF_EndBst_RomFlt 1 "Error" 0 "No Error" ;
VAL_ 357 CF_Mdps_Def 1 "MDPS is defective" 0 "MDPS is not defective" ;
VAL_ 357 CF_Mdps_SErr 1 "VSM1 signal is error" 0 "VSM1 signal is not error" ;
VAL_ 356 CF_Esc_Act 1 "VSM control active" 0 "VSM control inactive0H" ;
VAL_ 356 CF_Esc_Def 1 "VSM is defective" 0 "VSM is not defective" ;
VAL_ 356 CF_Esc_CtrMode 3 "Mode 3 (Particular control)" 2 "Mode 2 (output torque overlay mode)" 1 "Mode 1 (sensor value overlay mode)" 0 "Inactive" ;
VAL_ 339 ABS_ACT 1 "ABS control active" 0 "ABS control inactive" ;
VAL_ 339 EBD_DEF 1 "EBD is defective" 0 "EBD is not defective" ;
VAL_ 339 TCS_GSC 1 "active (gear change not allowed)" 0 "passive (gear change allowed)" ;
VAL_ 339 TCS_REQ 1 "TCS/ESC control active" 0 "Passive" ;
VAL_ 339 ABS_DIAG 1 "ABS/TCS/ESC is diagnostic mode" 0 "ABS/TCS/ESC is not diagnostic mode" ;
VAL_ 339 ESS_STAT 3 "ESS extended function 'active' (Hazard lamp blinking)" 2 "ESS system is defective" 1 "ESS control ¡°active¡± (Emergency stop condition)" 0 "ESS control ¡°inactive¡± (Normal condition)" ;
VAL_ 339 TCS_MFRN 1 "Using TQI_TCS only (Not using TQI_SLW_TCS)" 0 "Using both TQI_TCS and TQI_SLW_TCS" ;
VAL_ 339 MSR_C_REQ 1 "MSR control active" 0 "Passive or TCS function" ;
VAL_ 339 ESC_OFF_STEP 3 "ESC OFF SW is defective(failed)" 2 "STEP 2" 1 "STEP 1" 0 "Normal" ;
VAL_ 339 CF_Esc_BrkCtl 1 "Brake control is in activation" 0 "Brake control is not in activation" ;
VAL_ 339 CF_Esc_LimoInfo 3 "Vehicle is Limo" 2 "Vehicle is not Limo" 1 "Invalid" 0 "Invalid" ;
VAL_ 339 ABS_DEF 1 "ABS is defective" 0 "ABS is not defective" ;
VAL_ 320 CF_Yrs_Type 1 "Yaw rate-Support, Lateral acceleration-Support, Longitudinal acceleration-Support" 0 "Yaw rate-Support, Lateral acceleration-Support, Longitudinal acceleration-Not support" ;
VAL_ 288 CF_Smk_PassUk 7 "Unlock DRV door only" 6 "Unlock No4" 5 "Unlock No3" 4 "PIC Key Reminder" 3 "Unlock" 2 "Unlock No2" 1 "Unlock No1" 0 "None" ;
VAL_ 288 CF_Smk_PassLk 5 "Lock No4" 4 "Lock No3" 3 "Lock" 2 "Lock No2" 1 "Lock No1" 0 "None" ;
VAL_ 288 CF_Smk_DactWarn 1 "Warning ON" 0 "Warning OFF" ;
VAL_ 288 CF_Smk_ImmoLamp 3 "Default" 2 "On" 1 "Blinking" 0 "Off" ;
VAL_ 288 CF_Smk_DiagState 1 "Start Diag" 0 "Stop Diag" ;
VAL_ 288 CF_Smk_IdOutWarn 1 "Warning ON" 0 "Warning OFF" ;
VAL_ 288 CF_Smk_BatDchWarn 1 "Warning ON" 0 "Warning OFF" ;
VAL_ 288 CF_Smk_KeyOutLamp 1 "Blinking" 0 "Off" ;
VAL_ 288 CF_Smk_StrRlyStat 1 "On" 0 "Off" ;
VAL_ 288 CF_Smk_EsclFailWarn 1 "Warning ON" 0 "Warning OFF" ;
VAL_ 288 CF_Smk_NotPWarnStat 1 "Warning ON" 0 "Warning OFF" ;
VAL_ 288 CF_Smk_EsclNotLkWarn 1 "Warning ON" 0 "Warning OFF" ;
VAL_ 288 CF_Smk_EsclNotUkWarn 1 "Warning ON" 0 "Warning OFF" ;
VAL_ 288 CF_Smk_SsbWarn 1 "Warning ON" 0 "Warning OFF" ;
VAL_ 288 CF_Smk_DisCmd 15 "Reserved" 14 "PN Switch off Warning" 13 "Stop Lamp Fuse Fail Warning" 12 "Vehicle Not P Warning" 11 "AUTH Fail Warning2" 10 "SSB Warning" 9 "PIC Lamp Warning" 8 "Key Removal IND" 7 "AUTH Fail Warning" 6 "Eng Start Operation IND" 5 "ESCL ECU Fail Warning" 4 "Not Locked Warning" 3 "Not Unlocked Warning" 2 "Key BAT Discharge Warning" 1 "Shift P Warning" 0 "Off" ;
VAL_ 272 CF_Gway_LigCur 3 "Invalid" 2 "On (Enable)" 1 "Off (Disable)" 0 "Default Value" ;
VAL_ 272 CF_Gway_SunroofOpenWarning 1 "On (Condition for Sunroof open warning)" 0 "Off (No condition for warning)" ;
VAL_ 272 CF_Gway_ScmCur 3 "Invalid" 2 "On (Enable)" 1 "Off (Disable)" 0 "Default Value" ;
VAL_ 272 CF_Gway_DrLkCur 4 "Invalid" 3 "Shift Lever On" 2 "Vehicle Speed On" 1 "Off" 0 "Default Value" ;
VAL_ 272 CF_Gway_DrUkCur 5 "Invalid" 4 "Override On" 3 "Shift Lever On" 2 "Key Out On" 1 "Off" 0 "Default Value" ;
VAL_ 272 CF_Gway_HAnBCur 3 "Invalid" 2 "On" 1 "Off" 0 "Default" ;
VAL_ 272 CF_Gway_LDMFail 3 "Invalid" 2 "LED Fan fail" 1 "LED Head lamp fail" 0 "Default Value" ;
VAL_ 272 CF_Gway_SBLStatL 1 "On" 0 "Off" ;
VAL_ 272 CF_Gway_SBLStatR 1 "On" 0 "Off" ;
VAL_ 272 CF_Gway_ATTurnCur 3 "Invalid" 2 "On (Enable)" 1 "Off (Disable)" 0 "Default Value" ;
VAL_ 272 CF_Gway_BrkeFluid 1 "On" 0 "Off" ;
VAL_ 272 CF_Gway_BuzzerCur 3 "Invalid" 2 "On (Enable)" 1 "Off (Disable)" 0 "Default Value" ;
VAL_ 272 CF_Gway_EscortCur 3 "Invalid" 2 "On (Enable)" 1 "Off (Disable)" 0 "Default Value" ;
VAL_ 272 CF_Gway_PassingSW 1 "SW On" 0 "SW Off     " ;
VAL_ 272 CF_Gway_RLWdwStat 1 " Window Open" 0 "Window Close" ;
VAL_ 272 CF_Gway_TurnUkCur 3 "Invalid" 2 "On (Enable)" 1 "Off (Disable)" 0 "Default Value" ;
VAL_ 272 CF_Gway_DRVWdwStat 1 "Window Open" 0 "Window Close" ;
VAL_ 272 CF_Gway_HotShotIND 4 "HotShotReady" 3 "HotShotRestart" 2 "HotShotEnd" 1 "HotShotStart" 0 "Not Used" ;
VAL_ 272 CF_Gway_MirFoldCur 3 "Invalid" 2 "On" 1 "Off(Disable)" 0 "Default Value" ;
VAL_ 272 CF_Gway_ButSysVarInd 1 "Push button start Option." 0 "No push button start Option." ;
VAL_ 272 CF_Gway_RRDRVWdwStat 1 "Window Open" 0 "Window Close" ;
VAL_ 272 CF_Gway_ASTDRVWdwStat 1 "Window Open" 0 "Window Close" ;
VAL_ 272 CF_Gway_PsmCur 7 "Invalid" 6 "Reserved" 5 "Reserved" 4 "Reserved" 3 "75mmOn (Enable)" 2 "50mmOn (Enable)" 1 "Off (Disable)" 0 "Default Value" ;
VAL_ 129 BRAKE_ACT 3 "Brake switch Failure" 2 "Brake switch surely pressed" 1 "Brake switch not pressed(off)" 0 "Brake switch possibly pressed" ;
VAL_ 128 F_SUB_TQI 1 "Error on Torque Measurement" 0 "No error" ;
VAL_ 128 PV_AV_CAN 255 "Accelerator Pedal is defective (fail state) or Non-ETC system (APS is not installed)" 254 "Accelerator Pedal fully activated" 0 "Accelerator Pedal not activated" ;
VAL_ 128 F_N_ENG 1 "Engine speed sensor defective" 0 "No error" ;
VAL_ 80 CF_Gway_AmpInfo 3 "Invalid" 1 "AMP Connected" 0 "Off" ;
VAL_ 80 CF_Gway_HeadLampHighSW 1 "Head Lamp High Switch On" 0 "Head Lamp High Switch off" ;
VAL_ 80 CF_Gway_TSigRHSW 1 "On" 0 "Off" ;
VAL_ 80 CF_Gway_WiperLow 1 "On" 0 "Off" ;
VAL_ 80 CF_Gway_WiperAuto 1 "On" 0 "Off" ;
VAL_ 80 CF_Gway_WiperHigh 1 "On" 0 "Off" ;
VAL_ 80 CF_Gway_WiperIntT 4 "Step5" 3 "Step4" 2 "Step3" 1 "Step2" 0 "Step1" ;
VAL_ 80 CF_Gway_CluModeSet 3 "Error" 2 "Long Key" 1 "Short Key" 0 "Off" ;
VAL_ 80 CF_Gway_LkasMainSW 1 "On" 0 "Off" ;
VAL_ 80 CF_Gway_WiperIntSW 1 "On" 0 "Off" ;
VAL_ 80 CF_Gway_CluGuiCtrSW 4 "Right" 3 "Left" 2 "Down" 1 "Up" 0 "Off" ;
VAL_ 80 CF_Gway_LowLuminous 3 "Not Used" 2 "Head Lamp Low On &amp; Low luminous intensity Condition" 1 "Head Lamp Low On Condition from Auto Light Sensor" 0 "Head Lamp Low Off Condition from Auto Light Sensor" ;
VAL_ 80 CF_Gway_CruiseMainSW 1 "On" 0 "Off" ;
VAL_ 80 CF_Gway_CruiseSWStat 4 "Cancel" 3 "Distance Gap" 2 "Set / Coast" 1 "Resume / Acceleration" 0 "Off" ;
VAL_ 80 CF_Gway_WiperHighAct 1 "Wiper High On" 0 "Wiper High Off" ;
VAL_ 80 CF_Gway_LightSWStatus 3 "Auto Light Switch On" 2 "Head Lamp Low Switch On" 1 "Tail Switch On" 0 "Light Switch off" ;
VAL_ 80 CF_Gway_TSigLHSW 1 "On" 0 "Off" ;
VAL_ 68 CF_Datc_Type 255 "Invalid" 3 "MTC" 2 "FATC" 1 "DATC" 0 "Invalid" ;
VAL_ 68 CR_Datc_OutTempC 255 "Invalid" 254 "Sensor Fail ( '- -'Display )" 1 "Blank Display" 0 "Blank Display" ;
VAL_ 68 CR_Datc_OutTempF 255 "Invalid" 254 "Sensor Fail ( '- -'Display )" 1 "Blank Display" 0 "Blank Display" ;
VAL_ 68 CF_Datc_IncarTemp 255 "Error identifier" ;
VAL_ 67 CF_Datc_DualDisp 3 "Invalid" 2 "Not used" 1 "DUAL On" 0 "DUAL Off" ;
VAL_ 67 CF_Datc_RearClimateScnDisp 3 "Invalid" 2 "Not Used" 1 "Actived" 0 "Deactived" ;
VAL_ 67 CF_Datc_RearChgReqDisp 3 "Invalid" 2 "Not Used" 1 "USER INPUT" 0 "OFF" ;
VAL_ 67 CF_Datc_AutoDefogBlink 3 "Invalid" 2 "Not used" 1 "AutoDefogBlink Request" 0 "Off" ;
VAL_ 67 CF_Datc_TempDispUnit 1 "Fahrenheit(¢µ)" 0 "Centigrade(¡É)" ;
VAL_ 67 CF_Datc_RearAutoDisp 3 "Invalid" 2 "Not Used" 1 "AUTO On" 0 "AUTO Off" ;
VAL_ 67 CF_Datc_FrontBlwDisp 15 "Invalid" 9 "8 Level" 8 "7 Level" 7 "6 Level" 6 "5 Level" 5 "4 Level" 4 "3 Level" 3 "2 Level" 2 "1 Level" 1 "0 Level" 0 "Off" ;
VAL_ 67 CF_Datc_RearOffDisp 3 "Invalid" 2 "¡°OFF¡± Display" 1 "Normal Mode" 0 "off" ;
VAL_ 67 CF_Datc_RearBlwDisp 15 "Invalid" 9 "8 Level" 8 "7 Level" 7 "6 Level" 6 "5 Level" 5 "4 Level" 4 "3 Level" 3 "2 Level" 2 "1 Level" 1 "0 Level" 0 "Off" ;
VAL_ 67 CF_Datc_OpSts 7 "Invalid" 6 "Not used" 5 "Not used" 4 "Not used" 3 "DATC Self Diagnosis" 2 "DATC System Off (Blower Off)" 1 "DATC Normal" 0 "DATC Off (Power Down)" ;
VAL_ 67 CF_Datc_AcDisp 3 "Invalid" 2 "Not used" 1 "A/C ON" 0 "A/C Off" ;
VAL_ 67 CF_Datc_PwrInf 3 "IGN(Ignition2)" 2 "Not used" 1 "Not used" 0 "Off" ;
VAL_ 67 CF_Datc_AqsDisp 3 "Invalid" 2 "Not used" 1 "AQS ON" 0 "AQS Off" ;
VAL_ 67 CF_Datc_ModDisp 6 "AUTO Defog" 5 "DEF" 4 "MIX" 3 "FLOOR" 2 "B/L" 1 "VENT" 0 "OFF" ;
VAL_ 67 CF_Datc_AutoDisp 3 "Invalid" 2 "Not used" 1 "AUTO On" 0 "AUTO Off" ;
VAL_ 67 CF_Datc_FrDefLed 3 "Invalid" 2 "Not used" 1 "On" 0 "Off" ;
VAL_ 67 CF_Datc_IonClean 3 "Invalid" 2 "ION" 1 "CLEAN" 0 "OFF" ;
VAL_ 67 CF_Mtc_MaxAcDisp 3 "Invalid" 2 "Not used" 1 "On" 0 "Off" ;
VAL_ 67 CF_Datc_ChgReqDisp 3 "Invalid" 2 "Not used" 1 "User Input" 0 "OFF" ;
VAL_ 67 CF_Datc_IntakeDisp 3 "Invalid" 2 "Not used" 1 "REC ON (Fresh Off)" 0 "REC Off (Fresh On)" ;
VAL_ 67 CF_Datc_RearManual 3 "Invalid" 2 "Rear Disable" 1 "Rear Enable" 0 "Off" ;
VAL_ 67 CF_Datc_ClmScanDisp 3 "Invalid" 2 "Not used" 1 "Actived" 0 "Deactived" ;
VAL_ 66 CR_Datc_RearDrTempDispC 255 "Invalid" 1 "Blank Display" 0 "Blank Display" ;
VAL_ 66 CR_Datc_DrTempDispF 255 "Invalid" 1 "Blank Display" 0 "Blank Display" ;
VAL_ 66 CR_Datc_PsTempDispC 255 "Invalid" 1 "Blank Display" 0 "Blank Display" ;
VAL_ 66 CR_Datc_RearDrTempDispF 255 "Invalid" 1 "Blank Display" 0 "Blank Display" ;
VAL_ 66 CR_Datc_DrTempDispC 255 "Invalid" 1 "Blank Display" 0 "Blank Display" ;
VAL_ 66 CR_Datc_PsTempDispF 255 "Invalid" 1 "Blank Display" 0 "Blank Display" ;
VAL_ 64 CR_Datc_SelfDiagCode 255 "Invalid" 0 "Blank Display" ;
VAL_ 64 CF_Datc_AqsLevelOut 15 "Invalid" 14 "Not Used" 13 "Not Used" 12 "Not Used" 11 "Not Used" 10 "Not Used" 9 "Not Used" 8 "Not Used" 7 "Not Used" 6 "Not Used" 5 "5 LEVEL" 4 "4 LEVEL" 3 "3 LEVEL" 2 "2 LEVEL" 1 "1 LEVEL" 0 "OFF" ;
VAL_ 64 CF_Datc_DiagMode 3 "Invalid" 2 "Not used" 1 "Diagnosis Code Display" 0 "Off" ;
VAL_ 52 CF_Gway_GradeInf 1 "Invalid" 0 "No Grade" ;
VAL_ 52 CF_Gway_DistributeInf 15 "Invalid" 11 "South America" 10 "Africa" 9 "Middle East" 8 "Australia" 7 "India / Russia" 6 "China" 5 "Western Europe" 4 "Eastern Europe" 3 "Canada" 2 "North America" 1 "Korea" 0 "No Information" ;
VAL_ 52 CF_Gway_DriverInf 1 "RHD" 0 "LHD" ;
VAL_ 24 CF_Gway_TSigLHOut 1 "On" 0 "Off" ;
VAL_ 24 CF_Gway_SunroofOpenWarning 1 "On" 0 "Off" ;
VAL_ 24 CF_Gway_KeyReminderWarning 1 "On" 0 "Off" ;
VAL_ 24 CF_Gway_KeyTeachingSound 1 "On" 0 "Off" ;
VAL_ 24 CF_Gway_SeatBeltWarning 1 "On" 0 "Off" ;
VAL_ 24 CF_Gway_DrvSeatBeltInd 2 "On" 1 "Blink" 0 "Off" ;
VAL_ 24 CF_Gway_IgnSW 7 "Invalid" 4 "Start" 3 "IGN" 2 "ACC" 1 "Key In" 0 "Key Off" ;
VAL_ 24 CF_Gway_SNVSW 1 "SW On" 0 "SW Off" ;
VAL_ 24 CF_Gway_AVTail 1 "On" 0 "Off" ;
VAL_ 24 CF_Gway_RLDrSW 1 "On" 0 "Off" ;
VAL_ 24 CF_Gway_RRDrSW 1 "On" 0 "Off" ;
VAL_ 24 CF_Gway_RkeCmd 15 "Invalid" 10 "Unlock" 9 "Lock" 8 "Unlock No4" 7 "Lock No4" 6 "Unlock No3" 5 "Lock No3" 4 "Unlock No2" 3 "Lock No2" 2 "Unlock No1" 1 "Lock No1" 0 "Null" ;
VAL_ 24 CF_Gway_AstDrSW 1 "On" 0 "Off" ;
VAL_ 24 CF_Gway_DrvDrSW 1 "On" 0 "Off" ;
VAL_ 24 CF_Gway_PICLock 7 "Reserved" 6 "Reserved" 5 "Reserved" 4 "Reserved" 3 "Lock" 2 "Lock &amp; No.2" 1 "Lock &amp; No.1" 0 "None" ;
VAL_ 24 CF_Gway_HoodStat 3 "Invalid" 2 "Reserved" 1 "Hood Open" 0 "Hood Close" ;
VAL_ 24 CF_Gway_RLUnlock 1 "On" 0 "Off" ;
VAL_ 24 CF_Gway_RRUnlock 1 "On" 0 "Off" ;
VAL_ 24 CF_Gway_ASTUnlock 1 "On" 0 "Off" ;
VAL_ 24 CF_Gway_DRVUnlock 1 "On" 0 "Off" ;
VAL_ 24 CF_Gway_PICUnlock 7 "Reserved" 6 "Reserved" 5 "Reserved" 4 "PIC Key Reminder" 3 "Unlock" 2 "Unlock &amp; No.2" 1 "Unlock &amp; No.1" 0 "None" ;
VAL_ 24 CF_Gway_ParkBkeSW 1 "On" 0 "Off" ;
VAL_ 24 CF_Gway_RpasOffSW 1 "On" 0 "Off" ;
VAL_ 24 CF_Gway_ParkingBrakeWarning 1 "On" 0 "Off" ;
VAL_ 24 CF_Gway_TSigRHOut 1 "On" 0 "Off" ;
VAL_ 24 CF_Gway_TrkOpnInd 1 "On" 0 "Off" ;
VAL_ 24 CF_Gway_IRLampACT 1 "ON" 0 "OFF" ;
VAL_ 24 CF_Gway_IRLampFail 1 "Fail" 0 "normal     " ;
VAL_ 24 CF_Gway_RearFogInd 1 "On" 0 "Off" ;
VAL_ 24 CF_Gway_WiperPark 1 "Parking Position " 0 "else" ;
VAL_ 24 CF_Gway_DRVSeatBelt 3 "Invalid" 2 "Failed" 1 "Unbelted" 0 "Belted" ;
VAL_ 24 CF_Gway_DefoggerRly 1 "On" 0 "Off" ;
VAL_ 24 CF_Gway_FrontFogInd 1 "On" 0 "Off" ;
VAL_ 24 CF_Gway_HLLowLHFail 1 "Fail" 0 "Not Fail" ;
VAL_ 24 CF_Gway_PASSeatBelt 3 "Invalid" 2 "Failed" 1 "Unbelted" 0 "Belted" ;
VAL_ 24 CF_Gway_TailLampAct 1 "On" 0 "Off" ;
VAL_ 24 CF_Gway_VehicleInfo 3 "Panic" 2 "Unlock " 1 "Alarm" 0 "Off" ;
VAL_ 24 CF_Gway_DeliveryMode 1 "On (After Delivery)" 0 "Off (Before Delivery)" ;
VAL_ 24 CF_Gway_HLLowRHFail 1 "Fail" 0 "Not Fail" ;
VAL_ 24 CF_Gway_HeadLampHInd 1 "On" 0 "Off" ;
VAL_ 24 CF_Gway_HeadLampLInd 1 "On" 0 "Off" ;
VAL_ 24 CF_Gway_TeleEngState 3 "Invalid" 2 "Stop" 1 "Cranking" 0 "Off" ;
VAL_ 21 CF_Gway_PBackP2Cmd 1 "P2" 0 "None" ;
VAL_ 21 CF_Gway_PBackP1Cmd 1 "P1" 0 "None" ;
VAL_ 21 CF_Gway_MemP2Cmd 1 "P2" 0 "None" ;
VAL_ 21 CF_Gway_MemP1Cmd 1 "P1" 0 "None" ;
VAL_ 21 CF_Gway_DrvKeyUk 1 "On" 0 "Off" ;
VAL_ 21 CF_Gway_DrvKeyLk 1 "On" 0 "Off" ;
VAL_ 20 CF_Clu_EscortCurReq 3 "Invalid" 2 "Not used" 1 "Real value Request" 0 "Off" ;
VAL_ 20 CF_Clu_TurnUkCurReq 3 "Invalid" 2 "Not used" 1 "Real value Request" 0 "Off" ;
VAL_ 20 CF_Clu_LigSet 3 "Invalid" 2 "Welcome Light Enable" 1 "Welcome Light Disable" 0 "Off" ;
VAL_ 20 CF_Clu_PsmSet 7 "Invalid" 6 "Reserved" 5 "Reserved" 4 "Reserved" 3 "75mm On(Enable)" 2 "50mm On(Enable)" 1 "Off(Disable)" 0 "Default Value" ;
VAL_ 20 CF_Clu_ScmSet 3 "Invalid" 2 "Enable" 1 "Disable" 0 "Off" ;
VAL_ 20 CF_Clu_DrLkSet 4 "Invalid" 3 "Shift Lever On" 2 "Vehicle Speed On" 1 "Disable" 0 "Off" ;
VAL_ 20 CF_Clu_DrUkSet 5 "Invalid" 4 "Override" 3 "Shift Lever On" 2 "Key Out On" 1 "Disable" 0 "Off" ;
VAL_ 20 CF_Clu_HAnBSet 3 "Invalid" 2 "Enable" 1 "Disable" 0 "Off" ;
VAL_ 20 CF_Clu_TeleReq 7 "Reserved" 6 "Reserved" 5 "Reserved" 4 "Hazard" 3 "HornHazard" 2 "Lock" 1 "Unlock" 0 "Off" ;
VAL_ 20 CF_Clu_ATTurnSet 3 "Invalid" 2 "Enable" 1 "Disable" 0 "Off" ;
VAL_ 20 CF_Clu_BuzzerSet 3 "Invalid" 2 "Enable" 1 "Disable" 0 "Off" ;
VAL_ 20 CF_Clu_EscortSet 3 "Invalid" 2 "Enable" 1 "Disable" 0 "Off" ;
VAL_ 20 CF_Clu_LigCurReq 3 "Invalid" 2 "Not used" 1 "Real value Request" 0 "Off" ;
VAL_ 20 CF_Clu_PsmCurReq 3 "Invalid" 2 "Not used" 1 "Real value Request" 0 "Off" ;
VAL_ 20 CF_Clu_ScmCurReq 3 "Invalid" 2 "Not used" 1 "Real value Request" 0 "Off" ;
VAL_ 20 CF_Clu_TurnUkSet 3 "Invalid" 2 "Enable" 1 "Disable" 0 "Off" ;
VAL_ 20 CF_Clu_DrLkCurReq 3 "Invalid" 2 "Not used" 1 "Real value Request" 0 "Off" ;
VAL_ 20 CF_Clu_DrUkCurReq 3 "Invalid" 2 "Not used" 1 "Real value Request" 0 "Off" ;
VAL_ 20 CF_Clu_TeleEngReq 3 "Invalid" 2 "Engine Off " 1 "Engine On " 0 "Default" ;
VAL_ 20 CF_Clu_ATTurnCurReq 3 "Invalid" 2 "Not used" 1 "Real value Request" 0 "Off" ;
VAL_ 20 CF_Clu_BuzzerCurReq 3 "Invalid" 2 "Not used" 1 "Real value Request" 0 "Off" ;
VAL_ 16 CF_Acu_CshAct 1 "Crash Active time started (Crash Detected)" 0 "Crash Active time is expired (Crash is Inactive)" ;
VAL_ 2 CF_Esp_FuncDem 64 "Reset" 32 "Keep quiet" 2 "Delete Error Memory (Attention : after an EEPROM write cycle a minimum pause of 2s for next read cycle is mandatory)" 1 "Ignition Counter" 0 "No request of specific function" ;
VAL_ 2 CF_Esp_DiagPtr 15 "Request cyclic pass through of text blocks" 10 "Request manufacturer process Index" 9 "Request part number" 8 "Request supplier name" 7 "Request supplier modification index" 6 "Request manufacturing date" 5 "Request sensor hardware version " 4 "Request sensor software identifier " 3 "Request sensor software version " 2 "Request vehicle modification index" 1 "Request supplier part number" 0 "Request customer part number " ;
